VERSION ""

NS_ :

BS_:

BU_:

BO_ 173 Message1099_PDU: 48 Vector__XXX
 SG_ Sig5671 : 7|32@0+ (1,0) [0|4.29497e+009] "" FCM
 SG_ Sig5670 : 39|5@0+ (1,0) [0|31] "" FCM
 SG_ Sig5772 : 45|11@0+ (1,0) [0|2047] "ms" FCM
 SG_ Sig5669 : 47|2@0+ (1,0) [0|3] "" FCM
 SG_ Sig5774 : 49|2@0+ (1,0) [0|3] "" FCM
 SG_ Sig5773 : 50|1@0+ (1,0) [0|1] "" FCM
 SG_ Sig5858 : 57|3@0+ (1,0) [0|4] "" FCM
 SG_ Sig5857 : 59|2@0+ (1,0) [0|3] "" FCM
 SG_ Sig5856 : 61|2@0+ (1,0) [0|2] "" FCM
 SG_ Sig5775 : 63|2@0+ (1,0) [0|2] "" FCM
 SG_ Sig5859 : 70|7@0+ (1,0) [0|127] "" FCM
 SG_ Sig5861 : 73|2@0+ (1,0) [0|3] "" FCM
 SG_ Sig5860 : 79|6@0+ (2,0) [0|126] "%" FCM
 SG_ Sig5862 : 87|9@0- (0.125,0) [-32|31.875] "m/s^2" FCM
 SG_ Sig5863 : 94|10@0- (0.125,0) [-64|63.875] "m" FCM
 SG_ Sig5864 : 100|9@0- (0.125,0) [-32|31.875] "m/s" FCM
 SG_ Sig5865 : 107|9@0- (0.125,0) [-32|31.875] "m/s^2" FCM
 SG_ Sig5866 : 114|11@0- (0.125,0) [-128|127.875] "m" FCM
 SG_ Sig5867 : 135|10@0- (0.125,0) [-64|63.875] "m/s" FCM
 SG_ Sig5870 : 137|2@0+ (1,0) [0|3] "" FCM
 SG_ Sig5869 : 139|2@0+ (1,0) [0|3] "" FCM
 SG_ Sig5868 : 141|2@0+ (1,0) [0|2] "" FCM
 SG_ Sig5872 : 148|7@0+ (1,0) [0|127] "" FCM
 SG_ Sig5871 : 151|3@0+ (1,0) [0|4] "" FCM
 SG_ Sig5873 : 157|6@0+ (2,0) [0|126] "%" FCM
 SG_ Sig5875 : 165|9@0- (0.125,0) [-32|31.875] "m/s^2" FCM
 SG_ Sig5874 : 167|2@0+ (1,0) [0|3] "" FCM
 SG_ Sig5876 : 172|10@0- (0.125,0) [-64|63.875] "m" FCM
 SG_ Sig5877 : 178|9@0- (0.125,0) [-32|31.875] "m/s" FCM
 SG_ Sig5878 : 185|9@0- (0.125,0) [-32|31.875] "m/s^2" FCM
 SG_ Sig5879 : 192|11@0- (0.125,0) [-128|127.875] "m" FCM
 SG_ Sig5880 : 213|10@0- (0.125,0) [-64|63.875] "m/s" FCM
 SG_ Sig5882 : 217|2@0+ (1,0) [0|3] "" FCM
 SG_ Sig5881 : 219|2@0+ (1,0) [0|2] "" FCM
 SG_ Sig5954 : 224|1@0+ (1,0) [0|1] "" FCM
 SG_ Sig5953 : 225|1@0+ (1,0) [0|1] "" FCM
 SG_ Sig5952 : 226|1@0+ (1,0) [0|1] "" FCM
 SG_ Sig5950 : 228|2@0+ (1,0) [0|3] "" FCM
 SG_ Sig5949 : 231|3@0+ (1,0) [0|5] "" FCM
 SG_ Sig5976 : 237|6@0+ (2,0) [0|126] "%" FCM
 SG_ Sig5955 : 239|2@0+ (1,0) [0|3] "" FCM
 SG_ Sig5980 : 241|7@0+ (1,0) [0|127] "" FCM
 SG_ Sig5979 : 242|1@0+ (1,0) [0|1] "" FCM
 SG_ Sig5978 : 245|3@0+ (1,0) [0|4] "" FCM
 SG_ Sig5977 : 247|2@0+ (1,0) [0|3] "" FCM
 SG_ Sig5984 : 248|9@0- (0.125,0) [-32|31.875] "m/s^2" FCM
 SG_ Sig5981 : 250|2@0+ (1,0) [0|3] "" FCM
 SG_ Sig5985 : 271|10@0- (0.125,0) [-64|63.875] "m" FCM
 SG_ Sig5986 : 277|14@0+ (0.01,0) [0|163.83] "m^2" FCM
 SG_ Sig5987 : 295|9@0- (0.125,0) [-32|31.875] "m/s" FCM
 SG_ Sig5988 : 302|10@0+ (0.125,0) [0|127.875] "(m/s)^2" FCM
 SG_ Sig5989 : 308|9@0- (0.125,0) [-32|31.875] "m/s^2" FCM
 SG_ Sig5990 : 315|11@0- (0.125,0) [-128|127.875] "m" FCM
 SG_ Sig5991 : 320|16@0+ (0.01,0) [0|655.35] "m^2" FCM
 SG_ Sig5992 : 336|11@0- (0.125,0) [-128|127.875] "m/s" FCM
 SG_ Sig5993 : 357|10@0+ (0.125,0) [0|127.875] "(m/s)^2" FCM
 SG_ Sig5994 : 363|8@0+ (0.125,0) [0|31.875] "m" FCM
 SG_ Sig6014 : 369|8@0+ (0.125,0) [0|31.875] "m" FCM
 SG_ Sig5995 : 371|2@0+ (1,0) [0|3] "" FCM
 SG_ Sig5668 : 377|2@0+ (1,0) [0|3] "" FCM

BO_ 166 Message1100_PDU: 48 Vector__XXX
 SG_ Sig5681 : 5|32@0+ (1,0) [0|4.29497e+009] "" FCM
 SG_ Sig5680 : 7|2@0+ (1,0) [0|3] "" FCM
 SG_ Sig5682 : 37|10@0+ (1,0) [0|1023] "" FCM
 SG_ Sig5780 : 43|10@0- (0.125,0) [-64|63.875] "m" FCM
 SG_ Sig5788 : 49|10@0- (0.125,0) [-64|63.875] "m" FCM
 SG_ Sig5796 : 71|10@0- (0.125,0) [-64|63.875] "m" FCM
 SG_ Sig5804 : 77|10@0- (0.125,0) [-64|63.875] "m" FCM
 SG_ Sig5812 : 83|10@0- (0.125,0) [-64|63.875] "m" FCM
 SG_ Sig5820 : 89|10@0- (0.125,0) [-64|63.875] "m" FCM
 SG_ Sig5828 : 111|10@0- (0.125,0) [-64|63.875] "m" FCM
 SG_ Sig5836 : 117|10@0- (0.125,0) [-64|63.875] "m" FCM
 SG_ Sig5844 : 123|10@0- (0.125,0) [-64|63.875] "m" FCM
 SG_ Sig5852 : 129|10@0- (0.125,0) [-64|63.875] "m" FCM
 SG_ Sig5923 : 149|16@0- (9.77e-07,0) [-0.0320143|0.0320134] "1/m" FCM
 SG_ Sig5922 : 151|2@0+ (1,0) [0|3] "" FCM
 SG_ Sig5924 : 165|16@0- (3.73e-09,0) [-0.000122225|0.000122221] "1/m2" FCM
 SG_ Sig5925 : 181|10@0- (0.000977,0) [-0.500224|0.499247] "rad" FCM
 SG_ Sig5926 : 187|9@0- (0.125,0) [-32|31.875] "m" FCM
 SG_ Sig5927 : 194|11@0- (0.125,0) [-128|127.875] "m" FCM
 SG_ Sig5928 : 215|11@0- (0.125,0) [-128|127.875] "m" FCM
 SG_ Sig5930 : 217|2@0+ (1,0) [0|3] "" FCM
 SG_ Sig5929 : 220|3@0+ (1,0) [0|5] "" FCM
 SG_ Sig5932 : 229|16@0- (9.77e-07,0) [-0.0320143|0.0320134] "1/m" FCM
 SG_ Sig5931 : 231|2@0+ (1,0) [0|3] "" FCM
 SG_ Sig5933 : 245|16@0- (3.73e-09,0) [-0.000122225|0.000122221] "1/m2" FCM
 SG_ Sig5934 : 261|10@0- (0.000977,0) [-0.500224|0.499247] "rad" FCM
 SG_ Sig5935 : 267|9@0- (0.125,0) [-32|31.875] "m" FCM
 SG_ Sig5936 : 274|11@0- (0.125,0) [-128|127.875] "m" FCM
 SG_ Sig5937 : 295|11@0- (0.125,0) [-128|127.875] "m" FCM
 SG_ Sig5939 : 297|2@0+ (1,0) [0|3] "" FCM
 SG_ Sig5938 : 300|3@0+ (1,0) [0|5] "" FCM
 SG_ Sig5941 : 309|16@0- (9.77e-07,0) [-0.0320143|0.0320134] "1/m" FCM
 SG_ Sig5940 : 311|2@0+ (1,0) [0|3] "" FCM
 SG_ Sig5942 : 325|16@0- (3.73e-09,0) [-0.000122225|0.000122221] "1/m2" FCM
 SG_ Sig5943 : 341|10@0- (0.000977,0) [-0.500224|0.499247] "rad" FCM
 SG_ Sig5944 : 347|9@0- (0.125,0) [-32|31.875] "m" FCM
 SG_ Sig5945 : 354|11@0- (0.125,0) [-128|127.875] "m" FCM
 SG_ Sig5946 : 375|11@0- (0.125,0) [-128|127.875] "m" FCM
 SG_ Sig5948 : 377|2@0+ (1,0) [0|3] "" FCM
 SG_ Sig5947 : 380|3@0+ (1,0) [0|5] "" FCM

BO_ 539 Message1101_PDU: 8 Vector__XXX
 SG_ Sig6851 : 7|64@0+ (1,0) [0|1.84467e+019] "" FCM

BO_ 163 Message1102_PDU: 64 Vector__XXX
 SG_ Sig5688 : 5|8@0+ (1,0) [0|255] "" FCM
 SG_ Sig5687 : 7|2@0+ (1,0) [0|3] "" FCM
 SG_ Sig6318 : 8|7@0+ (1,0) [0|127] "" FCM
 SG_ Sig6317 : 11|3@0+ (1,0) [0|4] "" FCM
 SG_ Sig6316 : 13|2@0+ (1,0) [0|3] "" FCM
 SG_ Sig6319 : 17|6@0+ (2,0) [0|126] "%" FCM
 SG_ Sig6321 : 25|9@0- (0.125,0) [-32|31.875] "m/s^2" FCM
 SG_ Sig6320 : 27|2@0+ (1,0) [0|3] "" FCM
 SG_ Sig6322 : 32|10@0- (0.125,0) [-64|63.875] "m" FCM
 SG_ Sig6323 : 54|9@0- (0.125,0) [-32|31.875] "m/s" FCM
 SG_ Sig6324 : 61|9@0- (0.125,0) [-32|31.875] "m/s^2" FCM
 SG_ Sig6325 : 68|11@0- (0.125,0) [-128|127.875] "m" FCM
 SG_ Sig6326 : 73|10@0- (0.125,0) [-64|63.875] "m/s" FCM
 SG_ Sig6467 : 91|6@0+ (2,0) [0|126] "%" FCM
 SG_ Sig6328 : 93|2@0+ (1,0) [0|3] "" FCM
 SG_ Sig6327 : 95|2@0+ (1,0) [0|2] "" FCM
 SG_ Sig6470 : 96|1@0+ (1,0) [0|1] "" FCM
 SG_ Sig6469 : 99|3@0+ (1,0) [0|4] "" FCM
 SG_ Sig6468 : 101|2@0+ (1,0) [0|3] "" FCM
 SG_ Sig6472 : 104|2@0+ (1,0) [0|3] "" FCM
 SG_ Sig6471 : 111|7@0+ (1,0) [0|127] "" FCM
 SG_ Sig6475 : 118|9@0- (0.125,0) [-32|31.875] "m/s^2" FCM
 SG_ Sig6476 : 125|10@0- (0.125,0) [-64|63.875] "m" FCM
 SG_ Sig6477 : 131|14@0+ (0.01,0) [0|163.83] "m^2" FCM
 SG_ Sig6478 : 149|9@0- (0.125,0) [-32|31.875] "m/s" FCM
 SG_ Sig6479 : 156|10@0+ (0.125,0) [0|127.875] "(m/s)^2" FCM
 SG_ Sig6480 : 162|9@0- (0.125,0) [-32|31.875] "m/s^2" FCM
 SG_ Sig6481 : 169|11@0- (0.125,0) [-128|127.875] "m" FCM
 SG_ Sig6482 : 190|16@0+ (0.01,0) [0|655.35] "m^2" FCM
 SG_ Sig6483 : 206|11@0- (0.125,0) [-128|127.875] "m/s" FCM
 SG_ Sig6484 : 211|10@0+ (0.125,0) [0|127.875] "(m/s)^2" FCM
 SG_ Sig6486 : 217|2@0+ (1,0) [0|3] "" FCM
 SG_ Sig6488 : 225|2@0+ (1,0) [0|3] "" FCM
 SG_ Sig6487 : 231|6@0+ (2,0) [0|126] "%" FCM
 SG_ Sig6491 : 235|7@0+ (1,0) [0|127] "" FCM
 SG_ Sig6490 : 236|1@0+ (1,0) [0|1] "" FCM
 SG_ Sig6489 : 239|3@0+ (1,0) [0|4] "" FCM
 SG_ Sig6495 : 242|9@0- (0.125,0) [-32|31.875] "m/s^2" FCM
 SG_ Sig6492 : 244|2@0+ (1,0) [0|3] "" FCM
 SG_ Sig6496 : 249|10@0- (0.125,0) [-64|63.875] "m" FCM
 SG_ Sig6497 : 271|14@0+ (0.01,0) [0|163.83] "m^2" FCM
 SG_ Sig6498 : 273|9@0- (0.125,0) [-32|31.875] "m/s" FCM
 SG_ Sig6499 : 280|10@0+ (0.125,0) [0|127.875] "(m/s)^2" FCM
 SG_ Sig6500 : 302|9@0- (0.125,0) [-32|31.875] "m/s^2" FCM
 SG_ Sig6501 : 309|11@0- (0.125,0) [-128|127.875] "m" FCM
 SG_ Sig6502 : 314|16@0+ (0.01,0) [0|655.35] "m^2" FCM
 SG_ Sig6503 : 330|11@0- (0.125,0) [-128|127.875] "m/s" FCM
 SG_ Sig6504 : 351|10@0+ (0.125,0) [0|127.875] "(m/s)^2" FCM
 SG_ Sig6505 : 357|8@0+ (0.125,0) [0|31.875] "m" FCM
 SG_ Sig6507 : 363|6@0+ (2,0) [0|126] "%" FCM
 SG_ Sig6506 : 365|2@0+ (1,0) [0|3] "" FCM
 SG_ Sig6510 : 368|1@0+ (1,0) [0|1] "" FCM
 SG_ Sig6509 : 371|3@0+ (1,0) [0|4] "" FCM
 SG_ Sig6508 : 373|2@0+ (1,0) [0|3] "" FCM
 SG_ Sig6512 : 376|2@0+ (1,0) [0|3] "" FCM
 SG_ Sig6511 : 383|7@0+ (1,0) [0|127] "" FCM
 SG_ Sig6515 : 390|9@0- (0.125,0) [-32|31.875] "m/s^2" FCM
 SG_ Sig6516 : 397|10@0- (0.125,0) [-64|63.875] "m" FCM
 SG_ Sig6517 : 403|14@0+ (0.01,0) [0|163.83] "m^2" FCM
 SG_ Sig6518 : 421|9@0- (0.125,0) [-32|31.875] "m/s" FCM
 SG_ Sig6519 : 428|10@0+ (0.125,0) [0|127.875] "(m/s)^2" FCM
 SG_ Sig6520 : 434|9@0- (0.125,0) [-32|31.875] "m/s^2" FCM
 SG_ Sig6521 : 441|11@0- (0.125,0) [-128|127.875] "m" FCM
 SG_ Sig6522 : 462|16@0+ (0.01,0) [0|655.35] "m^2" FCM
 SG_ Sig6523 : 478|11@0- (0.125,0) [-128|127.875] "m/s" FCM
 SG_ Sig6524 : 483|10@0+ (0.125,0) [0|127.875] "(m/s)^2" FCM
 SG_ Sig6525 : 489|8@0+ (0.125,0) [0|31.875] "m" FCM
 SG_ Sig6526 : 497|2@0+ (1,0) [0|3] "" FCM
 SG_ Sig6545 : 511|8@0+ (0.125,0) [0|31.875] "m" FCM

BO_ 161 Message1103_PDU: 64 Vector__XXX
 SG_ Sig5690 : 5|8@0+ (1,0) [0|255] "" FCM
 SG_ Sig5689 : 7|2@0+ (1,0) [0|3] "" FCM
 SG_ Sig6331 : 8|7@0+ (1,0) [0|127] "" FCM
 SG_ Sig6330 : 11|3@0+ (1,0) [0|4] "" FCM
 SG_ Sig6329 : 13|2@0+ (1,0) [0|3] "" FCM
 SG_ Sig6332 : 17|6@0+ (2,0) [0|126] "%" FCM
 SG_ Sig6334 : 25|9@0- (0.125,0) [-32|31.875] "m/s^2" FCM
 SG_ Sig6333 : 27|2@0+ (1,0) [0|3] "" FCM
 SG_ Sig6335 : 32|10@0- (0.125,0) [-64|63.875] "m" FCM
 SG_ Sig6336 : 54|9@0- (0.125,0) [-32|31.875] "m/s" FCM
 SG_ Sig6337 : 61|9@0- (0.125,0) [-32|31.875] "m/s^2" FCM
 SG_ Sig6338 : 68|11@0- (0.125,0) [-128|127.875] "m" FCM
 SG_ Sig6339 : 73|10@0- (0.125,0) [-64|63.875] "m/s" FCM
 SG_ Sig6527 : 91|6@0+ (2,0) [0|126] "%" FCM
 SG_ Sig6341 : 93|2@0+ (1,0) [0|3] "" FCM
 SG_ Sig6340 : 95|2@0+ (1,0) [0|2] "" FCM
 SG_ Sig6530 : 96|1@0+ (1,0) [0|1] "" FCM
 SG_ Sig6529 : 99|3@0+ (1,0) [0|4] "" FCM
 SG_ Sig6528 : 101|2@0+ (1,0) [0|3] "" FCM
 SG_ Sig6532 : 104|2@0+ (1,0) [0|3] "" FCM
 SG_ Sig6531 : 111|7@0+ (1,0) [0|127] "" FCM
 SG_ Sig6535 : 118|9@0- (0.125,0) [-32|31.875] "m/s^2" FCM
 SG_ Sig6536 : 125|10@0- (0.125,0) [-64|63.875] "m" FCM
 SG_ Sig6537 : 131|14@0+ (0.01,0) [0|163.83] "m^2" FCM
 SG_ Sig6538 : 149|9@0- (0.125,0) [-32|31.875] "m/s" FCM
 SG_ Sig6539 : 156|10@0+ (0.125,0) [0|127.875] "(m/s)^2" FCM
 SG_ Sig6540 : 162|9@0- (0.125,0) [-32|31.875] "m/s^2" FCM
 SG_ Sig6541 : 169|11@0- (0.125,0) [-128|127.875] "m" FCM
 SG_ Sig6542 : 190|16@0+ (0.01,0) [0|655.35] "m^2" FCM
 SG_ Sig6543 : 206|11@0- (0.125,0) [-128|127.875] "m/s" FCM
 SG_ Sig6544 : 211|10@0+ (0.125,0) [0|127.875] "(m/s)^2" FCM
 SG_ Sig6546 : 217|2@0+ (1,0) [0|3] "" FCM
 SG_ Sig6548 : 225|2@0+ (1,0) [0|3] "" FCM
 SG_ Sig6547 : 231|6@0+ (2,0) [0|126] "%" FCM
 SG_ Sig6551 : 235|7@0+ (1,0) [0|127] "" FCM
 SG_ Sig6550 : 236|1@0+ (1,0) [0|1] "" FCM
 SG_ Sig6549 : 239|3@0+ (1,0) [0|4] "" FCM
 SG_ Sig6555 : 242|9@0- (0.125,0) [-32|31.875] "m/s^2" FCM
 SG_ Sig6552 : 244|2@0+ (1,0) [0|3] "" FCM
 SG_ Sig6556 : 249|10@0- (0.125,0) [-64|63.875] "m" FCM
 SG_ Sig6557 : 271|14@0+ (0.01,0) [0|163.83] "m^2" FCM
 SG_ Sig6558 : 273|9@0- (0.125,0) [-32|31.875] "m/s" FCM
 SG_ Sig6559 : 280|10@0+ (0.125,0) [0|127.875] "(m/s)^2" FCM
 SG_ Sig6560 : 302|9@0- (0.125,0) [-32|31.875] "m/s^2" FCM
 SG_ Sig6561 : 309|11@0- (0.125,0) [-128|127.875] "m" FCM
 SG_ Sig6562 : 314|16@0+ (0.01,0) [0|655.35] "m^2" FCM
 SG_ Sig6563 : 330|11@0- (0.125,0) [-128|127.875] "m/s" FCM
 SG_ Sig6564 : 351|10@0+ (0.125,0) [0|127.875] "(m/s)^2" FCM
 SG_ Sig6565 : 357|8@0+ (0.125,0) [0|31.875] "m" FCM
 SG_ Sig6567 : 363|6@0+ (2,0) [0|126] "%" FCM
 SG_ Sig6566 : 365|2@0+ (1,0) [0|3] "" FCM
 SG_ Sig6570 : 368|1@0+ (1,0) [0|1] "" FCM
 SG_ Sig6569 : 371|3@0+ (1,0) [0|4] "" FCM
 SG_ Sig6568 : 373|2@0+ (1,0) [0|3] "" FCM
 SG_ Sig6572 : 376|2@0+ (1,0) [0|3] "" FCM
 SG_ Sig6571 : 383|7@0+ (1,0) [0|127] "" FCM
 SG_ Sig6575 : 390|9@0- (0.125,0) [-32|31.875] "m/s^2" FCM
 SG_ Sig6576 : 397|10@0- (0.125,0) [-64|63.875] "m" FCM
 SG_ Sig6577 : 403|14@0+ (0.01,0) [0|163.83] "m^2" FCM
 SG_ Sig6578 : 421|9@0- (0.125,0) [-32|31.875] "m/s" FCM
 SG_ Sig6579 : 428|10@0+ (0.125,0) [0|127.875] "(m/s)^2" FCM
 SG_ Sig6580 : 434|9@0- (0.125,0) [-32|31.875] "m/s^2" FCM
 SG_ Sig6581 : 441|11@0- (0.125,0) [-128|127.875] "m" FCM
 SG_ Sig6582 : 462|16@0+ (0.01,0) [0|655.35] "m^2" FCM
 SG_ Sig6583 : 478|11@0- (0.125,0) [-128|127.875] "m/s" FCM
 SG_ Sig6584 : 483|10@0+ (0.125,0) [0|127.875] "(m/s)^2" FCM
 SG_ Sig6585 : 489|8@0+ (0.125,0) [0|31.875] "m" FCM
 SG_ Sig6586 : 497|2@0+ (1,0) [0|3] "" FCM
 SG_ Sig6605 : 511|8@0+ (0.125,0) [0|31.875] "m" FCM

BO_ 160 Message1104_PDU: 64 Vector__XXX
 SG_ Sig5692 : 5|16@0+ (1,0) [0|65535] "" FCM
 SG_ Sig5691 : 7|2@0+ (1,0) [0|3] "" FCM
 SG_ Sig6344 : 16|7@0+ (1,0) [0|127] "" FCM
 SG_ Sig6343 : 19|3@0+ (1,0) [0|4] "" FCM
 SG_ Sig6342 : 21|2@0+ (1,0) [0|3] "" FCM
 SG_ Sig6345 : 25|6@0+ (2,0) [0|126] "%" FCM
 SG_ Sig6347 : 33|9@0- (0.125,0) [-32|31.875] "m/s^2" FCM
 SG_ Sig6346 : 35|2@0+ (1,0) [0|3] "" FCM
 SG_ Sig6348 : 40|10@0- (0.125,0) [-64|63.875] "m" FCM
 SG_ Sig6349 : 62|9@0- (0.125,0) [-32|31.875] "m/s" FCM
 SG_ Sig6350 : 69|9@0- (0.125,0) [-32|31.875] "m/s^2" FCM
 SG_ Sig6351 : 76|11@0- (0.125,0) [-128|127.875] "m" FCM
 SG_ Sig6352 : 81|10@0- (0.125,0) [-64|63.875] "m/s" FCM
 SG_ Sig6427 : 99|6@0+ (2,0) [0|126] "%" FCM
 SG_ Sig6354 : 101|2@0+ (1,0) [0|3] "" FCM
 SG_ Sig6353 : 103|2@0+ (1,0) [0|2] "" FCM
 SG_ Sig6430 : 104|1@0+ (1,0) [0|1] "" FCM
 SG_ Sig6429 : 107|3@0+ (1,0) [0|4] "" FCM
 SG_ Sig6428 : 109|2@0+ (1,0) [0|3] "" FCM
 SG_ Sig6432 : 112|2@0+ (1,0) [0|3] "" FCM
 SG_ Sig6431 : 119|7@0+ (1,0) [0|127] "" FCM
 SG_ Sig6435 : 126|9@0- (0.125,0) [-32|31.875] "m/s^2" FCM
 SG_ Sig6436 : 133|10@0- (0.125,0) [-64|63.875] "m" FCM
 SG_ Sig6437 : 139|14@0+ (0.01,0) [0|163.83] "m^2" FCM
 SG_ Sig6438 : 157|9@0- (0.125,0) [-32|31.875] "m/s" FCM
 SG_ Sig6439 : 164|10@0+ (0.125,0) [0|127.875] "(m/s)^2" FCM
 SG_ Sig6440 : 170|9@0- (0.125,0) [-32|31.875] "m/s^2" FCM
 SG_ Sig6441 : 177|11@0- (0.125,0) [-128|127.875] "m" FCM
 SG_ Sig6442 : 198|16@0+ (0.01,0) [0|655.35] "m^2" FCM
 SG_ Sig6443 : 214|11@0- (0.125,0) [-128|127.875] "m/s" FCM
 SG_ Sig6444 : 219|10@0+ (0.125,0) [0|127.875] "(m/s)^2" FCM
 SG_ Sig6445 : 225|8@0+ (0.125,0) [0|31.875] "m" FCM
 SG_ Sig6446 : 233|2@0+ (1,0) [0|3] "" FCM
 SG_ Sig6588 : 241|2@0+ (1,0) [0|3] "" FCM
 SG_ Sig6587 : 247|6@0+ (2,0) [0|126] "%" FCM
 SG_ Sig6591 : 251|7@0+ (1,0) [0|127] "" FCM
 SG_ Sig6590 : 252|1@0+ (1,0) [0|1] "" FCM
 SG_ Sig6589 : 255|3@0+ (1,0) [0|4] "" FCM
 SG_ Sig6595 : 258|9@0- (0.125,0) [-32|31.875] "m/s^2" FCM
 SG_ Sig6592 : 260|2@0+ (1,0) [0|3] "" FCM
 SG_ Sig6596 : 265|10@0- (0.125,0) [-64|63.875] "m" FCM
 SG_ Sig6597 : 287|14@0+ (0.01,0) [0|163.83] "m^2" FCM
 SG_ Sig6598 : 289|9@0- (0.125,0) [-32|31.875] "m/s" FCM
 SG_ Sig6599 : 296|10@0+ (0.125,0) [0|127.875] "(m/s)^2" FCM
 SG_ Sig6600 : 318|9@0- (0.125,0) [-32|31.875] "m/s^2" FCM
 SG_ Sig6601 : 325|11@0- (0.125,0) [-128|127.875] "m" FCM
 SG_ Sig6602 : 330|16@0+ (0.01,0) [0|655.35] "m^2" FCM
 SG_ Sig6603 : 346|11@0- (0.125,0) [-128|127.875] "m/s" FCM
 SG_ Sig6604 : 367|10@0+ (0.125,0) [0|127.875] "(m/s)^2" FCM
 SG_ Sig6607 : 371|6@0+ (2,0) [0|126] "%" FCM
 SG_ Sig6606 : 373|2@0+ (1,0) [0|3] "" FCM
 SG_ Sig6610 : 376|1@0+ (1,0) [0|1] "" FCM
 SG_ Sig6609 : 379|3@0+ (1,0) [0|4] "" FCM
 SG_ Sig6608 : 381|2@0+ (1,0) [0|3] "" FCM
 SG_ Sig6612 : 384|2@0+ (1,0) [0|3] "" FCM
 SG_ Sig6611 : 391|7@0+ (1,0) [0|127] "" FCM
 SG_ Sig6615 : 398|9@0- (0.125,0) [-32|31.875] "m/s^2" FCM
 SG_ Sig6616 : 405|10@0- (0.125,0) [-64|63.875] "m" FCM
 SG_ Sig6617 : 411|14@0+ (0.01,0) [0|163.83] "m^2" FCM
 SG_ Sig6618 : 429|9@0- (0.125,0) [-32|31.875] "m/s" FCM
 SG_ Sig6619 : 436|10@0+ (0.125,0) [0|127.875] "(m/s)^2" FCM
 SG_ Sig6620 : 442|9@0- (0.125,0) [-32|31.875] "m/s^2" FCM
 SG_ Sig6621 : 449|11@0- (0.125,0) [-128|127.875] "m" FCM
 SG_ Sig6622 : 470|16@0+ (0.01,0) [0|655.35] "m^2" FCM
 SG_ Sig6623 : 486|11@0- (0.125,0) [-128|127.875] "m/s" FCM
 SG_ Sig6624 : 491|10@0+ (0.125,0) [0|127.875] "(m/s)^2" FCM
 SG_ Sig6625 : 497|8@0+ (0.125,0) [0|31.875] "m" FCM
 SG_ Sig6626 : 505|2@0+ (1,0) [0|3] "" FCM

BO_ 159 Message1105_PDU: 64 Vector__XXX
 SG_ Sig5694 : 5|10@0+ (1,0) [0|1023] "" FCM
 SG_ Sig5693 : 7|2@0+ (1,0) [0|3] "" FCM
 SG_ Sig6206 : 9|2@0+ (1,0) [0|3] "" FCM
 SG_ Sig6205 : 11|2@0+ (1,0) [0|3] "" FCM
 SG_ Sig6208 : 16|2@0+ (1,0) [0|3] "" FCM
 SG_ Sig6207 : 23|7@0+ (1,0) [0|127] "" FCM
 SG_ Sig6210 : 30|11@0- (0.125,0) [-128|127.875] "m" FCM
 SG_ Sig6212 : 32|2@0+ (1,0) [0|3] "" FCM
 SG_ Sig6211 : 35|3@0+ (1,0) [0|5] "" FCM
 SG_ Sig6215 : 42|7@0+ (1,0) [0|127] "" FCM
 SG_ Sig6214 : 44|2@0+ (1,0) [0|3] "" FCM
 SG_ Sig6213 : 46|2@0+ (1,0) [0|3] "" FCM
 SG_ Sig6218 : 49|11@0- (0.125,0) [-128|127.875] "m" FCM
 SG_ Sig6216 : 51|2@0+ (1,0) [0|3] "" FCM
 SG_ Sig6221 : 65|2@0+ (1,0) [0|3] "" FCM
 SG_ Sig6220 : 67|2@0+ (1,0) [0|3] "" FCM
 SG_ Sig6219 : 70|3@0+ (1,0) [0|5] "" FCM
 SG_ Sig6223 : 77|7@0+ (1,0) [0|127] "" FCM
 SG_ Sig6222 : 79|2@0+ (1,0) [0|3] "" FCM
 SG_ Sig6226 : 84|11@0- (0.125,0) [-128|127.875] "m" FCM
 SG_ Sig6224 : 86|2@0+ (1,0) [0|3] "" FCM
 SG_ Sig6227 : 89|3@0+ (1,0) [0|5] "" FCM
 SG_ Sig6231 : 96|7@0+ (1,0) [0|127] "" FCM
 SG_ Sig6230 : 98|2@0+ (1,0) [0|3] "" FCM
 SG_ Sig6229 : 100|2@0+ (1,0) [0|3] "" FCM
 SG_ Sig6228 : 102|2@0+ (1,0) [0|3] "" FCM
 SG_ Sig6232 : 105|2@0+ (1,0) [0|3] "" FCM
 SG_ Sig6234 : 119|11@0- (0.125,0) [-128|127.875] "m" FCM
 SG_ Sig6236 : 121|2@0+ (1,0) [0|3] "" FCM
 SG_ Sig6235 : 124|3@0+ (1,0) [0|5] "" FCM
 SG_ Sig6239 : 131|7@0+ (1,0) [0|127] "" FCM
 SG_ Sig6238 : 133|2@0+ (1,0) [0|3] "" FCM
 SG_ Sig6237 : 135|2@0+ (1,0) [0|3] "" FCM
 SG_ Sig6242 : 138|11@0- (0.125,0) [-128|127.875] "m" FCM
 SG_ Sig6240 : 140|2@0+ (1,0) [0|3] "" FCM
 SG_ Sig6246 : 152|2@0+ (1,0) [0|3] "" FCM
 SG_ Sig6245 : 154|2@0+ (1,0) [0|3] "" FCM
 SG_ Sig6244 : 156|2@0+ (1,0) [0|3] "" FCM
 SG_ Sig6243 : 159|3@0+ (1,0) [0|5] "" FCM
 SG_ Sig6247 : 166|7@0+ (1,0) [0|127] "" FCM
 SG_ Sig6250 : 173|11@0- (0.125,0) [-128|127.875] "m" FCM
 SG_ Sig6248 : 175|2@0+ (1,0) [0|3] "" FCM
 SG_ Sig6251 : 178|3@0+ (1,0) [0|5] "" FCM
 SG_ Sig6255 : 185|7@0+ (1,0) [0|127] "" FCM
 SG_ Sig6254 : 187|2@0+ (1,0) [0|3] "" FCM
 SG_ Sig6253 : 189|2@0+ (1,0) [0|3] "" FCM
 SG_ Sig6252 : 191|2@0+ (1,0) [0|3] "" FCM
 SG_ Sig6258 : 192|11@0- (0.125,0) [-128|127.875] "m" FCM
 SG_ Sig6256 : 194|2@0+ (1,0) [0|3] "" FCM
 SG_ Sig6261 : 208|2@0+ (1,0) [0|3] "" FCM
 SG_ Sig6260 : 210|2@0+ (1,0) [0|3] "" FCM
 SG_ Sig6259 : 213|3@0+ (1,0) [0|5] "" FCM
 SG_ Sig6263 : 220|7@0+ (1,0) [0|127] "" FCM
 SG_ Sig6262 : 222|2@0+ (1,0) [0|3] "" FCM
 SG_ Sig6266 : 227|11@0- (0.125,0) [-128|127.875] "m" FCM
 SG_ Sig6264 : 229|2@0+ (1,0) [0|3] "" FCM
 SG_ Sig6267 : 232|3@0+ (1,0) [0|5] "" FCM
 SG_ Sig6270 : 241|2@0+ (1,0) [0|3] "" FCM
 SG_ Sig6269 : 243|2@0+ (1,0) [0|3] "" FCM
 SG_ Sig6268 : 245|2@0+ (1,0) [0|3] "" FCM
 SG_ Sig6272 : 248|2@0+ (1,0) [0|3] "" FCM
 SG_ Sig6271 : 255|7@0+ (1,0) [0|127] "" FCM
 SG_ Sig6274 : 262|11@0- (0.125,0) [-128|127.875] "m" FCM
 SG_ Sig6276 : 264|2@0+ (1,0) [0|3] "" FCM
 SG_ Sig6275 : 267|3@0+ (1,0) [0|5] "" FCM
 SG_ Sig6279 : 274|7@0+ (1,0) [0|127] "" FCM
 SG_ Sig6278 : 276|2@0+ (1,0) [0|3] "" FCM
 SG_ Sig6277 : 278|2@0+ (1,0) [0|3] "" FCM
 SG_ Sig6282 : 281|11@0- (0.125,0) [-128|127.875] "m" FCM
 SG_ Sig6280 : 283|2@0+ (1,0) [0|3] "" FCM
 SG_ Sig6433 : 297|10@0- (0.125,0) [-64|63.875] "m" FCM
 SG_ Sig6284 : 299|2@0+ (1,0) [0|3] "" FCM
 SG_ Sig6283 : 302|3@0+ (1,0) [0|5] "" FCM
 SG_ Sig6434 : 319|11@0- (0.125,0) [-128|127.875] "m" FCM
 SG_ Sig6453 : 324|10@0- (0.125,0) [-64|63.875] "m" FCM
 SG_ Sig6454 : 330|11@0- (0.125,0) [-128|127.875] "m" FCM
 SG_ Sig6473 : 351|10@0- (0.125,0) [-64|63.875] "m" FCM
 SG_ Sig6474 : 357|11@0- (0.125,0) [-128|127.875] "m" FCM
 SG_ Sig6493 : 362|10@0- (0.125,0) [-64|63.875] "m" FCM
 SG_ Sig6494 : 368|11@0- (0.125,0) [-128|127.875] "m" FCM
 SG_ Sig6513 : 389|10@0- (0.125,0) [-64|63.875] "m" FCM
 SG_ Sig6514 : 395|11@0- (0.125,0) [-128|127.875] "m" FCM
 SG_ Sig6533 : 400|10@0- (0.125,0) [-64|63.875] "m" FCM
 SG_ Sig6534 : 422|11@0- (0.125,0) [-128|127.875] "m" FCM
 SG_ Sig6553 : 427|10@0- (0.125,0) [-64|63.875] "m" FCM
 SG_ Sig6554 : 433|11@0- (0.125,0) [-128|127.875] "m" FCM
 SG_ Sig6573 : 454|10@0- (0.125,0) [-64|63.875] "m" FCM
 SG_ Sig6574 : 460|11@0- (0.125,0) [-128|127.875] "m" FCM
 SG_ Sig6593 : 465|10@0- (0.125,0) [-64|63.875] "m" FCM
 SG_ Sig6594 : 487|11@0- (0.125,0) [-128|127.875] "m" FCM
 SG_ Sig6613 : 492|10@0- (0.125,0) [-64|63.875] "m" FCM
 SG_ Sig6614 : 498|11@0- (0.125,0) [-128|127.875] "m" FCM

BO_ 165 Message1106_PDU: 48 Vector__XXX
 SG_ Sig5686 : 7|32@0+ (1,0) [0|4.29497e+009] "" FCM
 SG_ Sig5685 : 39|5@0+ (1,0) [0|31] "" FCM
 SG_ Sig6200 : 45|11@0+ (1,0) [0|2047] "ms" FCM
 SG_ Sig5684 : 47|2@0+ (1,0) [0|3] "" FCM
 SG_ Sig6202 : 49|2@0+ (1,0) [0|3] "" FCM
 SG_ Sig6201 : 50|1@0+ (1,0) [0|1] "" FCM
 SG_ Sig6291 : 57|3@0+ (1,0) [0|4] "" FCM
 SG_ Sig6290 : 59|2@0+ (1,0) [0|3] "" FCM
 SG_ Sig6285 : 61|2@0+ (1,0) [0|2] "" FCM
 SG_ Sig6203 : 63|2@0+ (1,0) [0|2] "" FCM
 SG_ Sig6292 : 70|7@0+ (1,0) [0|127] "" FCM
 SG_ Sig6294 : 73|2@0+ (1,0) [0|3] "" FCM
 SG_ Sig6293 : 79|6@0+ (2,0) [0|126] "%" FCM
 SG_ Sig6295 : 87|9@0- (0.125,0) [-32|31.875] "m/s^2" FCM
 SG_ Sig6296 : 94|10@0- (0.125,0) [-64|63.875] "m" FCM
 SG_ Sig6297 : 100|9@0- (0.125,0) [-32|31.875] "m/s" FCM
 SG_ Sig6298 : 107|9@0- (0.125,0) [-32|31.875] "m/s^2" FCM
 SG_ Sig6299 : 114|11@0- (0.125,0) [-128|127.875] "m" FCM
 SG_ Sig6300 : 135|10@0- (0.125,0) [-64|63.875] "m/s" FCM
 SG_ Sig6303 : 137|2@0+ (1,0) [0|3] "" FCM
 SG_ Sig6302 : 139|2@0+ (1,0) [0|3] "" FCM
 SG_ Sig6301 : 141|2@0+ (1,0) [0|2] "" FCM
 SG_ Sig6305 : 148|7@0+ (1,0) [0|127] "" FCM
 SG_ Sig6304 : 151|3@0+ (1,0) [0|4] "" FCM
 SG_ Sig6306 : 157|6@0+ (2,0) [0|126] "%" FCM
 SG_ Sig6308 : 165|9@0- (0.125,0) [-32|31.875] "m/s^2" FCM
 SG_ Sig6307 : 167|2@0+ (1,0) [0|3] "" FCM
 SG_ Sig6309 : 172|10@0- (0.125,0) [-64|63.875] "m" FCM
 SG_ Sig6310 : 178|9@0- (0.125,0) [-32|31.875] "m/s" FCM
 SG_ Sig6311 : 185|9@0- (0.125,0) [-32|31.875] "m/s^2" FCM
 SG_ Sig6312 : 192|11@0- (0.125,0) [-128|127.875] "m" FCM
 SG_ Sig6313 : 213|10@0- (0.125,0) [-64|63.875] "m/s" FCM
 SG_ Sig6315 : 217|2@0+ (1,0) [0|3] "" FCM
 SG_ Sig6314 : 219|2@0+ (1,0) [0|2] "" FCM
 SG_ Sig6387 : 224|1@0+ (1,0) [0|1] "" FCM
 SG_ Sig6386 : 225|1@0+ (1,0) [0|1] "" FCM
 SG_ Sig6385 : 226|1@0+ (1,0) [0|1] "" FCM
 SG_ Sig6383 : 228|2@0+ (1,0) [0|3] "" FCM
 SG_ Sig6382 : 231|3@0+ (1,0) [0|5] "" FCM
 SG_ Sig6447 : 237|6@0+ (2,0) [0|126] "%" FCM
 SG_ Sig6388 : 239|2@0+ (1,0) [0|3] "" FCM
 SG_ Sig6451 : 241|7@0+ (1,0) [0|127] "" FCM
 SG_ Sig6450 : 242|1@0+ (1,0) [0|1] "" FCM
 SG_ Sig6449 : 245|3@0+ (1,0) [0|4] "" FCM
 SG_ Sig6448 : 247|2@0+ (1,0) [0|3] "" FCM
 SG_ Sig6455 : 248|9@0- (0.125,0) [-32|31.875] "m/s^2" FCM
 SG_ Sig6452 : 250|2@0+ (1,0) [0|3] "" FCM
 SG_ Sig6456 : 271|10@0- (0.125,0) [-64|63.875] "m" FCM
 SG_ Sig6457 : 277|14@0+ (0.01,0) [0|163.83] "m^2" FCM
 SG_ Sig6458 : 295|9@0- (0.125,0) [-32|31.875] "m/s" FCM
 SG_ Sig6459 : 302|10@0+ (0.125,0) [0|127.875] "(m/s)^2" FCM
 SG_ Sig6460 : 308|9@0- (0.125,0) [-32|31.875] "m/s^2" FCM
 SG_ Sig6461 : 315|11@0- (0.125,0) [-128|127.875] "m" FCM
 SG_ Sig6462 : 320|16@0+ (0.01,0) [0|655.35] "m^2" FCM
 SG_ Sig6463 : 336|11@0- (0.125,0) [-128|127.875] "m/s" FCM
 SG_ Sig6464 : 357|10@0+ (0.125,0) [0|127.875] "(m/s)^2" FCM
 SG_ Sig6465 : 363|8@0+ (0.125,0) [0|31.875] "m" FCM
 SG_ Sig6485 : 369|8@0+ (0.125,0) [0|31.875] "m" FCM
 SG_ Sig6466 : 371|2@0+ (1,0) [0|3] "" FCM
 SG_ Sig5683 : 377|2@0+ (1,0) [0|3] "" FCM

BO_ 158 Message1107_PDU: 48 Vector__XXX
 SG_ Sig5696 : 5|32@0+ (1,0) [0|4.29497e+009] "" FCM
 SG_ Sig5695 : 7|2@0+ (1,0) [0|3] "" FCM
 SG_ Sig5697 : 37|10@0+ (1,0) [0|1023] "" FCM
 SG_ Sig6209 : 43|10@0- (0.125,0) [-64|63.875] "m" FCM
 SG_ Sig6217 : 49|10@0- (0.125,0) [-64|63.875] "m" FCM
 SG_ Sig6225 : 71|10@0- (0.125,0) [-64|63.875] "m" FCM
 SG_ Sig6233 : 77|10@0- (0.125,0) [-64|63.875] "m" FCM
 SG_ Sig6241 : 83|10@0- (0.125,0) [-64|63.875] "m" FCM
 SG_ Sig6249 : 89|10@0- (0.125,0) [-64|63.875] "m" FCM
 SG_ Sig6257 : 111|10@0- (0.125,0) [-64|63.875] "m" FCM
 SG_ Sig6265 : 117|10@0- (0.125,0) [-64|63.875] "m" FCM
 SG_ Sig6273 : 123|10@0- (0.125,0) [-64|63.875] "m" FCM
 SG_ Sig6281 : 129|10@0- (0.125,0) [-64|63.875] "m" FCM
 SG_ Sig6356 : 149|16@0- (9.77e-07,0) [-0.0320143|0.0320134] "1/m" FCM
 SG_ Sig6355 : 151|2@0+ (1,0) [0|3] "" FCM
 SG_ Sig6357 : 165|16@0- (3.73e-09,0) [-0.000122225|0.000122221] "1/m2" FCM
 SG_ Sig6358 : 181|10@0- (0.000977,0) [-0.500224|0.499247] "rad" FCM
 SG_ Sig6359 : 187|9@0- (0.125,0) [-32|31.875] "m" FCM
 SG_ Sig6360 : 194|11@0- (0.125,0) [-128|127.875] "m" FCM
 SG_ Sig6361 : 215|11@0- (0.125,0) [-128|127.875] "m" FCM
 SG_ Sig6363 : 217|2@0+ (1,0) [0|3] "" FCM
 SG_ Sig6362 : 220|3@0+ (1,0) [0|5] "" FCM
 SG_ Sig6365 : 229|16@0- (9.77e-07,0) [-0.0320143|0.0320134] "1/m" FCM
 SG_ Sig6364 : 231|2@0+ (1,0) [0|3] "" FCM
 SG_ Sig6366 : 245|16@0- (3.73e-09,0) [-0.000122225|0.000122221] "1/m2" FCM
 SG_ Sig6367 : 261|10@0- (0.000977,0) [-0.500224|0.499247] "rad" FCM
 SG_ Sig6368 : 267|9@0- (0.125,0) [-32|31.875] "m" FCM
 SG_ Sig6369 : 274|11@0- (0.125,0) [-128|127.875] "m" FCM
 SG_ Sig6370 : 295|11@0- (0.125,0) [-128|127.875] "m" FCM
 SG_ Sig6372 : 297|2@0+ (1,0) [0|3] "" FCM
 SG_ Sig6371 : 300|3@0+ (1,0) [0|5] "" FCM
 SG_ Sig6374 : 309|16@0- (9.77e-07,0) [-0.0320143|0.0320134] "1/m" FCM
 SG_ Sig6373 : 311|2@0+ (1,0) [0|3] "" FCM
 SG_ Sig6375 : 325|16@0- (3.73e-09,0) [-0.000122225|0.000122221] "1/m2" FCM
 SG_ Sig6376 : 341|10@0- (0.000977,0) [-0.500224|0.499247] "rad" FCM
 SG_ Sig6377 : 347|9@0- (0.125,0) [-32|31.875] "m" FCM
 SG_ Sig6378 : 354|11@0- (0.125,0) [-128|127.875] "m" FCM
 SG_ Sig6379 : 375|11@0- (0.125,0) [-128|127.875] "m" FCM
 SG_ Sig6381 : 377|2@0+ (1,0) [0|3] "" FCM
 SG_ Sig6380 : 380|3@0+ (1,0) [0|5] "" FCM

BO_ 908 SrlDat18_PCSM_PDU: 8 Vector__XXX
 SG_ SrlDat18_PCSM : 7|64@0+ (1,0) [0|1.84467e+019] "" ACP2_MCU,AHL_AFL,EBCM,EOCM,EOCM_HC_Superset,FCM,RDCM,TCCM,TCM

BO_ 100 SrlDat18_Prtctd_PDU: 20 Vector__XXX
 SG_ SD18P_MAC : 7|32@0+ (1,0) [0|4.29497e+009] "" ACP2_MCU,AHL_AFL,CGM,EBCM,EOCM,EOCM_HC_Superset,FCM,RDCM,TCCM,TCM
 SG_ SD18P_FCnt : 39|5@0+ (1,0) [0|31] "" ACP2_MCU,AHL_AFL,CGM,EBCM,EOCM,EOCM_HC_Superset,FCM,RDCM,TCCM,TCM
 SG_ EGI5P_ECDIntlRngSnsrPWAuth : 45|8@0+ (0.392157,0) [0|100] "%" ACP2_MCU,AHL_AFL,CGM,EBCM,EOCM,EOCM_HC_Superset,FCM,RDCM,TCCM,TCM,ECP_X1
 SG_ EGI1P_PtclFiltClnAlgActAuth_DuD : 46|1@0+ (1,0) [0|1] "" ACP2_MCU,AHL_AFL,BSM,CGM,EBCM,EOCM,EOCM_HC_Superset,FCM,RDCM,TCCM,TCM
 SG_ EGI1P_PtclFiltClnAlgActAuth : 47|1@0+ (1,0) [0|1] "" ACP2_MCU,AHL_AFL,BSM,CGM,EBCM,EOCM,EOCM_HC_Superset,FCM,RDCM,TCCM,TCM
 SG_ EGIP_CrksftNTransRegCmdTqAuth : 51|12@0+ (0.5,-848) [-848|1199.5] "Nm" ACP2_MCU,AHL_AFL,CGM,EBCM,EOCM,EOCM_HC_Superset,FCM,RDCM,TCCM,TCM,ECP_X1
 SG_ EGI5P_EngStlSvrActvAuth : 52|1@0+ (1,0) [0|1] "" ACP2_MCU,AHL_AFL,CGM,EBCM,EOCM,EOCM_HC_Superset,FCM,RDCM,TCCM,TCM,ECP_X1
 SG_ EGI5P_ECDIntlRngSnsrPWAuth_Inv : 53|1@0+ (1,0) [0|1] "" ACP2_MCU,AHL_AFL,CGM,EBCM,EOCM,EOCM_HC_Superset,FCM,RDCM,TCCM,TCM,ECP_X1
 SG_ EGIP_DrvrIntndCrksftTrqMinAuth : 71|12@0+ (0.5,-848) [-848|1199.5] "Nm" ACP2_MCU,AHL_AFL,CGM,EBCM,EOCM,EOCM_HC_Superset,FCM,RDCM,TCCM,TCM,ECP_X1
 SG_ EGIP_DrvrIntndCrksftTrqRwAuth : 75|12@0+ (0.5,-848) [-848|1199.5] "Nm" ACP2_MCU,AHL_AFL,CGM,EBCM,EOCM,EOCM_HC_Superset,FCM,RDCM,TCCM,TCM,ECP_X1
 SG_ EGIP_EngActlStdyStatTrqAuth : 95|12@0+ (0.5,-848) [-848|1199.5] "Nm" ACP2_MCU,AHL_AFL,BSM,CGM,DCM,EBCM,EOCM,EOCM_HC_Superset,FCM,RDCM,TCCM,TCM,ECP_X1
 SG_ EGIP_EngNTransRegSSTrqAuth : 98|12@0+ (0.5,-848) [-848|1199.5] "nm" ACP2_MCU,AHL_AFL,CGM,EBCM,EOCM,EOCM_HC_Superset,FCM,RDCM,TCCM,TCM,ECP_X1
 SG_ EGIP_EngActlStdyStatTrqAuth_Inv : 99|1@0+ (1,0) [0|1] "" ACP2_MCU,AHL_AFL,BSM,CGM,DCM,EBCM,EOCM,EOCM_HC_Superset,FCM,RDCM,TCCM,TCM,ECP_X1
 SG_ ESP_EngSpdAuth : 117|16@0+ (0.25,0) [0|16383.8] "rpm" ACP2_MCU,AHL_AFL,AHS,BSM,VICM,CGM,DCM,EBCM,EOCM,EOCM_HC_Superset,EPS,EPSb,FCM,PCM,RDCM,TCCM,TCM,ECP_X1
 SG_ EGIP_EngNTransRegSSTrqAuth_Inv : 118|1@0+ (1,0) [0|1] "" ACP2_MCU,AHL_AFL,CGM,EBCM,EOCM,EOCM_HC_Superset,FCM,RDCM,TCCM,TCM,ECP_X1
 SG_ SD18P_ARC : 129|2@0+ (1,0) [0|3] "" ACP2_MCU,AHL_AFL,BSM,CGM,EBCM,EOCM,EOCM_HC_Superset,FCM,RDCM,TCCM,TCM
 SG_ E44BRP_HillDscntCtlSwStsAuth : 131|2@0+ (1,0) [0|3] "" ACP2_MCU,AHL_AFL,BSM,CGM,EBCM,EOCM,EOCM_HC_Superset,FCM,RDCM,TCCM,TCM
 SG_ ESP_EngSpdStAuth : 133|2@0+ (1,0) [0|2] "" ACP2_MCU,AHL_AFL,BSM,VICM,CGM,DCM,EBCM,EOCM,EOCM_HC_Superset,FCM,RDCM,TCCM,TCM
 SG_ EngNonTransRegSSTrqER : 141|12@0+ (1,-848) [-848|3247] "Nm" ACP2_MCU,AHL_AFL,CGM,EBCM,EOCM,EOCM_HC_Superset,FCM,RDCM,TCCM,TCM
 SG_ E49RmtEngStrtReqAuth : 142|1@0+ (1,0) [0|1] "" ACP2_MCU,AHL_AFL,CGM,EBCM,EOCM,EOCM_HC_Superset,FCM,RDCM,TCCM,TCM
 SG_ E49RmtEngShtdnReqdAuth : 143|1@0+ (1,0) [0|1] "" ACP2_MCU,AHL_AFL,CGM,EBCM,EOCM,EOCM_HC_Superset,FCM,RDCM,TCCM,TCM
 SG_ SD18P_Filler : 144|9@0+ (1,0) [0|511] "" ACP2_MCU,AHL_AFL,CGM,EBCM,EOCM,EOCM_HC_Superset,FCM,RDCM,TCCM,TCM
 SG_ EngNonTransRegSSTrqER_Inv : 145|1@0+ (1,0) [0|1] "" ACP2_MCU,AHL_AFL,CGM,EBCM,EOCM,EOCM_HC_Superset,FCM,RDCM,TCCM,TCM

BO_ 978 SrlDat195_PCSM_PDU: 8 Vector__XXX
 SG_ SrlDat195_PCSM : 7|64@0+ (1,0) [0|1.84467e+019] "" ACP2_MCU

BO_ 157 SrlDat195_Prtctd_PDU: 12 Vector__XXX
 SG_ SD195P_MAC : 7|32@0+ (1,0) [0|4.29497e+009] "" ACP2_MCU
 SG_ SD195P_FCnt : 39|5@0+ (1,0) [0|31] "" ACP2_MCU
 SG_ DMSDrvrDrwLvlPrd : 47|14@0+ (0.05,0) [0|819.15] "sec" ACP2_MCU,FCM
 SG_ DMSDrvrPctgOfEyeClsrPrd : 49|14@0+ (0.05,0) [0|819.15] "sec" ACP2_MCU,FCM
 SG_ DMSDrvrPctgOfEyeClsr : 67|7@0+ (1,0) [0|127] "%" ACP2_MCU,FCM
 SG_ DMSDrvrDrwLvlCnfdLvl : 72|3@0+ (1,0) [0|7] "" ACP2_MCU,FCM
 SG_ DMSDrvrDrwLvl : 76|4@0+ (1,0) [0|9] "" ACP2_MCU,FCM
 SG_ SD195P_Filler : 85|12@0+ (1,0) [0|4095] "" ACP2_MCU
 SG_ SD195P_ARC : 89|2@0+ (1,0) [0|3] "" ACP2_MCU

BO_ 1139 Message1109_PDU: 8 Vector__XXX
 SG_ Sig6852 : 7|64@0+ (1,0) [0|1.84467e+019] "" DMS

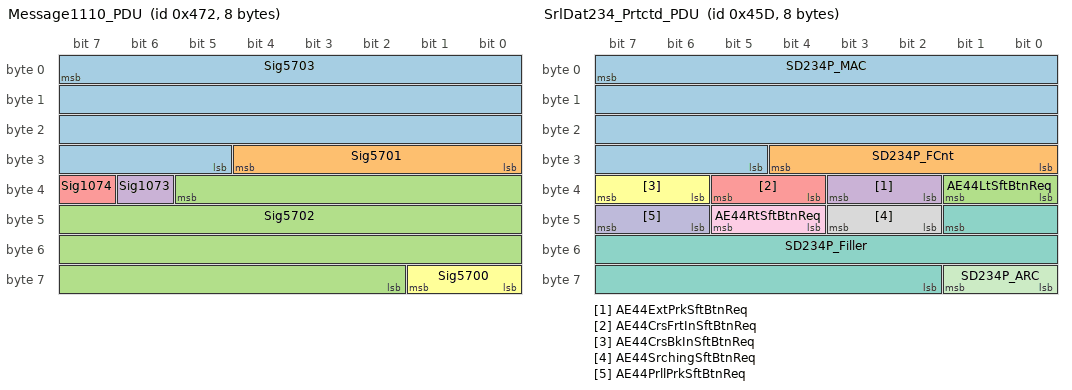
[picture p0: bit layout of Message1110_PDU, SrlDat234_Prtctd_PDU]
BO_ 1138 Message1110_PDU: 8 Vector__XXX
 SG_ Sig5703 : 7|27@0+ (1,0) [0|1.34218e+008] "" DMS
 SG_ Sig5701 : 28|5@0+ (1,0) [0|31] "" DMS
 SG_ Sig5702 : 37|28@0+ (1,0) [0|2.68435e+008] "" DMS
 SG_ Sig1073 : 38|1@0+ (1,0) [0|1] "" DMS
 SG_ Sig1074 : 39|1@0+ (1,0) [0|1] "" DMS
 SG_ Sig5700 : 57|2@0+ (1,0) [0|3] "" DMS

BO_ 907 SrlDat19_PCSM_PDU: 8 Vector__XXX
 SG_ SrlDat19_PCSM : 7|64@0+ (1,0) [0|1.84467e+019] "" ACP2_MCU,ADIMa,ADIMb,BSM,EBCM,EOCM,EOCM_HC_Superset,FCM,PCM,RDCM,TCCM,TCM,ECP_X1

BO_ 47 SrlDat19_Prtctd_PDU: 32 Vector__XXX
 SG_ SD19P_MAC : 7|32@0+ (1,0) [0|4.29497e+009] "" ACP2_MCU,ADIMa,ADIMb,BSM,CGM,EBCM,EOCM,EOCM_HC_Superset,FCM,PCM,RDCM,TCCM,TCM,ECP_X1
 SG_ SD19P_FCnt : 39|5@0+ (1,0) [0|31] "" ACP2_MCU,ADIMa,ADIMb,BSM,CGM,EBCM,EOCM,EOCM_HC_Superset,FCM,PCM,RDCM,TCCM,TCM,ECP_X1
 SG_ AATP_ActAxlTrqAuth : 47|15@0+ (2,-22534) [-22534|43000] "Nm" ACP2_MCU,ADIMa,ADIMb,BSM,VICM,CGM,DCM,EBCM,EOCM,EOCM_HC_Superset,EPS,EPSb,FCM,PCM,RDCM,TCCM,TCM,ECP_X1
 SG_ AATP_ActAxlTrqAuth_Inv : 48|1@0+ (1,0) [0|1] "" ACP2_MCU,ADIMa,ADIMb,BSM,VICM,CGM,DCM,EBCM,EOCM,EOCM_HC_Superset,EPS,EPSb,FCM,PCM,RDCM,TCCM,TCM,ECP_X1
 SG_ AEPP_AccEffcPosAuth : 63|8@0+ (0.392157,0) [0|100] "%" ACP2_MCU,ADIMa,ADIMb,BSM,CGM,EBCM,EOCM,EOCM_HC_Superset,FCM,PCM,RDCM,TCCM,TCM,ECP_X1
 SG_ DRCDNDP_DRCAvgDrvnAuth : 70|13@0+ (0.125,0) [0|1023.88] "m" ACP2_MCU,ADIMa,ADIMb,BSM,VECM,VICM,BSM_MH,CGM,EBCM,ECP_MC,EOCM,EOCM_HC_Superset,FCM,PCM,RDCM,TCCM,TCM,ECP_S,ECP_S2,ECP_X1
 SG_ AEPP_AccEffcPosAuth_Inv : 71|1@0+ (1,0) [0|1] "" ACP2_MCU,ADIMa,ADIMb,BSM,CGM,EBCM,EOCM,EOCM_HC_Superset,FCM,PCM,RDCM,TCCM,TCM,ECP_X1
 SG_ DRCDNDP_DRCAvgDrvnRstOccAuth : 72|1@0+ (1,0) [0|1] "" ACP2_MCU,ADIMa,ADIMb,BSM,VECM,VICM,BSM_MH,CGM,EBCM,ECP_MC,EOCM,EOCM_HC_Superset,FCM,PCM,RDCM,TCCM,TCM,ECP_S,ECP_S2,ECP_X1
 SG_ DRCDNDP_DRCAvgDrvnAuth_Inv : 73|1@0+ (1,0) [0|1] "" ACP2_MCU,ADIMa,ADIMb,BSM,VECM,VICM,BSM_MH,CGM,EBCM,ECP_MC,EOCM,EOCM_HC_Superset,FCM,PCM,RDCM,TCCM,TCM,ECP_S,ECP_S2,ECP_X1
 SG_ DRCDNDP_DRCAvgNonDrvnAuth : 86|13@0+ (0.125,0) [0|1023.88] "m" ACP2_MCU,ADIMa,ADIMb,BSM,CGM,EBCM,EOCM,EOCM_HC_Superset,FCM,PCM,RDCM,TCCM,TCM,ECP_X1
 SG_ DRCDNDP_DRCAvgDrvnSrcAuth : 87|1@0+ (1,0) [0|1] "" ACP2_MCU,ADIMa,ADIMb,BSM,VECM,VICM,BSM_MH,CGM,EBCM,ECP_MC,EOCM,EOCM_HC_Superset,FCM,PCM,RDCM,TCCM,TCM,ECP_S,ECP_S2,ECP_X1
 SG_ DRCDNDP_DRCAvgNonDrvnRstOccAuth : 88|1@0+ (1,0) [0|1] "" ACP2_MCU,ADIMa,ADIMb,BSM,CGM,EBCM,EOCM,EOCM_HC_Superset,FCM,PCM,RDCM,TCCM,TCM,ECP_X1
 SG_ DRCDNDP_DRCAvgNonDrvnAuth_Inv : 89|1@0+ (1,0) [0|1] "" ACP2_MCU,ADIMa,ADIMb,BSM,CGM,EBCM,EOCM,EOCM_HC_Superset,FCM,PCM,RDCM,TCCM,TCM,ECP_X1
 SG_ E44BRP_PTAutoBrkgAccelReqAuth : 102|12@0- (0.01,0) [-20.48|20.47] "" ACP2_MCU,ADIMa,ADIMb,BSM,CGM,EBCM,EOCM,EOCM_HC_Superset,FCM,PCM,RDCM,TCCM,TCM,ECP_X1
 SG_ DRCDNDP_PwrtrnRunAbrtdAuth : 103|1@0+ (1,0) [0|1] "" ACP2_MCU,ADIMa,ADIMb,BSM,CGM,EBCM,EOCM,EOCM_HC_Superset,FCM,PCM,RDCM,TCCM,TCM,ECP_X1
 SG_ PBP_PTSndBrkPdlPsAuth : 105|8@0+ (0.392157,0) [0|100] "%" ACP2_MCU,ADIMa,ADIMb,BSM,CGM,EBCM,EOCM,EOCM_HC_Superset,FCM,PCM,RDCM,TCCM,TCM,ECP_X1
 SG_ E44BRP_PTAutoBrkgReqActvAuth : 106|1@0+ (1,0) [0|1] "" ACP2_MCU,ADIMa,ADIMb,BSM,CGM,EBCM,EOCM,EOCM_HC_Superset,FCM,PCM,RDCM,TCCM,TCM,ECP_X1
 SG_ PSATDP_ATDstTrqCmdSecAuth : 112|15@0+ (2,-22534) [-22534|43000] "Nm" ACP2_MCU,ADIMa,ADIMb,BSM,CGM,EBCM,EOCM,EOCM_HC_Superset,FCM,PCM,RDCM,TCCM,TCM,ECP_X1
 SG_ PBP_PTSndBrkPdlPsAuth_Inv : 113|1@0+ (1,0) [0|1] "" ACP2_MCU,ADIMa,ADIMb,BSM,CGM,EBCM,EOCM,EOCM_HC_Superset,FCM,PCM,RDCM,TCCM,TCM,ECP_X1
 SG_ PSATIP_ATDstTqCmdPriImmAuth : 128|15@0+ (2,-22534) [-22534|43000] "Nm" ACP2_MCU,ADIMa,ADIMb,BSM,CGM,EBCM,EOCM,EOCM_HC_Superset,FCM,PCM,RDCM,TCCM,TCM,ECP_X1
 SG_ PSATDP_ATDstTrqCmdSecAuth_Inv : 129|1@0+ (1,0) [0|1] "" ACP2_MCU,ADIMa,ADIMb,BSM,CGM,EBCM,EOCM,EOCM_HC_Superset,FCM,PCM,RDCM,TCCM,TCM,ECP_X1
 SG_ PSATIP_CmndATImmedAuth : 144|15@0+ (2,-22534) [-22534|43000] "Nm" ACP2_MCU,ADIMa,ADIMb,BSM,CGM,EBCM,EOCM,EOCM_HC_Superset,FCM,PCM,RDCM,TCCM,TCM,ECP_X1
 SG_ PSATIP_ATDstTqCmdPriImmAuth_Inv : 145|1@0+ (1,0) [0|1] "" ACP2_MCU,ADIMa,ADIMb,BSM,CGM,EBCM,EOCM,EOCM_HC_Superset,FCM,PCM,RDCM,TCCM,TCM,ECP_X1
 SG_ PSATIP_CmndATPrdtdAuth : 161|15@0+ (2,-22534) [-22534|43000] "Nm" ACP2_MCU,ADIMa,ADIMb,BSM,CGM,EBCM,EOCM,EOCM_HC_Superset,FCM,PCM,RDCM,TCCM,TCM,ECP_X1
 SG_ PSATIP_PriATActlAuth : 176|15@0+ (2,-22534) [-22534|43000] "Nm" ACP2_MCU,ADIMa,ADIMb,BSM,CGM,EBCM,EOCM,EOCM_HC_Superset,EPS,EPSb,FCM,PCM,RDCM,TCCM,TCM,ECP_X1
 SG_ PSATIP_CmndATRespTypAuth : 178|2@0+ (1,0) [0|3] "" ACP2_MCU,ADIMa,ADIMb,BSM,CGM,EBCM,EOCM,EOCM_HC_Superset,FCM,PCM,RDCM,TCCM,TCM,ECP_X1
 SG_ PSATIP_PriATCmdImmedAuth : 192|15@0+ (2,-22534) [-22534|43000] "Nm" ACP2_MCU,ADIMa,ADIMb,BSM,CGM,EBCM,EOCM,EOCM_HC_Superset,FCM,PCM,RDCM,TCCM,TCM,ECP_X1
 SG_ PSATIP_PriATActlAuth_Inv : 193|1@0+ (1,0) [0|1] "" ACP2_MCU,ADIMa,ADIMb,BSM,CGM,EBCM,EOCM,EOCM_HC_Superset,EPS,EPSb,FCM,PCM,RDCM,TCCM,TCM,ECP_X1
 SG_ PSATIP_PriATReqStsAdvdTracAuth : 209|3@0+ (1,0) [0|6] "" ACP2_MCU,ADIMa,ADIMb,BSM,CGM,EBCM,EOCM,EOCM_HC_Superset,FCM,PCM,RDCM,TCCM,TCM,ECP_X1
 SG_ SD19P_FillerExtnd : 222|12@0+ (1,0) [0|4095] "" ACP2_MCU,ADIMa,ADIMb,BSM,CGM,EBCM,EOCM,EOCM_HC_Superset,FCM,PCM,RDCM,TCCM,TCM,ECP_X1
 SG_ PSATDP_SecATReqStsAdvdTracAuth : 226|3@0+ (1,0) [0|6] "" ACP2_MCU,ADIMa,ADIMb,BSM,CGM,EBCM,EOCM,EOCM_HC_Superset,FCM,RDCM,TCCM,TCM,ECP_X1
 SG_ PSATIP_SecATCmdImmedAuth : 237|19@0- (0.25,0) [-65536|65535.8] "Nm" ACP2_MCU,ADIMa,ADIMb,BSM,CGM,EBCM,EOCM,EOCM_HC_Superset,FCM,PCM,RDCM,TCCM,TCM,ECP_X1
 SG_ SD19P_ARC : 239|2@0+ (1,0) [0|3] "" ACP2_MCU,ADIMa,ADIMb,BSM,CGM,EBCM,EOCM,EOCM_HC_Superset,FCM,PCM,RDCM,TCCM,TCM,ECP_X1
 SG_ SD19P_Filler : 250|3@0+ (1,0) [0|7] "" ACP2_MCU,ADIMa,ADIMb,BSM,CGM,EBCM,EOCM,EOCM_HC_Superset,FCM,PCM,RDCM,TCCM,TCM,ECP_X1

BO_ 906 SrlDat20_PCSM_PDU: 8 Vector__XXX
 SG_ SrlDat20_PCSM : 7|64@0+ (1,0) [0|1.84467e+019] "" ACP2_MCU,ADIMa,ADIMb,EBCM,EOCM,EOCM_HC_Superset,FCM,PCM,RDCM,TCCM,TCM

BO_ 226 SrlDat20_Prtctd_PDU: 20 Vector__XXX
 SG_ SD20P_MAC : 7|32@0+ (1,0) [0|4.29497e+009] "" ACP2_MCU,ADIMa,ADIMb,CGM,EBCM,EOCM,EOCM_HC_Superset,FCM,PCM,RDCM,TCCM,TCM
 SG_ SD20P_FCnt : 39|5@0+ (1,0) [0|31] "" ACP2_MCU,ADIMa,ADIMb,CGM,EBCM,EOCM,EOCM_HC_Superset,FCM,PCM,RDCM,TCCM,TCM
 SG_ DIATMNP_DrvrIntdAxlTqMnAuth : 47|15@0+ (2,-22534) [-22534|43000] "Nm" ACP2_MCU,ADIMa,ADIMb,CGM,EBCM,EOCM,EOCM_HC_Superset,FCM,PCM,RDCM,TCCM,TCM
 SG_ DIATMNP_DrvrIntdAxlTqMnAuth_Inv : 48|1@0+ (1,0) [0|1] "" ACP2_MCU,ADIMa,ADIMb,CGM,EBCM,EOCM,EOCM_HC_Superset,FCM,PCM,RDCM,TCCM,TCM
 SG_ DIATMXP_DrvrIntdAxlTqMxAuth : 63|15@0+ (2,-22534) [-22534|43000] "Nm" ACP2_MCU,ADIMa,ADIMb,CGM,EBCM,EOCM,EOCM_HC_Superset,FCM,PCM,RDCM,TCCM,TCM
 SG_ DIATMXP_DrvrIntdAxlTqMxAuth_Inv : 64|1@0+ (1,0) [0|1] "" ACP2_MCU,ADIMa,ADIMb,CGM,EBCM,EOCM,EOCM_HC_Superset,FCM,PCM,RDCM,TCCM,TCM
 SG_ DITP_DrvrIntndAxlTrqAuth : 79|15@0+ (2,-22534) [-22534|43000] "Nm" ACP2_MCU,ADIMa,ADIMb,BSM,VICM,CGM,DCM,EBCM,EOCM,EOCM_HC_Superset,FCM,PCM,RDCM,TCCM,TCM
 SG_ DITP_DrvrIntndAxlTrqAuth_Inv : 80|1@0+ (1,0) [0|1] "" ACP2_MCU,ADIMa,ADIMb,BSM,VICM,CGM,DCM,EBCM,EOCM,EOCM_HC_Superset,FCM,PCM,RDCM,TCCM,TCM
 SG_ DITP_DrvrIntndCrksftTrqAuth : 95|12@0+ (0.5,-848) [-848|1199.5] "Nm" ACP2_MCU,ADIMa,ADIMb,CGM,EBCM,EOCM,EOCM_HC_Superset,FCM,PCM,RDCM,TCCM,TCM
 SG_ VMI1P_AccelActlPstnAuth : 99|8@0+ (0.392157,0) [0|100] "%" ACP2_MCU,ADIMa,ADIMb,AHL_AFL,BSM,VICM,CGM,EBCM,EOCM,EOCM_HC_Superset,FCM,PCM,RDCM,TCCM,TCM,VDM,ECP_X1
 SG_ VMI1P_VehTopSpdLimArbdValAuth : 105|8@0+ (2,0) [0|510] "km / h" ACP2_MCU,ADIMa,ADIMb,CGM,EBCM,EOCM,EOCM_HC_Superset,FCM,PCM,RDCM,TCCM,TCM
 SG_ VMI1P_AccelPedOvrrdActvAuth : 106|1@0+ (1,0) [0|1] "" ACP2_MCU,ADIMa,ADIMb,CGM,EBCM,EOCM,EOCM_HC_Superset,FCM,PCM,RDCM,TCCM,TCM
 SG_ VMI1P_AccelActlPstnAuth_Inv : 107|1@0+ (1,0) [0|1] "" ACP2_MCU,ADIMa,ADIMb,AHL_AFL,BSM,VICM,CGM,EBCM,EOCM,EOCM_HC_Superset,FCM,PCM,RDCM,TCCM,TCM,VDM,ECP_X1
 SG_ SD20P_ARC : 112|2@0+ (1,0) [0|3] "" ACP2_MCU,ADIMa,ADIMb,CGM,EBCM,EOCM,EOCM_HC_Superset,FCM,PCM,RDCM,TCCM,TCM
 SG_ VMI1P_VehTopSpdLimModeActvAuth : 113|1@0+ (1,0) [0|1] "" ACP2_MCU,ADIMa,ADIMb,CGM,EBCM,EOCM,EOCM_HC_Superset,FCM,PCM,RDCM,TCCM,TCM
 SG_ SD20P_Filler : 126|32@0+ (1,0) [0|4.29497e+009] "" ACP2_MCU,ADIMa,ADIMb,CGM,EBCM,EOCM,EOCM_HC_Superset,FCM,PCM,RDCM,TCCM,TCM
 SG_ SD20P_FillerExtnd : 158|7@0+ (1,0) [0|127] "" ACP2_MCU,ADIMa,ADIMb,CGM,EBCM,EOCM,EOCM_HC_Superset,FCM,PCM,RDCM,TCCM,TCM

BO_ 905 SrlDat21_PCSM_PDU: 8 Vector__XXX
 SG_ SrlDat21_PCSM : 7|64@0+ (1,0) [0|1.84467e+019] "" ACP2_MCU,BSM,VICM,EOCM,EOCM_HC_Superset,FCM

BO_ 615 SrlDat21_Prtctd_PDU: 20 Vector__XXX
 SG_ SD21P_MAC : 7|32@0+ (1,0) [0|4.29497e+009] "" ACP2_MCU,BSM,VICM,CGM,EOCM,EOCM_HC_Superset,FCM
 SG_ SD21P_FCnt : 39|5@0+ (1,0) [0|31] "" ACP2_MCU,BSM,VICM,CGM,EOCM,EOCM_HC_Superset,FCM
 SG_ BVSCRP_BdyCtlTpSpdLimRspTypAuth : 42|3@0+ (1,0) [0|6] "" ACP2_MCU,BSM,VICM,CGM,EOCM,EOCM_HC_Superset,FCM
 SG_ BVSCRP_ACCAxlTrqCmdReqStsAuth : 45|3@0+ (1,0) [0|4] "" ACP2_MCU,BSM,VICM,CGM,EOCM,EOCM_HC_Superset,FCM,RDCM
 SG_ BVSCRP_ACCAxlTrqCmdLimStsAuth : 47|2@0+ (1,0) [0|3] "" ACP2_MCU,BSM,VICM,CGM,EOCM,EOCM_HC_Superset,FCM,RDCM
 SG_ BVSCRP_BdyCtlTpSpdLimRspValAuth : 55|8@0+ (2,0) [0|510] "kph" ACP2_MCU,BSM,VICM,CGM,EOCM,EOCM_HC_Superset,FCM
 SG_ BVSCRP_CltchPdlActPosAuth : 58|8@0+ (0.392157,0) [0|100] "" ACP2_MCU,BSM,VICM,CGM,EBCM,EOCM,EOCM_HC_Superset,FCM
 SG_ BVSCRP_CPSAxlTrqCmdReqStsAuth : 61|3@0+ (1,0) [0|6] "" ACP2_MCU,BSM,VICM,CGM,EOCM,EOCM_HC_Superset,FCM,RDCM
 SG_ BVSCRP_CPSAxlTrqCmdLimStsAuth : 63|2@0+ (1,0) [0|3] "" ACP2_MCU,BSM,VICM,CGM,EOCM,EOCM_HC_Superset,FCM,RDCM
 SG_ CnvntlCruzCtlIndReqAuth : 64|3@0+ (1,0) [0|5] "" ACP2_MCU,BSM,VICM,CGM,EOCM,EOCM_HC_Superset,FCM
 SG_ BVSCRP_CruzCtlEnbldAuth : 65|1@0+ (1,0) [0|1] "" ACP2_MCU,BSM,VICM,CGM,EBCM,EOCM,EOCM_HC_Superset,FCM
 SG_ BVSCRP_CltchPdlActPosAuth_Inv : 66|1@0+ (1,0) [0|1] "" ACP2_MCU,BSM,VICM,CGM,EBCM,EOCM,EOCM_HC_Superset,FCM
 SG_ CruzSpdLmtrDrvrSeltdSpdAuth : 76|12@0+ (0.0625,0) [0|255.938] "km / h" ACP2_MCU,BSM,VICM,CGM,EOCM,EOCM_HC_Superset,FCM,PCM,TCM
 SG_ CruzCtlActvAuth : 77|1@0+ (1,0) [0|1] "" ACP2_MCU,BSM,VICM,CGM,EBCM,EOCM,EOCM_HC_Superset,FCM,PCM,TCM
 SG_ DrSeltdSpdLmtrAutoMdSpLmStsAuth : 80|2@0+ (1,0) [0|3] "" ACP2_MCU,BSM,VICM,CGM,EOCM,EOCM_HC_Superset,FCM
 SG_ EGI2P_DrvrReqdAxlTrqValAuth : 89|15@0+ (2,-22534) [-22534|43000] "Nm" ACP2_MCU,BSM,VICM,CGM,EOCM,EOCM_HC_Superset,FCM
 SG_ EGI2P_DrvrReqdAxlTrqIncrAuth : 90|1@0+ (1,0) [0|1] "" ACP2_MCU,BSM,VICM,CGM,EOCM,EOCM_HC_Superset,FCM
 SG_ DrSeltdSpdLmtrSetTypActvAuth : 92|2@0+ (1,0) [0|3] "" ACP2_MCU,BSM,VICM,CGM,EOCM,EOCM_HC_Superset,FCM
 SG_ DrSeltdSpdLmtrSetSpdLimRchdAuth : 94|2@0+ (1,0) [0|3] "" ACP2_MCU,BSM,VICM,CGM,EOCM,EOCM_HC_Superset,FCM
 SG_ E44BRP_VehTopSpdLimArbdStatAuth : 104|2@0+ (1,0) [0|2] "" ACP2_MCU,BSM,VICM,CGM,EBCM,EOCM,EOCM_HC_Superset,FCM
 SG_ EGI2P_PwrtrnCrnkActvAuth : 105|1@0+ (1,0) [0|1] "" ACP2_MCU,BSM,VICM,CGM,EOCM,EOCM_HC_Superset,FCM,PCM,TCM,ECP_X1
 SG_ EGI2P_DrvrReqdAxlTrqValAuth_Inv : 106|1@0+ (1,0) [0|1] "" ACP2_MCU,BSM,VICM,CGM,EOCM,EOCM_HC_Superset,FCM
 SG_ SpdLmtrSpdLimSgnValAuth : 117|8@0+ (1,0) [0|255] "" ACP2_MCU,BSM,VICM,CGM,EOCM,EOCM_HC_Superset,FCM
 SG_ SpdLmtrSpdLimSgnUntAuth : 118|1@0+ (1,0) [0|1] "" ACP2_MCU,BSM,VICM,CGM,EOCM,EOCM_HC_Superset,FCM
 SG_ SD21P_Filler : 121|32@0+ (1,0) [0|4.29497e+009] "" ACP2_MCU,BSM,VICM,CGM,EOCM,EOCM_HC_Superset,FCM
 SG_ SuprRmtPrkPrplSysResp : 123|2@0+ (1,0) [0|3] "" ACP2_MCU,BSM,VICM,CGM,EOCM,EOCM_HC_Superset,FCM
 SG_ SD21P_ARC : 125|2@0+ (1,0) [0|3] "" ACP2_MCU,BSM,VICM,CGM,EOCM,EOCM_HC_Superset,FCM
 SG_ SD21P_FillerExtnd : 153|2@0+ (1,0) [0|3] "" ACP2_MCU,BSM,VICM,CGM,EOCM,EOCM_HC_Superset,FCM

BO_ 1404 SrlDat22_PCSM_PDU: 8 Vector__XXX
 SG_ SrlDat22_PCSM : 7|64@0+ (1,0) [0|1.84467e+019] "" ACP2_MCU,AHL_AFL,AHS,ARS,BSM,VICM,BSM_MH,CGM,DCM,ECP_MC,EOCM,EOCM_HC_Superset,EPSRAa,EPS,EPSb,FCM,FOPM,PCM,RDCM,TCCM,TCM,ECP_X1

BO_ 879 SrlDat22_Prtctd_PDU: 8 Vector__XXX
 SG_ SD22P_MAC : 7|27@0+ (1,0) [0|1.34218e+008] "" ACP2_MCU,AHL_AFL,AHS,ARS,BSM,VICM,BSM_MH,CGM,DCM,ECP_MC,EOCM,EOCM_HC_Superset,EPSRAa,EPS,EPSb,FCM,FOPM,PCM,RDCM,TCCM,TCM,ECP_X1
 SG_ SD22P_FCnt : 28|5@0+ (1,0) [0|31] "" ACP2_MCU,AHL_AFL,AHS,ARS,BSM,VICM,BSM_MH,CGM,DCM,ECP_MC,EOCM,EOCM_HC_Superset,EPSRAa,EPS,EPSb,FCM,FOPM,PCM,RDCM,TCCM,TCM,ECP_X1
 SG_ EGI3P_CnvtTpSpLimRspValAuth : 36|8@0+ (2,0) [0|510] "kph" ACP2_MCU,AHL_AFL,AHS,ARS,BSM,VICM,BSM_MH,CGM,DCM,ECP_MC,EOCM,EOCM_HC_Superset,EPSRAa,EPS,EPSb,FCM,FOPM,PCM,RDCM,TCCM,TCM,ECP_X1
 SG_ EGI3P_CnvtTpSpLimRspTypAuth : 39|3@0+ (1,0) [0|6] "" ACP2_MCU,AHL_AFL,AHS,ARS,BSM,VICM,BSM_MH,CGM,DCM,ECP_MC,EOCM,EOCM_HC_Superset,EPSRAa,EPS,EPSb,FCM,FOPM,PCM,RDCM,TCCM,TCM,ECP_X1
 SG_ PSP_PrkNeutSwStatAuth_Inv : 40|1@0+ (1,0) [0|1] "" ACP2_MCU,AHL_AFL,AHS,ARS,BSM,VICM,BSM_MH,CGM,DCM,ECP_MC,EOCM,EOCM_HC_Superset,EPSRAa,EPS,EPSb,FCM,FOPM,PCM,RDCM,TCCM,TCM,ECP_X1
 SG_ PSP_PrkNeutSwStatAuth : 41|1@0+ (1,0) [0|1] "" ACP2_MCU,AHL_AFL,AHS,ARS,BSM,VICM,BSM_MH,CGM,DCM,ECP_MC,EOCM,EOCM_HC_Superset,EPSRAa,EPS,EPSb,FCM,FOPM,PCM,RDCM,TCCM,TCM,ECP_X1
 SG_ PSP_EngRnngAuth : 42|1@0+ (1,0) [0|1] "" ACP2_MCU,AHL_AFL,AHS,ARS,BSM,VICM,BSM_MH,CGM,DCM,DMS,ECP_MC,EOCM,EOCM_HC_Superset,EPSRAa,EPS,EPSb,FCM,FOPM,HUD_CAN,LIB1,NVM,E44,PCM,RDCM,TCCM,TCM,ECP_S,ECP_X1
 SG_ PSP_ClchBtmTrvlAchvdAuth_Inv : 43|1@0+ (1,0) [0|1] "" ACP2_MCU,AHL_AFL,AHS,ARS,BSM,VICM,BSM_MH,CGM,DCM,ECP_MC,EOCM,EOCM_HC_Superset,EPSRAa,EPS,EPSb,FCM,FOPM,PCM,RDCM,TCCM,TCM,ECP_X1
 SG_ PSP_ClchBtmTrvlAchvdAuth : 44|1@0+ (1,0) [0|1] "" ACP2_MCU,AHL_AFL,AHS,ARS,BSM,VICM,BSM_MH,CGM,DCM,ECP_MC,EOCM,EOCM_HC_Superset,EPSRAa,EPS,EPSb,FCM,FOPM,PCM,RDCM,TCCM,TCM,ECP_X1
 SG_ SD22P_ARC : 49|2@0+ (1,0) [0|3] "" ACP2_MCU,AHL_AFL,AHS,ARS,BSM,VICM,BSM_MH,CGM,DCM,ECP_MC,EOCM,EOCM_HC_Superset,EPSRAa,EPS,EPSb,FCM,FOPM,PCM,RDCM,TCCM,TCM,ECP_X1
 SG_ PSP_VehTheftImbChlgRespStsAuth : 51|2@0+ (1,0) [0|2] "" ACP2_MCU,AHL_AFL,AHS,ARS,BSM,VICM,BSM_MH,CGM,DCM,ECP_MC,EOCM,EOCM_HC_Superset,EPSRAa,EPS,EPSb,FCM,FOPM,PCM,RDCM,TCCM,TCM,ECP_X1
 SG_ PSP_RmtVehStrtEngRnngAuth : 52|1@0+ (1,0) [0|1] "" ACP2_MCU,AHL_AFL,AHS,ARS,BSM,VICM,BSM_MH,CGM,DCM,ECP_MC,EOCM,EOCM_HC_Superset,EPSRAa,EPS,EPSb,FCM,FOPM,PCM,RDCM,TCCM,TCM,ECP_X1
 SG_ PSP_PwrtrnCrnkAbrtdAuth : 53|1@0+ (1,0) [0|1] "" ACP2_MCU,AHL_AFL,AHS,ARS,BSM,VICM,BSM_MH,CGM,DCM,ECP_MC,EOCM,EOCM_HC_Superset,EPSRAa,EPS,EPSb,FCM,FOPM,PCM,RDCM,TCCM,TCM,ECP_X1
 SG_ PSP_PrplSysStlActvAuth : 54|1@0+ (1,0) [0|1] "" ACP2_MCU,AHL_AFL,AHS,ARS,BSM,VICM,BSM_MH,CGM,DCM,ECP_MC,EOCM,EOCM_HC_Superset,EPSRAa,EPS,EPSb,FCM,FOPM,PCM,RDCM,TCCM,TCM,ECP_X1
 SG_ PSP_PrplSysActvAuth : 55|1@0+ (1,0) [0|1] "" ACP2_MCU,ADIMa,ADIMb,AHL_AFL,AHS,ARS,BSM,VECM,VICM,BSM_MH,CGM,DCM,EBCM,ECP_MC,EOCM,EOCM_HC_Superset,EPSRAa,EPS,EPSb,FCM,FOPM,HUD_CAN,LIB1,NVM,E44,PCM,RDCM,TCCM,TCM,VDM,ECP_S,ECP_S2,ECP_X1
 SG_ SD22P_Filler : 62|7@0+ (1,0) [0|127] "" ACP2_MCU,AHL_AFL,AHS,ARS,BSM,VICM,BSM_MH,CGM,DCM,ECP_MC,EOCM,EOCM_HC_Superset,EPSRAa,EPS,EPSb,FCM,FOPM,PCM,RDCM,TCCM,TCM,ECP_X1
 SG_ PrplBrkThrotOvrrdReqd : 63|1@0+ (1,0) [0|1] "" ACP2_MCU,AHL_AFL,AHS,ARS,BSM,VICM,BSM_MH,CGM,DCM,ECP_MC,EOCM,EOCM_HC_Superset,EPSRAa,EPS,EPSb,FCM,FOPM,PCM,RDCM,TCCM,TCM,ECP_X1

BO_ 1949 SrlDat234_PCSM_PDU: 8 Vector__XXX
 SG_ SrlDat234_PCSM : 7|64@0+ (1,0) [0|1.84467e+019] "" Vector__XXX

BO_ 1117 SrlDat234_Prtctd_PDU: 8 Vector__XXX
 SG_ SD234P_MAC : 7|27@0+ (1,0) [0|1.34218e+008] "" Vector__XXX
 SG_ SD234P_FCnt : 28|5@0+ (1,0) [0|31] "" Vector__XXX
 SG_ AE44LtSftBtnReq : 33|2@0+ (1,0) [0|3] "" Vector__XXX
 SG_ AE44ExtPrkSftBtnReq : 35|2@0+ (1,0) [0|3] "" Vector__XXX
 SG_ AE44CrsFrtInSftBtnReq : 37|2@0+ (1,0) [0|3] "" Vector__XXX
 SG_ AE44CrsBkInSftBtnReq : 39|2@0+ (1,0) [0|3] "" Vector__XXX
 SG_ SD234P_Filler : 41|16@0+ (1,0) [0|65535] "" Vector__XXX
 SG_ AE44SrchingSftBtnReq : 43|2@0+ (1,0) [0|3] "" Vector__XXX
 SG_ AE44RtSftBtnReq : 45|2@0+ (1,0) [0|3] "" Vector__XXX
 SG_ AE44PrllPrkSftBtnReq : 47|2@0+ (1,0) [0|3] "" Vector__XXX
 SG_ SD234P_ARC : 57|2@0+ (1,0) [0|3] "" Vector__XXX

BO_ 1375 SrlDat23_PCSM_PDU: 8 Vector__XXX
 SG_ SrlDat23_PCSM : 7|64@0+ (1,0) [0|1.84467e+019] "" Vector__XXX

BO_ 1300 SrlDat23_Prtctd_PDU: 12 Vector__XXX
 SG_ SD23P_MAC : 7|32@0+ (1,0) [0|4.29497e+009] "" CGM
 SG_ SD23P_FCnt : 39|5@0+ (1,0) [0|31] "" CGM
 SG_ VOBP_VehOdoBkupAuth : 47|28@0+ (0.015625,0) [0|4.1943e+006] "km" BSM,CGM,EBCM
 SG_ SD23P_Filler : 64|25@0+ (1,0) [0|3.35544e+007] "" CGM
 SG_ SD23P_ARC : 66|2@0+ (1,0) [0|3] "" CGM
 SG_ VOBP_VehOdoBkupAuth_Inv : 67|1@0+ (1,0) [0|1] "" BSM,CGM,EBCM

BO_ 1374 SrlDat25_PCSM_PDU: 8 Vector__XXX
 SG_ SrlDat25_PCSM : 7|64@0+ (1,0) [0|1.84467e+019] "" ACP2_MCU,EOCM,EOCM_HC_Superset,E44,PCM,RDCM,TCCM,TCM,ECP_E,ECP_S2,ECP_X1

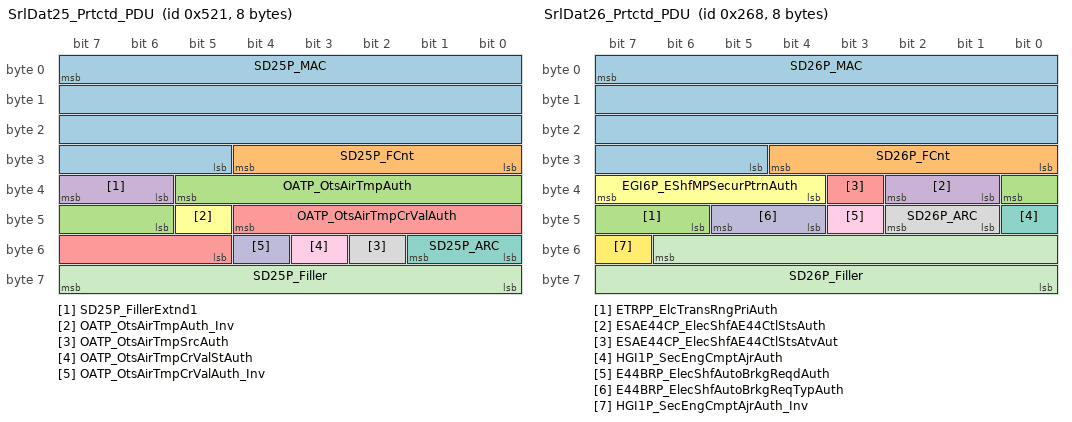
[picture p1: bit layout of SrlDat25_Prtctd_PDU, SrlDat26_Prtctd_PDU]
BO_ 1313 SrlDat25_Prtctd_PDU: 8 Vector__XXX
 SG_ SD25P_MAC : 7|27@0+ (1,0) [0|1.34218e+008] "" ACP2_MCU,CGM,EOCM,EOCM_HC_Superset,E44,PCM,RDCM,TCCM,TCM,ECP_E,ECP_S2,ECP_X1
 SG_ SD25P_FCnt : 28|5@0+ (1,0) [0|31] "" ACP2_MCU,CGM,EOCM,EOCM_HC_Superset,E44,PCM,RDCM,TCCM,TCM,ECP_E,ECP_S2,ECP_X1
 SG_ OATP_OtsAirTmpAuth : 37|8@0+ (0.5,-40) [-40|87.5] "Deg C" ACP2_MCU,BSM,CGM,DCM,EOCM,EOCM_HC_Superset,E44,PCM,RDCM,TCCM,TCM,VDM,ECP_E,ECP_S,ECP_S2,ECP_X1
 SG_ SD25P_FillerExtnd1 : 39|2@0+ (1,0) [0|3] "" ACP2_MCU,CGM,EOCM,EOCM_HC_Superset,E44,PCM,RDCM,TCCM,TCM,VDM,ECP_E,ECP_S2,ECP_X1
 SG_ OATP_OtsAirTmpCrValAuth : 44|8@0+ (0.5,-40) [-40|87.5] "Deg C" ACP2_MCU,ADIMa,ADIMb,BSM,CGM,EBCM,EOCM,EOCM_HC_Superset,EPSRAa,EPS,EPSb,FCM,NVM,E44,PCM,RDCM,TCCM,TCM,VDM,ECP_E,ECP_S2,ECP_X1
 SG_ OATP_OtsAirTmpAuth_Inv : 45|1@0+ (1,0) [0|1] "" ACP2_MCU,BSM,CGM,EOCM,EOCM_HC_Superset,E44,PCM,RDCM,TCCM,TCM,VDM,ECP_E,ECP_S,ECP_S2,ECP_X1
 SG_ SD25P_ARC : 49|2@0+ (1,0) [0|3] "" ACP2_MCU,BSM,CGM,EOCM,EOCM_HC_Superset,E44,PCM,RDCM,TCCM,TCM,ECP_E,ECP_S2,ECP_X1
 SG_ OATP_OtsAirTmpSrcAuth : 50|1@0+ (1,0) [0|1] "" ACP2_MCU,BSM,CGM,EOCM,EOCM_HC_Superset,E44,PCM,RDCM,TCCM,TCM,VDM,ECP_E,ECP_S2,ECP_X1
 SG_ OATP_OtsAirTmpCrValStAuth : 51|1@0+ (1,0) [0|1] "" ACP2_MCU,BSM,CGM,EOCM,EOCM_HC_Superset,EPSRAa,EPS,EPSb,E44,PCM,RDCM,TCCM,TCM,VDM,ECP_E,ECP_S2,ECP_X1
 SG_ OATP_OtsAirTmpCrValAuth_Inv : 52|1@0+ (1,0) [0|1] "" ACP2_MCU,ADIMa,ADIMb,BSM,CGM,EBCM,EOCM,EOCM_HC_Superset,EPSRAa,EPS,EPSb,FCM,NVM,E44,PCM,RDCM,TCCM,TCM,VDM,ECP_E,ECP_S2,ECP_X1
 SG_ SD25P_Filler : 63|8@0+ (1,0) [0|255] "" ACP2_MCU,CGM,EOCM,EOCM_HC_Superset,E44,PCM,RDCM,TCCM,TCM,ECP_E,ECP_S2,ECP_X1

BO_ 693 SrlDat26_PCSM_PDU: 8 Vector__XXX
 SG_ SrlDat26_PCSM : 7|64@0+ (1,0) [0|1.84467e+019] "" ACP2_MCU,EBCM,EOCM,EOCM_HC_Superset,E44,PCM,TCM,ECP_E,ECP_X1

BO_ 616 SrlDat26_Prtctd_PDU: 8 Vector__XXX
 SG_ SD26P_MAC : 7|27@0+ (1,0) [0|1.34218e+008] "" ACP2_MCU,EBCM,EOCM,EOCM_HC_Superset,E44,PCM,TCM,ECP_E,ECP_X1
 SG_ SD26P_FCnt : 28|5@0+ (1,0) [0|31] "" ACP2_MCU,EBCM,EOCM,EOCM_HC_Superset,E44,PCM,TCM,ECP_E,ECP_X1
 SG_ ETRPP_ElcTransRngPriAuth : 32|3@0+ (1,0) [0|6] "" ACP2_MCU,EBCM,EOCM,EOCM_HC_Superset,E44,PCM,TCM,ECP_E,ECP_X1
 SG_ ESAE44CP_ElecShfAE44CtlStsAuth : 34|2@0+ (1,0) [0|3] "" ACP2_MCU,EBCM,EOCM,EOCM_HC_Superset,E44,PCM,TCM,ECP_E,ECP_X1
 SG_ ESAE44CP_ElecShfAE44CtlStsAtvAut : 35|1@0+ (1,0) [0|1] "" ACP2_MCU,EBCM,EOCM,EOCM_HC_Superset,E44,PCM,TCM,ECP_E,ECP_X1
 SG_ EGI6P_EShfMPSecurPtrnAuth : 39|4@0+ (1,0) [0|15] "Counts" ACP2_MCU,EBCM,EOCM,EOCM_HC_Superset,E44,PCM,TCM,ECP_E,ECP_X1
 SG_ HGI1P_SecEngCmptAjrAuth : 40|1@0+ (1,0) [0|1] "" ACP2_MCU,EBCM,EOCM,EOCM_HC_Superset,E44,PCM,TCM,VDM,ECP_E,ECP_X1
 SG_ SD26P_ARC : 42|2@0+ (1,0) [0|3] "" ACP2_MCU,EBCM,EOCM,EOCM_HC_Superset,E44,PCM,TCM,ECP_E,ECP_X1
 SG_ E44BRP_ElecShfAutoBrkgReqdAuth : 43|1@0+ (1,0) [0|1] "" ACP2_MCU,EBCM,EOCM,EOCM_HC_Superset,E44,PCM,TCM,ECP_E,ECP_X1
 SG_ E44BRP_ElecShfAutoBrkgReqTypAuth : 45|2@0+ (1,0) [0|3] "" ACP2_MCU,EBCM,EOCM,EOCM_HC_Superset,E44,PCM,TCM,ECP_E,ECP_X1
 SG_ SD26P_Filler : 54|15@0+ (1,0) [0|32767] "" ACP2_MCU,EBCM,EOCM,EOCM_HC_Superset,E44,PCM,TCM,ECP_E,ECP_X1
 SG_ HGI1P_SecEngCmptAjrAuth_Inv : 55|1@0+ (1,0) [0|1] "" ACP2_MCU,EBCM,EOCM,EOCM_HC_Superset,E44,PCM,TCM,VDM,ECP_E,ECP_X1

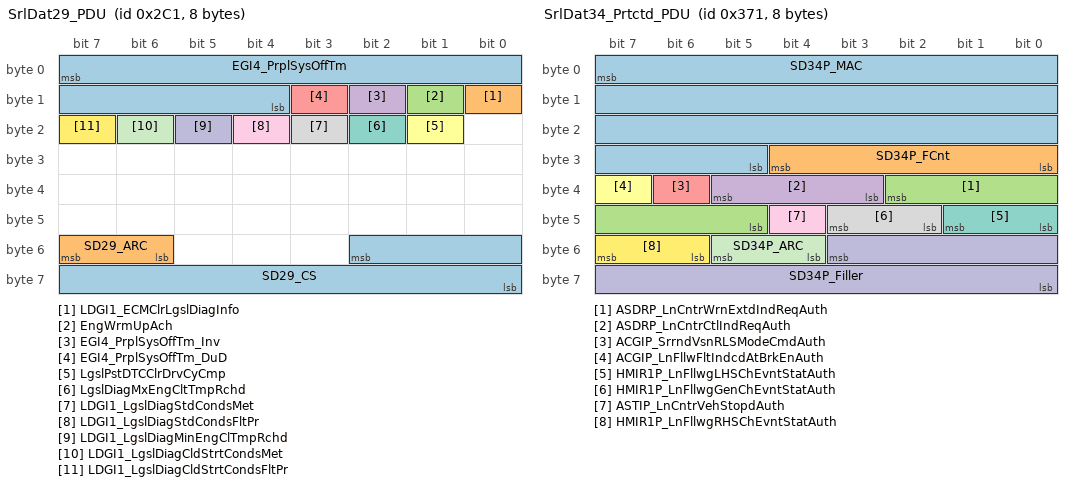
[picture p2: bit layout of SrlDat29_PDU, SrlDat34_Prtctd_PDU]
BO_ 705 SrlDat29_PDU: 8 Vector__XXX
 SG_ EGI4_PrplSysOffTm : 7|12@0+ (0.5,0) [0|2047.5] "min" ADIMa,ADIMb,BSM,VICM,CGM,EBCM,PCM,TCM,ECP_S,ECP_S2,ECP_X1
 SG_ LDGI1_ECMClrLgslDiagInfo : 8|1@0+ (1,0) [0|1] "" BSM,CGM,ECP_S,ECP_S2
 SG_ EngWrmUpAch : 9|1@0+ (1,0) [0|1] "" BSM,VECM,VICM,BSM_MH,CGM,EBCM,ECP_MC,LIB1,PCM,RDCM,TCCM,TCM,ECP_S,ECP_S2,ECP_X1
 SG_ EGI4_PrplSysOffTm_Inv : 10|1@0+ (1,0) [0|1] "" ADIMa,ADIMb,BSM,VICM,CGM,EBCM,PCM,TCM,ECP_S,ECP_S2,ECP_X1
 SG_ EGI4_PrplSysOffTm_DuD : 11|1@0+ (1,0) [0|1] "" BSM,VICM,CGM,EBCM,PCM,TCM,ECP_S,ECP_S2,ECP_X1
 SG_ LgslPstDTCClrDrvCyCmp : 17|1@0+ (1,0) [0|1] "" BSM,VECM,VICM,BSM_MH,CGM,EBCM,ECP_MC,PCM,TCM,ECP_S,ECP_S2,ECP_X1
 SG_ LgslDiagMxEngCltTmpRchd : 18|1@0+ (1,0) [0|1] "" BSM,VICM,BSM_MH,CGM,ECP_MC,LIB1,PCM,TCM,ECP_S,ECP_S2,ECP_X1
 SG_ LDGI1_LgslDiagStdCondsMet : 19|1@0+ (1,0) [0|1] "" BSM,VECM,VICM,CGM,EBCM,ECP_MC,LIB1,PCM,TCM,ECP_S,ECP_S2,ECP_X1
 SG_ LDGI1_LgslDiagStdCondsFltPr : 20|1@0+ (1,0) [0|1] "" BSM,VECM,VICM,CGM,EBCM,ECP_MC,LIB1,PCM,TCM,ECP_S,ECP_S2,ECP_X1
 SG_ LDGI1_LgslDiagMinEngClTmpRchd : 21|1@0+ (1,0) [0|1] "" BSM,VICM,BSM_MH,CGM,ECP_MC,LIB1,PCM,TCM,ECP_S,ECP_S2,ECP_X1
 SG_ LDGI1_LgslDiagCldStrtCondsMet : 22|1@0+ (1,0) [0|1] "" BSM,VECM,VICM,BSM_MH,CGM,LIB1,PCM,TCM,ECP_S,ECP_S2,ECP_X1
 SG_ LDGI1_LgslDiagCldStrtCondsFltPr : 23|1@0+ (1,0) [0|1] "" BSM,VECM,VICM,BSM_MH,CGM,LIB1,PCM,TCM,ECP_S,ECP_S2,ECP_X1
 SG_ SD29_CS : 50|11@0+ (1,0) [0|2047] "" BSM,CGM,ECP_S,ECP_S2
 SG_ SD29_ARC : 55|2@0+ (1,0) [0|3] "" BSM,CGM,ECP_S,ECP_S2

BO_ 683 SrlDat2_PCSM_PDU: 8 Vector__XXX
 SG_ SrlDat2_PCSM : 7|64@0+ (1,0) [0|1.84467e+019] "" ACP2_MCU,AHL_AFL,ARS,ECM,EOCM,EOCM_HC_Superset,FCM,E44,PCM

BO_ 634 SrlDat2_Prtctd_PDU: 8 Vector__XXX
 SG_ SD2P_MAC : 7|27@0+ (1,0) [0|1.34218e+008] "" ACP2_MCU,AHL_AFL,ARS,ECM,EOCM,EOCM_HC_Superset,FCM,E44,PCM
 SG_ SD2P_FCnt : 28|5@0+ (1,0) [0|31] "" ACP2_MCU,AHL_AFL,ARS,ECM,EOCM,EOCM_HC_Superset,FCM,E44,PCM
 SG_ RCIP_PwrRrClsrMtnCmdAuth : 32|2@0+ (1,0) [0|3] "" ACP2_MCU,AHL_AFL,ARS,ECM,EOCM,EOCM_HC_Superset,FCM,E44,PCM
 SG_ RCIP_ExtRrClsrRelReqAuth : 34|2@0+ (1,0) [0|3] "" ACP2_MCU,AHL_AFL,ARS,ECM,EOCM,EOCM_HC_Superset,FCM,E44,PCM
 SG_ BGI1P_OutsdAmbtLgtLvlStsAuth : 36|2@0+ (1,0) [0|2] "" ACP2_MCU,AHL_AFL,ARS,DMS,EBCM,ECM,EOCM,EOCM_HC_Superset,FCM,NVM,E44,PCM
 SG_ BGI1P_DrvrDrOpnStsAuth_Inv : 37|1@0+ (1,0) [0|1] "" ACP2_MCU,AHL_AFL,ARS,DMS,EBCM,ECM,EOCM,EOCM_HC_Superset,FCM,E44,PCM,TCM
 SG_ BGI1P_DrvrDrOpnStsAuth_DuD : 38|1@0+ (1,0) [0|1] "" ACP2_MCU,AHL_AFL,ARS,DMS,EBCM,ECM,EOCM,EOCM_HC_Superset,FCM,E44,PCM,TCM
 SG_ BGI1P_DrvrDrOpnStsAuth : 39|1@0+ (1,0) [0|1] "" ACP2_MCU,AHL_AFL,ARS,DMS,EBCM,ECM,EOCM,EOCM_HC_Superset,FCM,E44,PCM,TCM
 SG_ SD2P_FillerExtnd1 : 40|1@0+ (1,0) [0|1] "" ACP2_MCU,AHL_AFL,ARS,ECM,EOCM,EOCM_HC_Superset,FCM,E44,PCM
 SG_ PwrRrClsrModeSeltn : 42|2@0+ (1,0) [0|2] "" ACP2_MCU,AHL_AFL,ARS,ECM,EOCM,EOCM_HC_Superset,FCM,E44,PCM
 SG_ RCIP_RrClsrMtnCtlParmEnblAuth : 43|1@0+ (1,0) [0|1] "" ACP2_MCU,AHL_AFL,ARS,ECM,EOCM,EOCM_HC_Superset,FCM,E44,PCM
 SG_ RCIP_PwrRrClsrMtnReqrAuth : 46|3@0+ (1,0) [0|6] "" ACP2_MCU,AHL_AFL,ARS,ECM,EOCM,EOCM_HC_Superset,FCM,E44,PCM
 SG_ E49RmtStrtMstrEngShtdnReqdAuth : 48|1@0+ (1,0) [0|1] "" ACP2_MCU,AHL_AFL,ARS,ECM,EOCM,EOCM_HC_Superset,FCM,E44,PCM
 SG_ FrtStrgeCmptExtRelReqAuth : 49|1@0+ (1,0) [0|1] "" ACP2_MCU,AHL_AFL,ARS,ECM,EOCM,EOCM_HC_Superset,FCM,E44,PCM
 SG_ FrtStrgeCmptClsrLckSts : 51|2@0+ (1,0) [0|2] "" ACP2_MCU,AHL_AFL,ARS,ECM,EOCM,EOCM_HC_Superset,FCM,E44,PCM
 SG_ RrStrgModeSwStsAuth : 53|2@0+ (1,0) [0|3] "" ACP2_MCU,AHL_AFL,ARS,ECM,EOCM,EOCM_HC_Superset,FCM,E44,PCM
 SG_ SD2P_ARC : 55|2@0+ (1,0) [0|3] "" ACP2_MCU,AHL_AFL,ARS,ECM,EOCM,EOCM_HC_Superset,FCM,E44,PCM
 SG_ SD2P_Filler : 56|1@0+ (1,0) [0|1] "" ACP2_MCU,AHL_AFL,ARS,ECM,EOCM,EOCM_HC_Superset,FCM,E44,PCM
 SG_ PwrFrtStrgeCmptMtnReqrAuth : 59|3@0+ (1,0) [0|4] "" ACP2_MCU,AHL_AFL,ARS,ECM,EOCM,EOCM_HC_Superset,FCM,E44,PCM
 SG_ PwrFrtStrgeCmptMtnCmdAuth : 62|3@0+ (1,0) [0|4] "" ACP2_MCU,AHL_AFL,ARS,ECM,EOCM,EOCM_HC_Superset,FCM,E44,PCM
 SG_ E49RmtStrtMstrEngStrtReqAuth : 63|1@0+ (1,0) [0|1] "" ACP2_MCU,AHL_AFL,ARS,ECM,EOCM,EOCM_HC_Superset,FCM,E44,PCM

BO_ 904 SrlDat30_PCSM_PDU: 8 Vector__XXX
 SG_ SrlDat30_PCSM : 7|64@0+ (1,0) [0|1.84467e+019] "" ACP2_MCU,ADIMa,ADIMb,BSM,VICM,CGM,ECM,EOCM,EOCM_HC_Superset,E44,PCM,RDCM,TCCM,ECP_S,ECP_S2,ECP_X1

BO_ 72 SrlDat30_Prtctd_PDU: 8 Vector__XXX
 SG_ SD30P_MAC : 7|27@0+ (1,0) [0|1.34218e+008] "" ACP2_MCU,ADIMa,ADIMb,BSM,VICM,CGM,ECM,EOCM,EOCM_HC_Superset,E44,PCM,RDCM,TCCM,ECP_S,ECP_S2,ECP_X1
 SG_ SD30P_FCnt : 28|5@0+ (1,0) [0|31] "" ACP2_MCU,ADIMa,ADIMb,BSM,VICM,CGM,ECM,EOCM,EOCM_HC_Superset,E44,PCM,RDCM,TCCM,ECP_S,ECP_S2,ECP_X1
 SG_ TGIP_TrnsEgdPrFlwStAuth : 33|3@0+ (1,0) [0|3] "" ACP2_MCU,ADIMa,ADIMb,BSM,VICM,CGM,ECM,EOCM,EOCM_HC_Superset,E44,PCM,RDCM,TCCM,ECP_S,ECP_S2,ECP_X1
 SG_ TARSP_TransActlRngAuth_Inv : 34|1@0+ (1,0) [0|1] "" ACP2_MCU,ADIMa,ADIMb,BSM,VICM,CGM,ECM,EOCM,EOCM_HC_Superset,E44,PCM,RDCM,TCCM,ECP_S,ECP_S2,ECP_X1
 SG_ TARSP_TransActlRngAuth_DuD : 35|1@0+ (1,0) [0|1] "" ACP2_MCU,ADIMa,ADIMb,BSM,VICM,CGM,ECM,EOCM,EOCM_HC_Superset,E44,PCM,RDCM,TCCM,ECP_S,ECP_S2,ECP_X1
 SG_ TARSP_TransActlRngAuth : 39|4@0+ (1,0) [0|13] "" ACP2_MCU,ADIMa,ADIMb,BSM,VICM,CGM,ECM,EOCM,EOCM_HC_Superset,E44,PCM,RDCM,TCCM,ECP_S,ECP_S2,ECP_X1
 SG_ TRDP_TrnsPkRgDgLtFltAuth : 40|1@0+ (1,0) [0|1] "" ACP2_MCU,ADIMa,ADIMb,BSM,VICM,CGM,ECM,EOCM,EOCM_HC_Superset,E44,PCM,RDCM,TCCM,ECP_S,ECP_S2,ECP_X1
 SG_ TRDP_TrnsPkRgDgCtFltAuth : 41|1@0+ (1,0) [0|1] "" ACP2_MCU,ADIMa,ADIMb,BSM,VICM,CGM,ECM,EOCM,EOCM_HC_Superset,E44,PCM,RDCM,TCCM,ECP_S,ECP_S2,ECP_X1
 SG_ TRDP_TrnsNtRgDgLtFltAuth : 42|1@0+ (1,0) [0|1] "" ACP2_MCU,ADIMa,ADIMb,BSM,VICM,CGM,ECM,EOCM,EOCM_HC_Superset,E44,PCM,RDCM,TCCM,ECP_S,ECP_S2,ECP_X1
 SG_ TRDP_TrnsNtRgDgCtFltAuth : 43|1@0+ (1,0) [0|1] "" ACP2_MCU,ADIMa,ADIMb,BSM,VICM,CGM,ECM,EOCM,EOCM_HC_Superset,E44,PCM,RDCM,TCCM,ECP_S,ECP_S2,ECP_X1
 SG_ TRDP_TrnsFwDrvRDLFltAuth : 44|1@0+ (1,0) [0|1] "" ACP2_MCU,ADIMa,ADIMb,BSM,VICM,CGM,ECM,EOCM,EOCM_HC_Superset,E44,PCM,RDCM,TCCM,ECP_S,ECP_S2,ECP_X1
 SG_ TRDP_TrnsFwDrvRDCFltAuth : 45|1@0+ (1,0) [0|1] "" ACP2_MCU,ADIMa,ADIMb,BSM,VICM,CGM,ECM,EOCM,EOCM_HC_Superset,E44,PCM,RDCM,TCCM,ECP_S,ECP_S2,ECP_X1
 SG_ TGIP_TrnsEgdPrFlwStAuth_Inv : 46|1@0+ (1,0) [0|1] "" ACP2_MCU,ADIMa,ADIMb,BSM,VICM,CGM,ECM,EOCM,EOCM_HC_Superset,E44,PCM,RDCM,TCCM,ECP_S,ECP_S2,ECP_X1
 SG_ SD30P_Filler : 49|10@0+ (1,0) [0|1023] "" ACP2_MCU,ADIMa,ADIMb,BSM,VICM,CGM,ECM,EOCM,EOCM_HC_Superset,E44,PCM,RDCM,TCCM,ECP_S,ECP_S2,ECP_X1
 SG_ SD30P_ARC : 51|2@0+ (1,0) [0|3] "" ACP2_MCU,ADIMa,ADIMb,BSM,VICM,CGM,ECM,EOCM,EOCM_HC_Superset,E44,PCM,RDCM,TCCM,ECP_S,ECP_S2,ECP_X1
 SG_ TSP_TmpDrvrShfCtlActvAuth : 52|1@0+ (1,0) [0|1] "" ACP2_MCU,ADIMa,ADIMb,BSM,VICM,CGM,ECM,EOCM,EOCM_HC_Superset,E44,PCM,RDCM,TCCM,ECP_S,ECP_S2,ECP_X1
 SG_ TSP_ElecRngSeltnInDrvActvAuth : 53|1@0+ (1,0) [0|1] "" ACP2_MCU,ADIMa,ADIMb,BSM,VICM,CGM,ECM,EOCM,EOCM_HC_Superset,E44,PCM,RDCM,TCCM,ECP_S,ECP_S2,ECP_X1
 SG_ TRDP_TrnsRvRgDgLtFltAuth : 54|1@0+ (1,0) [0|1] "" ACP2_MCU,ADIMa,ADIMb,BSM,VICM,CGM,ECM,EOCM,EOCM_HC_Superset,E44,PCM,RDCM,TCCM,ECP_S,ECP_S2,ECP_X1
 SG_ TRDP_TrnsRvRgDgCtFltAuth : 55|1@0+ (1,0) [0|1] "" ACP2_MCU,ADIMa,ADIMb,BSM,VICM,CGM,ECM,EOCM,EOCM_HC_Superset,E44,PCM,RDCM,TCCM,ECP_S,ECP_S2,ECP_X1

BO_ 903 SrlDat31_PCSM_PDU: 8 Vector__XXX
 SG_ SrlDat31_PCSM : 7|64@0+ (1,0) [0|1.84467e+019] "" BSM,VICM,EBCM,ECM,PCM

BO_ 101 SrlDat31_Prtctd_PDU: 20 Vector__XXX
 SG_ SD31P_MAC : 7|32@0+ (1,0) [0|4.29497e+009] "" BSM,VICM,CGM,EBCM,ECM,PCM
 SG_ SD31P_FCnt : 39|5@0+ (1,0) [0|31] "" BSM,VICM,CGM,EBCM,ECM,PCM
 SG_ HVGI3P_HVBNegChsGndVltgAuth : 47|14@0- (0.2,0) [-1638.4|1638.2] "V" BSM,VICM,CGM,EBCM,ECM,PCM
 SG_ HVGI3P_HVBNegChsGndVltgAuth_Inv : 48|1@0+ (1,0) [0|1] "" BSM,VICM,CGM,EBCM,ECM,PCM
 SG_ HVGI3P_HVBNegChsGndVltgAuth_DuD : 49|1@0+ (1,0) [0|1] "" BSM,VICM,CGM,EBCM,ECM,PCM
 SG_ HVGI3P_HVBPosChsGndVltgAuth : 63|14@0- (0.2,0) [-1638.4|1638.2] "V" BSM,VICM,CGM,EBCM,ECM,PCM
 SG_ HVGI3P_HVBPosChsGndVltgAuth_Inv : 64|1@0+ (1,0) [0|1] "" BSM,VICM,CGM,EBCM,ECM,PCM
 SG_ HVGI3P_HVBPosChsGndVltgAuth_DuD : 65|1@0+ (1,0) [0|1] "" BSM,VICM,CGM,EBCM,ECM,PCM
 SG_ HVGI3P_HVIRatlzdVltgPriAuth : 79|13@0+ (0.2,0) [0|1638.2] "Volts" BSM,VICM,CGM,EBCM,ECM,PCM,ECP_S
 SG_ HVGI3P_HVPsvIsltnStsAuth : 81|2@0+ (1,0) [0|2] "" BSM,VICM,CGM,EBCM,ECM,PCM
 SG_ HVGI3P_HVIRatlzdVltgPriAuth_Inv : 82|1@0+ (1,0) [0|1] "" BSM,VICM,CGM,EBCM,ECM,PCM,ECP_S
 SG_ PSATDP_SecATActlAuth : 90|15@0+ (2,-22534) [-22534|43000] "Nm" BSM,VICM,CGM,EBCM,ECM,EPS,EPSb,PCM
 SG_ SD31P_FillerExtnd : 92|2@0+ (1,0) [0|3] "" BSM,VICM,CGM,EBCM,ECM,PCM
 SG_ HVGI3P_PwrtrnHVShtdnCmpltdAuth : 93|1@0+ (1,0) [0|1] "" BSM,VICM,CGM,EBCM,ECM,PCM
 SG_ HVGI3P_PwrtrnHVCntctrReqPriAuth : 95|2@0+ (1,0) [0|2] "" BSM,VICM,CGM,EBCM,ECM,PCM
 SG_ PSATDP_SecATCapMaxAuth : 106|15@0+ (2,-22534) [-22534|43000] "Nm" BSM,VICM,CGM,EBCM,ECM,PCM
 SG_ PSATDP_SecATActlAuth_Inv : 107|1@0+ (1,0) [0|1] "" BSM,VICM,CGM,EBCM,ECM,EPS,EPSb,PCM
 SG_ PSATDP_SecATCapMinAuth : 123|15@0+ (2,-22534) [-22534|43000] "Nm" BSM,VICM,CGM,EBCM,ECM,PCM
 SG_ SD31P_ARC : 137|2@0+ (1,0) [0|3] "" BSM,VICM,CGM,EBCM,ECM,PCM
 SG_ HVGI9P_ESSPrplSysReqPriAuth : 140|3@0+ (1,0) [0|4] "" BSM,VICM,CGM,EBCM,ECM,PCM
 SG_ SD31P_Filler : 151|16@0+ (1,0) [0|65535] "" BSM,VICM,CGM,EBCM,ECM,PCM

BO_ 1397 SrlDat34_PCSM_PDU: 8 Vector__XXX
 SG_ SrlDat34_PCSM : 7|64@0+ (1,0) [0|1.84467e+019] "" Vector__XXX

BO_ 881 SrlDat34_Prtctd_PDU: 8 Vector__XXX
 SG_ SD34P_MAC : 7|27@0+ (1,0) [0|1.34218e+008] "" Vector__XXX
 SG_ SD34P_FCnt : 28|5@0+ (1,0) [0|31] "" Vector__XXX
 SG_ ASDRP_LnCntrWrnExtdIndReqAuth : 34|6@0+ (1,0) [0|43] "" Vector__XXX
 SG_ ASDRP_LnCntrCtlIndReqAuth : 37|3@0+ (1,0) [0|5] "" Vector__XXX
 SG_ ACGIP_SrrndVsnRLSModeCmdAuth : 38|1@0+ (1,0) [0|1] "" Vector__XXX
 SG_ ACGIP_LnFllwFltIndcdAtBrkEnAuth : 39|1@0+ (1,0) [0|1] "" Vector__XXX
 SG_ HMIR1P_LnFllwgLHSChEvntStatAuth : 41|2@0+ (1,0) [0|2] "" Vector__XXX
 SG_ HMIR1P_LnFllwgGenChEvntStatAuth : 43|2@0+ (1,0) [0|2] "" Vector__XXX
 SG_ ASTIP_LnCntrVehStopdAuth : 44|1@0+ (1,0) [0|1] "" Vector__XXX
 SG_ SD34P_Filler : 51|12@0+ (1,0) [0|4095] "" Vector__XXX
 SG_ SD34P_ARC : 53|2@0+ (1,0) [0|3] "" Vector__XXX
 SG_ HMIR1P_LnFllwgRHSChEvntStatAuth : 55|2@0+ (1,0) [0|2] "" Vector__XXX

BO_ 902 SrlDat35_PCSM_PDU: 8 Vector__XXX
 SG_ SrlDat35_PCSM : 7|64@0+ (1,0) [0|1.84467e+019] "" EBCM,ECM,PCM,ECP_E

BO_ 526 SrlDat35_Prtctd_PDU: 16 Vector__XXX
 SG_ SD35P_MAC : 7|32@0+ (1,0) [0|4.29497e+009] "" EBCM,ECM,PCM,ECP_E
 SG_ SD35P_FCnt : 39|5@0+ (1,0) [0|31] "" EBCM,ECM,PCM,ECP_E
 SG_ ACCATRIP_TrqMagAuth : 44|19@0+ (0.125,-22534) [-22534|43001.9] "Nm" EBCM,ECM,PCM,ECP_E
 SG_ ACCATRIP_TrqDrvAstGoStatAuth : 46|2@0+ (1,0) [0|3] "" EBCM,ECM,PCM,ECP_E
 SG_ ACCATRIP_TrqActvAuth : 47|1@0+ (1,0) [0|1] "" CGM,EBCM,ECM,PCM,ECP_E
 SG_ ACCATRIP_TrqTypAuth : 57|2@0+ (1,0) [0|3] "" EBCM,ECM,PCM,ECP_E
 SG_ ACCBRP_ReqMagAuth : 69|12@0- (0.01,0) [-20.48|20.47] "" EBCM,ECM,PCM,ECP_E
 SG_ ACCBRP_ReqActvAuth : 70|1@0+ (1,0) [0|1] "" CGM,EBCM,ECM,PCM,ECP_E
 SG_ ACCBRP_ACCActvAuth : 71|1@0+ (1,0) [0|1] "" CGM,EBCM,ECM,E44,PCM,ECP_E
 SG_ ACCBRP_ReqTypAuth : 73|3@0+ (1,0) [0|6] "" EBCM,ECM,PCM,ECP_E
 SG_ ClsnImntBrkgAxlTrqRqAuth : 85|16@0+ (1,-22534) [-22534|43001] "Nm" EBCM,ECM,PCM,ECP_E
 SG_ ClsnImntBrkgAxlTrqRqActvAuth : 86|1@0+ (1,0) [0|1] "" CGM,EBCM,ECM,PCM,ECP_E
 SG_ SD35P_Filler : 97|26@0+ (1,0) [0|6.71089e+007] "" EBCM,ECM,PCM,ECP_E
 SG_ SD35P_ARC : 99|2@0+ (1,0) [0|3] "" EBCM,ECM,PCM,ECP_E
 SG_ LCCPIP_LnCntrCtlActvAuth : 100|1@0+ (1,0) [0|1] "" EBCM,ECM,PCM,ECP_E
 SG_ LCCPIP_LnCntrCtlAclPedLimRqAuth : 101|1@0+ (1,0) [0|1] "" CGM,EBCM,ECM,PCM,ECP_E

BO_ 901 SrlDat36_PCSM_PDU: 8 Vector__XXX
 SG_ SrlDat36_PCSM : 7|64@0+ (1,0) [0|1.84467e+019] "" ACP2_MCU,EOCM,EOCM_HC_Superset,FCM,E44

BA_DEF_ SG_  "SignalType" STRING ;
BA_DEF_ SG_  "SignalLongName" STRING ;
BA_DEF_ BO_  "GenMsgCycleTime" INT 0 10000;
BA_DEF_ BO_  "GenMsgSendType" ENUM "cyclicX","spontanX","cyclicIfActiveX","spontanWithDelay","cyclicAndSpontanX","cyclicAndSpontanWithDelay","spontanWithRepetition","cyclicIfActiveAndSpontanWD";
BA_DEF_ BO_  "VFrameFormat" ENUM  "StandardCAN","ExtendedCAN","reserved","reserved","reserved","reserved","reserved","reserved","reserved","reserved","reserved","reserved","reserved","reserved","StandardCAN_FD","ExtendedCAN_FD";
BA_DEF_DEF_  "SignalType" "";
BA_DEF_DEF_  "SignalLongName" "";
BA_DEF_DEF_  "GenMsgCycleTime" 0;
BA_DEF_DEF_  "GenMsgSendType" "cyclicX";
BA_DEF_DEF_  "VFrameFormat" "StandardCAN";
BA_ "VFrameFormat" BO_ 173 14;
BA_ "VFrameFormat" BO_ 166 14;
BA_ "VFrameFormat" BO_ 539 14;
BA_ "VFrameFormat" BO_ 163 14;
BA_ "VFrameFormat" BO_ 161 14;
BA_ "VFrameFormat" BO_ 160 14;
BA_ "VFrameFormat" BO_ 159 14;
BA_ "VFrameFormat" BO_ 165 14;
BA_ "VFrameFormat" BO_ 158 14;
BA_ "VFrameFormat" BO_ 908 14;
BA_ "GenMsgCycleTime" BO_ 100 12.5;
BA_ "VFrameFormat" BO_ 100 14;
BA_ "VFrameFormat" BO_ 978 14;
BA_ "GenMsgCycleTime" BO_ 157 50;
BA_ "VFrameFormat" BO_ 157 14;
BA_ "GenMsgCycleTime" BO_ 1139 3500;
BA_ "VFrameFormat" BO_ 1139 14;
BA_ "GenMsgCycleTime" BO_ 1138 1000;
BA_ "VFrameFormat" BO_ 1138 14;
BA_ "VFrameFormat" BO_ 907 14;
BA_ "GenMsgCycleTime" BO_ 47 12.5;
BA_ "VFrameFormat" BO_ 47 14;
BA_ "VFrameFormat" BO_ 906 14;
BA_ "GenMsgCycleTime" BO_ 226 25;
BA_ "VFrameFormat" BO_ 226 14;
BA_ "VFrameFormat" BO_ 905 14;
BA_ "GenMsgCycleTime" BO_ 615 100;
BA_ "VFrameFormat" BO_ 615 14;
BA_ "GenMsgCycleTime" BO_ 1404 1000;
BA_ "VFrameFormat" BO_ 1404 14;
BA_ "GenMsgCycleTime" BO_ 879 250;
BA_ "VFrameFormat" BO_ 879 14;
BA_ "GenMsgCycleTime" BO_ 1949 3500;
BA_ "VFrameFormat" BO_ 1949 14;
BA_ "GenMsgCycleTime" BO_ 1117 1000;
BA_ "VFrameFormat" BO_ 1117 14;
BA_ "GenMsgCycleTime" BO_ 1375 3500;
BA_ "VFrameFormat" BO_ 1375 14;
BA_ "GenMsgCycleTime" BO_ 1300 1000;
BA_ "VFrameFormat" BO_ 1300 14;
BA_ "GenMsgCycleTime" BO_ 1374 3500;
BA_ "VFrameFormat" BO_ 1374 14;
BA_ "GenMsgCycleTime" BO_ 1313 1000;
BA_ "VFrameFormat" BO_ 1313 14;
BA_ "VFrameFormat" BO_ 693 14;
BA_ "GenMsgCycleTime" BO_ 616 100;
BA_ "VFrameFormat" BO_ 616 14;
BA_ "GenMsgCycleTime" BO_ 705 100;
BA_ "VFrameFormat" BO_ 705 14;
BA_ "VFrameFormat" BO_ 683 14;
BA_ "GenMsgCycleTime" BO_ 634 100;
BA_ "VFrameFormat" BO_ 634 14;
BA_ "VFrameFormat" BO_ 904 14;
BA_ "GenMsgCycleTime" BO_ 72 12.5;
BA_ "VFrameFormat" BO_ 72 14;
BA_ "VFrameFormat" BO_ 903 14;
BA_ "GenMsgCycleTime" BO_ 101 12.5;
BA_ "VFrameFormat" BO_ 101 14;
BA_ "GenMsgCycleTime" BO_ 1397 1000;
BA_ "VFrameFormat" BO_ 1397 14;
BA_ "GenMsgCycleTime" BO_ 881 100;
BA_ "VFrameFormat" BO_ 881 14;
BA_ "VFrameFormat" BO_ 902 14;
BA_ "GenMsgCycleTime" BO_ 526 50;
BA_ "VFrameFormat" BO_ 526 14;
BA_ "VFrameFormat" BO_ 901 14;
BA_ "SignalLongName" SG_ 173 Sig5671 "Signal5607";
BA_ "SignalLongName" SG_ 173 Sig5670 "Signal5606";
BA_ "SignalLongName" SG_ 173 Sig5772 "Signal5608";
BA_ "SignalLongName" SG_ 173 Sig5669 "Signal5605";
BA_ "SignalType" SG_ 173 Sig5774 "ENM";
BA_ "SignalLongName" SG_ 173 Sig5774 "Signal5610";
BA_ "SignalType" SG_ 173 Sig5773 "ENM";
BA_ "SignalLongName" SG_ 173 Sig5773 "Signal5609";
BA_ "SignalType" SG_ 173 Sig5858 "ENM";
BA_ "SignalLongName" SG_ 173 Sig5858 "Signal5614";
BA_ "SignalType" SG_ 173 Sig5857 "ENM";
BA_ "SignalLongName" SG_ 173 Sig5857 "Signal5613";
BA_ "SignalType" SG_ 173 Sig5856 "ENM";
BA_ "SignalLongName" SG_ 173 Sig5856 "Signal5612";
BA_ "SignalType" SG_ 173 Sig5775 "ENM";
BA_ "SignalLongName" SG_ 173 Sig5775 "Signal5611";
BA_ "SignalLongName" SG_ 173 Sig5859 "Signal5615";
BA_ "SignalType" SG_ 173 Sig5861 "ENM";
BA_ "SignalLongName" SG_ 173 Sig5861 "Signal5617";
BA_ "SignalLongName" SG_ 173 Sig5860 "Signal5616";
BA_ "SignalLongName" SG_ 173 Sig5862 "Signal5618";
BA_ "SignalLongName" SG_ 173 Sig5863 "Signal5619";
BA_ "SignalLongName" SG_ 173 Sig5864 "Signal5620";
BA_ "SignalLongName" SG_ 173 Sig5865 "Signal5621";
BA_ "SignalLongName" SG_ 173 Sig5866 "Signal5622";
BA_ "SignalLongName" SG_ 173 Sig5867 "Signal5623";
BA_ "SignalType" SG_ 173 Sig5870 "ENM";
BA_ "SignalLongName" SG_ 173 Sig5870 "Signal5626";
BA_ "SignalType" SG_ 173 Sig5869 "ENM";
BA_ "SignalLongName" SG_ 173 Sig5869 "Signal5625";
BA_ "SignalType" SG_ 173 Sig5868 "ENM";
BA_ "SignalLongName" SG_ 173 Sig5868 "Signal5624";
BA_ "SignalLongName" SG_ 173 Sig5872 "Signal5628";
BA_ "SignalType" SG_ 173 Sig5871 "ENM";
BA_ "SignalLongName" SG_ 173 Sig5871 "Signal5627";
BA_ "SignalLongName" SG_ 173 Sig5873 "Signal5629";
BA_ "SignalLongName" SG_ 173 Sig5875 "Signal5631";
BA_ "SignalType" SG_ 173 Sig5874 "ENM";
BA_ "SignalLongName" SG_ 173 Sig5874 "Signal5630";
BA_ "SignalLongName" SG_ 173 Sig5876 "Signal5632";
BA_ "SignalLongName" SG_ 173 Sig5877 "Signal5633";
BA_ "SignalLongName" SG_ 173 Sig5878 "Signal5634";
BA_ "SignalLongName" SG_ 173 Sig5879 "Signal5635";
BA_ "SignalLongName" SG_ 173 Sig5880 "Signal5636";
BA_ "SignalType" SG_ 173 Sig5882 "ENM";
BA_ "SignalLongName" SG_ 173 Sig5882 "Signal5638";
BA_ "SignalType" SG_ 173 Sig5881 "ENM";
BA_ "SignalLongName" SG_ 173 Sig5881 "Signal5637";
BA_ "SignalType" SG_ 173 Sig5954 "ENM";
BA_ "SignalLongName" SG_ 173 Sig5954 "Signal5642";
BA_ "SignalType" SG_ 173 Sig5953 "ENM";
BA_ "SignalLongName" SG_ 173 Sig5953 "Signal5641";
BA_ "SignalType" SG_ 173 Sig5952 "ENM";
BA_ "SignalLongName" SG_ 173 Sig5952 "Signal5643";
BA_ "SignalType" SG_ 173 Sig5950 "ENM";
BA_ "SignalLongName" SG_ 173 Sig5950 "Signal5640";
BA_ "SignalType" SG_ 173 Sig5949 "ENM";
BA_ "SignalLongName" SG_ 173 Sig5949 "Signal5639";
BA_ "SignalLongName" SG_ 173 Sig5976 "Signal5646";
BA_ "SignalType" SG_ 173 Sig5955 "ENM";
BA_ "SignalLongName" SG_ 173 Sig5955 "Signal5644";
BA_ "SignalLongName" SG_ 173 Sig5980 "Signal5649";
BA_ "SignalType" SG_ 173 Sig5979 "ENM";
BA_ "SignalLongName" SG_ 173 Sig5979 "Signal5648";
BA_ "SignalType" SG_ 173 Sig5978 "ENM";
BA_ "SignalLongName" SG_ 173 Sig5978 "Signal5647";
BA_ "SignalType" SG_ 173 Sig5977 "ENM";
BA_ "SignalLongName" SG_ 173 Sig5977 "Signal5645";
BA_ "SignalLongName" SG_ 173 Sig5984 "Signal5651";
BA_ "SignalType" SG_ 173 Sig5981 "ENM";
BA_ "SignalLongName" SG_ 173 Sig5981 "Signal5650";
BA_ "SignalLongName" SG_ 173 Sig5985 "Signal5652";
BA_ "SignalLongName" SG_ 173 Sig5986 "Signal5653";
BA_ "SignalLongName" SG_ 173 Sig5987 "Signal5654";
BA_ "SignalLongName" SG_ 173 Sig5988 "Signal5655";
BA_ "SignalLongName" SG_ 173 Sig5989 "Signal5657";
BA_ "SignalLongName" SG_ 173 Sig5990 "Signal5658";
BA_ "SignalLongName" SG_ 173 Sig5991 "Signal5659";
BA_ "SignalLongName" SG_ 173 Sig5992 "Signal5660";
BA_ "SignalLongName" SG_ 173 Sig5993 "Signal5661";
BA_ "SignalLongName" SG_ 173 Sig5994 "Signal5656";
BA_ "SignalLongName" SG_ 173 Sig6014 "Signal5663";
BA_ "SignalType" SG_ 173 Sig5995 "ENM";
BA_ "SignalLongName" SG_ 173 Sig5995 "Signal5662";
BA_ "SignalLongName" SG_ 173 Sig5668 "Signal5604";
BA_ "SignalLongName" SG_ 166 Sig5681 "Signal5964";
BA_ "SignalLongName" SG_ 166 Sig5680 "Signal5963";
BA_ "SignalLongName" SG_ 166 Sig5682 "Signal5965";
BA_ "SignalLongName" SG_ 166 Sig5780 "Signal5967";
BA_ "SignalLongName" SG_ 166 Sig5788 "Signal5966";
BA_ "SignalLongName" SG_ 166 Sig5796 "Signal5968";
BA_ "SignalLongName" SG_ 166 Sig5804 "Signal5969";
BA_ "SignalLongName" SG_ 166 Sig5812 "Signal5970";
BA_ "SignalLongName" SG_ 166 Sig5820 "Signal5971";
BA_ "SignalLongName" SG_ 166 Sig5828 "Signal5972";
BA_ "SignalLongName" SG_ 166 Sig5836 "Signal5973";
BA_ "SignalLongName" SG_ 166 Sig5844 "Signal5974";
BA_ "SignalLongName" SG_ 166 Sig5852 "Signal5975";
BA_ "SignalLongName" SG_ 166 Sig5923 "Signal5977";
BA_ "SignalType" SG_ 166 Sig5922 "ENM";
BA_ "SignalLongName" SG_ 166 Sig5922 "Signal5976";
BA_ "SignalLongName" SG_ 166 Sig5924 "Signal5978";
BA_ "SignalLongName" SG_ 166 Sig5925 "Signal5979";
BA_ "SignalLongName" SG_ 166 Sig5926 "Signal5980";
BA_ "SignalLongName" SG_ 166 Sig5927 "Signal5981";
BA_ "SignalLongName" SG_ 166 Sig5928 "Signal5982";
BA_ "SignalType" SG_ 166 Sig5930 "ENM";
BA_ "SignalLongName" SG_ 166 Sig5930 "Signal5984";
BA_ "SignalType" SG_ 166 Sig5929 "ENM";
BA_ "SignalLongName" SG_ 166 Sig5929 "Signal5983";
BA_ "SignalLongName" SG_ 166 Sig5932 "Signal5986";
BA_ "SignalType" SG_ 166 Sig5931 "ENM";
BA_ "SignalLongName" SG_ 166 Sig5931 "Signal5985";
BA_ "SignalLongName" SG_ 166 Sig5933 "Signal5987";
BA_ "SignalLongName" SG_ 166 Sig5934 "Signal5988";
BA_ "SignalLongName" SG_ 166 Sig5935 "Signal5989";
BA_ "SignalLongName" SG_ 166 Sig5936 "Signal5990";
BA_ "SignalLongName" SG_ 166 Sig5937 "Signal5991";
BA_ "SignalType" SG_ 166 Sig5939 "ENM";
BA_ "SignalLongName" SG_ 166 Sig5939 "Signal5993";
BA_ "SignalType" SG_ 166 Sig5938 "ENM";
BA_ "SignalLongName" SG_ 166 Sig5938 "Signal5992";
BA_ "SignalLongName" SG_ 166 Sig5941 "Signal5995";
BA_ "SignalType" SG_ 166 Sig5940 "ENM";
BA_ "SignalLongName" SG_ 166 Sig5940 "Signal5994";
BA_ "SignalLongName" SG_ 166 Sig5942 "Signal5996";
BA_ "SignalLongName" SG_ 166 Sig5943 "Signal5997";
BA_ "SignalLongName" SG_ 166 Sig5944 "Signal5998";
BA_ "SignalLongName" SG_ 166 Sig5945 "Signal5999";
BA_ "SignalLongName" SG_ 166 Sig5946 "Signal6000";
BA_ "SignalType" SG_ 166 Sig5948 "ENM";
BA_ "SignalLongName" SG_ 166 Sig5948 "Signal6002";
BA_ "SignalType" SG_ 166 Sig5947 "ENM";
BA_ "SignalLongName" SG_ 166 Sig5947 "Signal6001";
BA_ "SignalLongName" SG_ 539 Sig6851 "Signal6063";
BA_ "SignalLongName" SG_ 163 Sig5688 "Signal6065";
BA_ "SignalLongName" SG_ 163 Sig5687 "Signal6064";
BA_ "SignalLongName" SG_ 163 Sig6318 "Signal6068";
BA_ "SignalType" SG_ 163 Sig6317 "ENM";
BA_ "SignalLongName" SG_ 163 Sig6317 "Signal6067";
BA_ "SignalType" SG_ 163 Sig6316 "ENM";
BA_ "SignalLongName" SG_ 163 Sig6316 "Signal6066";
BA_ "SignalLongName" SG_ 163 Sig6319 "Signal6069";
BA_ "SignalLongName" SG_ 163 Sig6321 "Signal6071";
BA_ "SignalType" SG_ 163 Sig6320 "ENM";
BA_ "SignalLongName" SG_ 163 Sig6320 "Signal6070";
BA_ "SignalLongName" SG_ 163 Sig6322 "Signal6072";
BA_ "SignalLongName" SG_ 163 Sig6323 "Signal6073";
BA_ "SignalLongName" SG_ 163 Sig6324 "Signal6074";
BA_ "SignalLongName" SG_ 163 Sig6325 "Signal6075";
BA_ "SignalLongName" SG_ 163 Sig6326 "Signal6076";
BA_ "SignalLongName" SG_ 163 Sig6467 "Signal6080";
BA_ "SignalType" SG_ 163 Sig6328 "ENM";
BA_ "SignalLongName" SG_ 163 Sig6328 "Signal6078";
BA_ "SignalType" SG_ 163 Sig6327 "ENM";
BA_ "SignalLongName" SG_ 163 Sig6327 "Signal6077";
BA_ "SignalType" SG_ 163 Sig6470 "ENM";
BA_ "SignalLongName" SG_ 163 Sig6470 "Signal6082";
BA_ "SignalType" SG_ 163 Sig6469 "ENM";
BA_ "SignalLongName" SG_ 163 Sig6469 "Signal6081";
BA_ "SignalType" SG_ 163 Sig6468 "ENM";
BA_ "SignalLongName" SG_ 163 Sig6468 "Signal6079";
BA_ "SignalType" SG_ 163 Sig6472 "ENM";
BA_ "SignalLongName" SG_ 163 Sig6472 "Signal6084";
BA_ "SignalLongName" SG_ 163 Sig6471 "Signal6083";
BA_ "SignalLongName" SG_ 163 Sig6475 "Signal6085";
BA_ "SignalLongName" SG_ 163 Sig6476 "Signal6086";
BA_ "SignalLongName" SG_ 163 Sig6477 "Signal6087";
BA_ "SignalLongName" SG_ 163 Sig6478 "Signal6088";
BA_ "SignalLongName" SG_ 163 Sig6479 "Signal6089";
BA_ "SignalLongName" SG_ 163 Sig6480 "Signal6090";
BA_ "SignalLongName" SG_ 163 Sig6481 "Signal6091";
BA_ "SignalLongName" SG_ 163 Sig6482 "Signal6092";
BA_ "SignalLongName" SG_ 163 Sig6483 "Signal6093";
BA_ "SignalLongName" SG_ 163 Sig6484 "Signal6094";
BA_ "SignalType" SG_ 163 Sig6486 "ENM";
BA_ "SignalLongName" SG_ 163 Sig6486 "Signal6095";
BA_ "SignalType" SG_ 163 Sig6488 "ENM";
BA_ "SignalLongName" SG_ 163 Sig6488 "Signal6096";
BA_ "SignalLongName" SG_ 163 Sig6487 "Signal6097";
BA_ "SignalLongName" SG_ 163 Sig6491 "Signal6100";
BA_ "SignalType" SG_ 163 Sig6490 "ENM";
BA_ "SignalLongName" SG_ 163 Sig6490 "Signal6099";
BA_ "SignalType" SG_ 163 Sig6489 "ENM";
BA_ "SignalLongName" SG_ 163 Sig6489 "Signal6098";
BA_ "SignalLongName" SG_ 163 Sig6495 "Signal6102";
BA_ "SignalType" SG_ 163 Sig6492 "ENM";
BA_ "SignalLongName" SG_ 163 Sig6492 "Signal6101";
BA_ "SignalLongName" SG_ 163 Sig6496 "Signal6103";
BA_ "SignalLongName" SG_ 163 Sig6497 "Signal6104";
BA_ "SignalLongName" SG_ 163 Sig6498 "Signal6105";
BA_ "SignalLongName" SG_ 163 Sig6499 "Signal6106";
BA_ "SignalLongName" SG_ 163 Sig6500 "Signal6108";
BA_ "SignalLongName" SG_ 163 Sig6501 "Signal6109";
BA_ "SignalLongName" SG_ 163 Sig6502 "Signal6110";
BA_ "SignalLongName" SG_ 163 Sig6503 "Signal6111";
BA_ "SignalLongName" SG_ 163 Sig6504 "Signal6112";
BA_ "SignalLongName" SG_ 163 Sig6505 "Signal6107";
BA_ "SignalLongName" SG_ 163 Sig6507 "Signal6115";
BA_ "SignalType" SG_ 163 Sig6506 "ENM";
BA_ "SignalLongName" SG_ 163 Sig6506 "Signal6113";
BA_ "SignalType" SG_ 163 Sig6510 "ENM";
BA_ "SignalLongName" SG_ 163 Sig6510 "Signal6117";
BA_ "SignalType" SG_ 163 Sig6509 "ENM";
BA_ "SignalLongName" SG_ 163 Sig6509 "Signal6116";
BA_ "SignalType" SG_ 163 Sig6508 "ENM";
BA_ "SignalLongName" SG_ 163 Sig6508 "Signal6114";
BA_ "SignalType" SG_ 163 Sig6512 "ENM";
BA_ "SignalLongName" SG_ 163 Sig6512 "Signal6119";
BA_ "SignalLongName" SG_ 163 Sig6511 "Signal6118";
BA_ "SignalLongName" SG_ 163 Sig6515 "Signal6120";
BA_ "SignalLongName" SG_ 163 Sig6516 "Signal6121";
BA_ "SignalLongName" SG_ 163 Sig6517 "Signal6122";
BA_ "SignalLongName" SG_ 163 Sig6518 "Signal6123";
BA_ "SignalLongName" SG_ 163 Sig6519 "Signal6124";
BA_ "SignalLongName" SG_ 163 Sig6520 "Signal6126";
BA_ "SignalLongName" SG_ 163 Sig6521 "Signal6127";
BA_ "SignalLongName" SG_ 163 Sig6522 "Signal6128";
BA_ "SignalLongName" SG_ 163 Sig6523 "Signal6129";
BA_ "SignalLongName" SG_ 163 Sig6524 "Signal6130";
BA_ "SignalLongName" SG_ 163 Sig6525 "Signal6125";
BA_ "SignalType" SG_ 163 Sig6526 "ENM";
BA_ "SignalLongName" SG_ 163 Sig6526 "Signal6131";
BA_ "SignalLongName" SG_ 163 Sig6545 "Signal6132";
BA_ "SignalLongName" SG_ 161 Sig5690 "Signal6134";
BA_ "SignalLongName" SG_ 161 Sig5689 "Signal6133";
BA_ "SignalLongName" SG_ 161 Sig6331 "Signal6137";
BA_ "SignalType" SG_ 161 Sig6330 "ENM";
BA_ "SignalLongName" SG_ 161 Sig6330 "Signal6136";
BA_ "SignalType" SG_ 161 Sig6329 "ENM";
BA_ "SignalLongName" SG_ 161 Sig6329 "Signal6135";
BA_ "SignalLongName" SG_ 161 Sig6332 "Signal6138";
BA_ "SignalLongName" SG_ 161 Sig6334 "Signal6140";
BA_ "SignalType" SG_ 161 Sig6333 "ENM";
BA_ "SignalLongName" SG_ 161 Sig6333 "Signal6139";
BA_ "SignalLongName" SG_ 161 Sig6335 "Signal6141";
BA_ "SignalLongName" SG_ 161 Sig6336 "Signal6142";
BA_ "SignalLongName" SG_ 161 Sig6337 "Signal6143";
BA_ "SignalLongName" SG_ 161 Sig6338 "Signal6144";
BA_ "SignalLongName" SG_ 161 Sig6339 "Signal6145";
BA_ "SignalLongName" SG_ 161 Sig6527 "Signal6149";
BA_ "SignalType" SG_ 161 Sig6341 "ENM";
BA_ "SignalLongName" SG_ 161 Sig6341 "Signal6147";
BA_ "SignalType" SG_ 161 Sig6340 "ENM";
BA_ "SignalLongName" SG_ 161 Sig6340 "Signal6146";
BA_ "SignalType" SG_ 161 Sig6530 "ENM";
BA_ "SignalLongName" SG_ 161 Sig6530 "Signal6151";
BA_ "SignalType" SG_ 161 Sig6529 "ENM";
BA_ "SignalLongName" SG_ 161 Sig6529 "Signal6150";
BA_ "SignalType" SG_ 161 Sig6528 "ENM";
BA_ "SignalLongName" SG_ 161 Sig6528 "Signal6148";
BA_ "SignalType" SG_ 161 Sig6532 "ENM";
BA_ "SignalLongName" SG_ 161 Sig6532 "Signal6153";
BA_ "SignalLongName" SG_ 161 Sig6531 "Signal6152";
BA_ "SignalLongName" SG_ 161 Sig6535 "Signal6154";
BA_ "SignalLongName" SG_ 161 Sig6536 "Signal6155";
BA_ "SignalLongName" SG_ 161 Sig6537 "Signal6156";
BA_ "SignalLongName" SG_ 161 Sig6538 "Signal6157";
BA_ "SignalLongName" SG_ 161 Sig6539 "Signal6158";
BA_ "SignalLongName" SG_ 161 Sig6540 "Signal6159";
BA_ "SignalLongName" SG_ 161 Sig6541 "Signal6160";
BA_ "SignalLongName" SG_ 161 Sig6542 "Signal6161";
BA_ "SignalLongName" SG_ 161 Sig6543 "Signal6162";
BA_ "SignalLongName" SG_ 161 Sig6544 "Signal6163";
BA_ "SignalType" SG_ 161 Sig6546 "ENM";
BA_ "SignalLongName" SG_ 161 Sig6546 "Signal6164";
BA_ "SignalType" SG_ 161 Sig6548 "ENM";
BA_ "SignalLongName" SG_ 161 Sig6548 "Signal6165";
BA_ "SignalLongName" SG_ 161 Sig6547 "Signal6166";
BA_ "SignalLongName" SG_ 161 Sig6551 "Signal6169";
BA_ "SignalType" SG_ 161 Sig6550 "ENM";
BA_ "SignalLongName" SG_ 161 Sig6550 "Signal6168";
BA_ "SignalType" SG_ 161 Sig6549 "ENM";
BA_ "SignalLongName" SG_ 161 Sig6549 "Signal6167";
BA_ "SignalLongName" SG_ 161 Sig6555 "Signal6171";
BA_ "SignalType" SG_ 161 Sig6552 "ENM";
BA_ "SignalLongName" SG_ 161 Sig6552 "Signal6170";
BA_ "SignalLongName" SG_ 161 Sig6556 "Signal6172";
BA_ "SignalLongName" SG_ 161 Sig6557 "Signal6173";
BA_ "SignalLongName" SG_ 161 Sig6558 "Signal6174";
BA_ "SignalLongName" SG_ 161 Sig6559 "Signal6175";
BA_ "SignalLongName" SG_ 161 Sig6560 "Signal6177";
BA_ "SignalLongName" SG_ 161 Sig6561 "Signal6178";
BA_ "SignalLongName" SG_ 161 Sig6562 "Signal6179";
BA_ "SignalLongName" SG_ 161 Sig6563 "Signal6180";
BA_ "SignalLongName" SG_ 161 Sig6564 "Signal6181";
BA_ "SignalLongName" SG_ 161 Sig6565 "Signal6176";
BA_ "SignalLongName" SG_ 161 Sig6567 "Signal6184";
BA_ "SignalType" SG_ 161 Sig6566 "ENM";
BA_ "SignalLongName" SG_ 161 Sig6566 "Signal6182";
BA_ "SignalType" SG_ 161 Sig6570 "ENM";
BA_ "SignalLongName" SG_ 161 Sig6570 "Signal6186";
BA_ "SignalType" SG_ 161 Sig6569 "ENM";
BA_ "SignalLongName" SG_ 161 Sig6569 "Signal6185";
BA_ "SignalType" SG_ 161 Sig6568 "ENM";
BA_ "SignalLongName" SG_ 161 Sig6568 "Signal6183";
BA_ "SignalType" SG_ 161 Sig6572 "ENM";
BA_ "SignalLongName" SG_ 161 Sig6572 "Signal6188";
BA_ "SignalLongName" SG_ 161 Sig6571 "Signal6187";
BA_ "SignalLongName" SG_ 161 Sig6575 "Signal6189";
BA_ "SignalLongName" SG_ 161 Sig6576 "Signal6190";
BA_ "SignalLongName" SG_ 161 Sig6577 "Signal6191";
BA_ "SignalLongName" SG_ 161 Sig6578 "Signal6192";
BA_ "SignalLongName" SG_ 161 Sig6579 "Signal6193";
BA_ "SignalLongName" SG_ 161 Sig6580 "Signal6195";
BA_ "SignalLongName" SG_ 161 Sig6581 "Signal6196";
BA_ "SignalLongName" SG_ 161 Sig6582 "Signal6197";
BA_ "SignalLongName" SG_ 161 Sig6583 "Signal6198";
BA_ "SignalLongName" SG_ 161 Sig6584 "Signal6199";
BA_ "SignalLongName" SG_ 161 Sig6585 "Signal6194";
BA_ "SignalType" SG_ 161 Sig6586 "ENM";
BA_ "SignalLongName" SG_ 161 Sig6586 "Signal6200";
BA_ "SignalLongName" SG_ 161 Sig6605 "Signal6201";
BA_ "SignalLongName" SG_ 160 Sig5692 "Signal6203";
BA_ "SignalLongName" SG_ 160 Sig5691 "Signal6202";
BA_ "SignalLongName" SG_ 160 Sig6344 "Signal6206";
BA_ "SignalType" SG_ 160 Sig6343 "ENM";
BA_ "SignalLongName" SG_ 160 Sig6343 "Signal6205";
BA_ "SignalType" SG_ 160 Sig6342 "ENM";
BA_ "SignalLongName" SG_ 160 Sig6342 "Signal6204";
BA_ "SignalLongName" SG_ 160 Sig6345 "Signal6207";
BA_ "SignalLongName" SG_ 160 Sig6347 "Signal6209";
BA_ "SignalType" SG_ 160 Sig6346 "ENM";
BA_ "SignalLongName" SG_ 160 Sig6346 "Signal6208";
BA_ "SignalLongName" SG_ 160 Sig6348 "Signal6210";
BA_ "SignalLongName" SG_ 160 Sig6349 "Signal6211";
BA_ "SignalLongName" SG_ 160 Sig6350 "Signal6212";
BA_ "SignalLongName" SG_ 160 Sig6351 "Signal6213";
BA_ "SignalLongName" SG_ 160 Sig6352 "Signal6214";
BA_ "SignalLongName" SG_ 160 Sig6427 "Signal6218";
BA_ "SignalType" SG_ 160 Sig6354 "ENM";
BA_ "SignalLongName" SG_ 160 Sig6354 "Signal6216";
BA_ "SignalType" SG_ 160 Sig6353 "ENM";
BA_ "SignalLongName" SG_ 160 Sig6353 "Signal6215";
BA_ "SignalType" SG_ 160 Sig6430 "ENM";
BA_ "SignalLongName" SG_ 160 Sig6430 "Signal6220";
BA_ "SignalType" SG_ 160 Sig6429 "ENM";
BA_ "SignalLongName" SG_ 160 Sig6429 "Signal6219";
BA_ "SignalType" SG_ 160 Sig6428 "ENM";
BA_ "SignalLongName" SG_ 160 Sig6428 "Signal6217";
BA_ "SignalType" SG_ 160 Sig6432 "ENM";
BA_ "SignalLongName" SG_ 160 Sig6432 "Signal6222";
BA_ "SignalLongName" SG_ 160 Sig6431 "Signal6221";
BA_ "SignalLongName" SG_ 160 Sig6435 "Signal6223";
BA_ "SignalLongName" SG_ 160 Sig6436 "Signal6224";
BA_ "SignalLongName" SG_ 160 Sig6437 "Signal6225";
BA_ "SignalLongName" SG_ 160 Sig6438 "Signal6226";
BA_ "SignalLongName" SG_ 160 Sig6439 "Signal6227";
BA_ "SignalLongName" SG_ 160 Sig6440 "Signal6229";
BA_ "SignalLongName" SG_ 160 Sig6441 "Signal6230";
BA_ "SignalLongName" SG_ 160 Sig6442 "Signal6231";
BA_ "SignalLongName" SG_ 160 Sig6443 "Signal6232";
BA_ "SignalLongName" SG_ 160 Sig6444 "Signal6233";
BA_ "SignalLongName" SG_ 160 Sig6445 "Signal6228";
BA_ "SignalType" SG_ 160 Sig6446 "ENM";
BA_ "SignalLongName" SG_ 160 Sig6446 "Signal6234";
BA_ "SignalType" SG_ 160 Sig6588 "ENM";
BA_ "SignalLongName" SG_ 160 Sig6588 "Signal6235";
BA_ "SignalLongName" SG_ 160 Sig6587 "Signal6236";
BA_ "SignalLongName" SG_ 160 Sig6591 "Signal6239";
BA_ "SignalType" SG_ 160 Sig6590 "ENM";
BA_ "SignalLongName" SG_ 160 Sig6590 "Signal6238";
BA_ "SignalType" SG_ 160 Sig6589 "ENM";
BA_ "SignalLongName" SG_ 160 Sig6589 "Signal6237";
BA_ "SignalLongName" SG_ 160 Sig6595 "Signal6241";
BA_ "SignalType" SG_ 160 Sig6592 "ENM";
BA_ "SignalLongName" SG_ 160 Sig6592 "Signal6240";
BA_ "SignalLongName" SG_ 160 Sig6596 "Signal6242";
BA_ "SignalLongName" SG_ 160 Sig6597 "Signal6243";
BA_ "SignalLongName" SG_ 160 Sig6598 "Signal6244";
BA_ "SignalLongName" SG_ 160 Sig6599 "Signal6245";
BA_ "SignalLongName" SG_ 160 Sig6600 "Signal6246";
BA_ "SignalLongName" SG_ 160 Sig6601 "Signal6247";
BA_ "SignalLongName" SG_ 160 Sig6602 "Signal6248";
BA_ "SignalLongName" SG_ 160 Sig6603 "Signal6249";
BA_ "SignalLongName" SG_ 160 Sig6604 "Signal6250";
BA_ "SignalLongName" SG_ 160 Sig6607 "Signal6253";
BA_ "SignalType" SG_ 160 Sig6606 "ENM";
BA_ "SignalLongName" SG_ 160 Sig6606 "Signal6251";
BA_ "SignalType" SG_ 160 Sig6610 "ENM";
BA_ "SignalLongName" SG_ 160 Sig6610 "Signal6255";
BA_ "SignalType" SG_ 160 Sig6609 "ENM";
BA_ "SignalLongName" SG_ 160 Sig6609 "Signal6254";
BA_ "SignalType" SG_ 160 Sig6608 "ENM";
BA_ "SignalLongName" SG_ 160 Sig6608 "Signal6252";
BA_ "SignalType" SG_ 160 Sig6612 "ENM";
BA_ "SignalLongName" SG_ 160 Sig6612 "Signal6257";
BA_ "SignalLongName" SG_ 160 Sig6611 "Signal6256";
BA_ "SignalLongName" SG_ 160 Sig6615 "Signal6258";
BA_ "SignalLongName" SG_ 160 Sig6616 "Signal6259";
BA_ "SignalLongName" SG_ 160 Sig6617 "Signal6260";
BA_ "SignalLongName" SG_ 160 Sig6618 "Signal6261";
BA_ "SignalLongName" SG_ 160 Sig6619 "Signal6262";
BA_ "SignalLongName" SG_ 160 Sig6620 "Signal6264";
BA_ "SignalLongName" SG_ 160 Sig6621 "Signal6265";
BA_ "SignalLongName" SG_ 160 Sig6622 "Signal6266";
BA_ "SignalLongName" SG_ 160 Sig6623 "Signal6267";
BA_ "SignalLongName" SG_ 160 Sig6624 "Signal6268";
BA_ "SignalLongName" SG_ 160 Sig6625 "Signal6263";
BA_ "SignalType" SG_ 160 Sig6626 "ENM";
BA_ "SignalLongName" SG_ 160 Sig6626 "Signal6269";
BA_ "SignalLongName" SG_ 159 Sig5694 "Signal6271";
BA_ "SignalLongName" SG_ 159 Sig5693 "Signal6270";
BA_ "SignalType" SG_ 159 Sig6206 "ENM";
BA_ "SignalLongName" SG_ 159 Sig6206 "Signal6280";
BA_ "SignalType" SG_ 159 Sig6205 "ENM";
BA_ "SignalLongName" SG_ 159 Sig6205 "Signal6279";
BA_ "SignalType" SG_ 159 Sig6208 "ENM";
BA_ "SignalLongName" SG_ 159 Sig6208 "Signal6282";
BA_ "SignalLongName" SG_ 159 Sig6207 "Signal6281";
BA_ "SignalLongName" SG_ 159 Sig6210 "Signal6283";
BA_ "SignalType" SG_ 159 Sig6212 "ENM";
BA_ "SignalLongName" SG_ 159 Sig6212 "Signal6285";
BA_ "SignalType" SG_ 159 Sig6211 "ENM";
BA_ "SignalLongName" SG_ 159 Sig6211 "Signal6284";
BA_ "SignalLongName" SG_ 159 Sig6215 "Signal6274";
BA_ "SignalType" SG_ 159 Sig6214 "ENM";
BA_ "SignalLongName" SG_ 159 Sig6214 "Signal6273";
BA_ "SignalType" SG_ 159 Sig6213 "ENM";
BA_ "SignalLongName" SG_ 159 Sig6213 "Signal6272";
BA_ "SignalLongName" SG_ 159 Sig6218 "Signal6276";
BA_ "SignalType" SG_ 159 Sig6216 "ENM";
BA_ "SignalLongName" SG_ 159 Sig6216 "Signal6275";
BA_ "SignalType" SG_ 159 Sig6221 "ENM";
BA_ "SignalLongName" SG_ 159 Sig6221 "Signal6286";
BA_ "SignalType" SG_ 159 Sig6220 "ENM";
BA_ "SignalLongName" SG_ 159 Sig6220 "Signal6278";
BA_ "SignalType" SG_ 159 Sig6219 "ENM";
BA_ "SignalLongName" SG_ 159 Sig6219 "Signal6277";
BA_ "SignalLongName" SG_ 159 Sig6223 "Signal6288";
BA_ "SignalType" SG_ 159 Sig6222 "ENM";
BA_ "SignalLongName" SG_ 159 Sig6222 "Signal6287";
BA_ "SignalLongName" SG_ 159 Sig6226 "Signal6290";
BA_ "SignalType" SG_ 159 Sig6224 "ENM";
BA_ "SignalLongName" SG_ 159 Sig6224 "Signal6289";
BA_ "SignalType" SG_ 159 Sig6227 "ENM";
BA_ "SignalLongName" SG_ 159 Sig6227 "Signal6291";
BA_ "SignalLongName" SG_ 159 Sig6231 "Signal6295";
BA_ "SignalType" SG_ 159 Sig6230 "ENM";
BA_ "SignalLongName" SG_ 159 Sig6230 "Signal6294";
BA_ "SignalType" SG_ 159 Sig6229 "ENM";
BA_ "SignalLongName" SG_ 159 Sig6229 "Signal6293";
BA_ "SignalType" SG_ 159 Sig6228 "ENM";
BA_ "SignalLongName" SG_ 159 Sig6228 "Signal6292";
BA_ "SignalType" SG_ 159 Sig6232 "ENM";
BA_ "SignalLongName" SG_ 159 Sig6232 "Signal6296";
BA_ "SignalLongName" SG_ 159 Sig6234 "Signal6297";
BA_ "SignalType" SG_ 159 Sig6236 "ENM";
BA_ "SignalLongName" SG_ 159 Sig6236 "Signal6299";
BA_ "SignalType" SG_ 159 Sig6235 "ENM";
BA_ "SignalLongName" SG_ 159 Sig6235 "Signal6298";
BA_ "SignalLongName" SG_ 159 Sig6239 "Signal6302";
BA_ "SignalType" SG_ 159 Sig6238 "ENM";
BA_ "SignalLongName" SG_ 159 Sig6238 "Signal6301";
BA_ "SignalType" SG_ 159 Sig6237 "ENM";
BA_ "SignalLongName" SG_ 159 Sig6237 "Signal6300";
BA_ "SignalLongName" SG_ 159 Sig6242 "Signal6304";
BA_ "SignalType" SG_ 159 Sig6240 "ENM";
BA_ "SignalLongName" SG_ 159 Sig6240 "Signal6303";
BA_ "SignalType" SG_ 159 Sig6246 "ENM";
BA_ "SignalLongName" SG_ 159 Sig6246 "Signal6308";
BA_ "SignalType" SG_ 159 Sig6245 "ENM";
BA_ "SignalLongName" SG_ 159 Sig6245 "Signal6307";
BA_ "SignalType" SG_ 159 Sig6244 "ENM";
BA_ "SignalLongName" SG_ 159 Sig6244 "Signal6306";
BA_ "SignalType" SG_ 159 Sig6243 "ENM";
BA_ "SignalLongName" SG_ 159 Sig6243 "Signal6305";
BA_ "SignalLongName" SG_ 159 Sig6247 "Signal6309";
BA_ "SignalLongName" SG_ 159 Sig6250 "Signal6311";
BA_ "SignalType" SG_ 159 Sig6248 "ENM";
BA_ "SignalLongName" SG_ 159 Sig6248 "Signal6310";
BA_ "SignalType" SG_ 159 Sig6251 "ENM";
BA_ "SignalLongName" SG_ 159 Sig6251 "Signal6312";
BA_ "SignalLongName" SG_ 159 Sig6255 "Signal6316";
BA_ "SignalType" SG_ 159 Sig6254 "ENM";
BA_ "SignalLongName" SG_ 159 Sig6254 "Signal6315";
BA_ "SignalType" SG_ 159 Sig6253 "ENM";
BA_ "SignalLongName" SG_ 159 Sig6253 "Signal6314";
BA_ "SignalType" SG_ 159 Sig6252 "ENM";
BA_ "SignalLongName" SG_ 159 Sig6252 "Signal6313";
BA_ "SignalLongName" SG_ 159 Sig6258 "Signal6318";
BA_ "SignalType" SG_ 159 Sig6256 "ENM";
BA_ "SignalLongName" SG_ 159 Sig6256 "Signal6317";
BA_ "SignalType" SG_ 159 Sig6261 "ENM";
BA_ "SignalLongName" SG_ 159 Sig6261 "Signal6321";
BA_ "SignalType" SG_ 159 Sig6260 "ENM";
BA_ "SignalLongName" SG_ 159 Sig6260 "Signal6320";
BA_ "SignalType" SG_ 159 Sig6259 "ENM";
BA_ "SignalLongName" SG_ 159 Sig6259 "Signal6319";
BA_ "SignalLongName" SG_ 159 Sig6263 "Signal6323";
BA_ "SignalType" SG_ 159 Sig6262 "ENM";
BA_ "SignalLongName" SG_ 159 Sig6262 "Signal6322";
BA_ "SignalLongName" SG_ 159 Sig6266 "Signal6325";
BA_ "SignalType" SG_ 159 Sig6264 "ENM";
BA_ "SignalLongName" SG_ 159 Sig6264 "Signal6324";
BA_ "SignalType" SG_ 159 Sig6267 "ENM";
BA_ "SignalLongName" SG_ 159 Sig6267 "Signal6326";
BA_ "SignalType" SG_ 159 Sig6270 "ENM";
BA_ "SignalLongName" SG_ 159 Sig6270 "Signal6329";
BA_ "SignalType" SG_ 159 Sig6269 "ENM";
BA_ "SignalLongName" SG_ 159 Sig6269 "Signal6328";
BA_ "SignalType" SG_ 159 Sig6268 "ENM";
BA_ "SignalLongName" SG_ 159 Sig6268 "Signal6327";
BA_ "SignalType" SG_ 159 Sig6272 "ENM";
BA_ "SignalLongName" SG_ 159 Sig6272 "Signal6331";
BA_ "SignalLongName" SG_ 159 Sig6271 "Signal6330";
BA_ "SignalLongName" SG_ 159 Sig6274 "Signal6332";
BA_ "SignalType" SG_ 159 Sig6276 "ENM";
BA_ "SignalLongName" SG_ 159 Sig6276 "Signal6334";
BA_ "SignalType" SG_ 159 Sig6275 "ENM";
BA_ "SignalLongName" SG_ 159 Sig6275 "Signal6333";
BA_ "SignalLongName" SG_ 159 Sig6279 "Signal6337";
BA_ "SignalType" SG_ 159 Sig6278 "ENM";
BA_ "SignalLongName" SG_ 159 Sig6278 "Signal6336";
BA_ "SignalType" SG_ 159 Sig6277 "ENM";
BA_ "SignalLongName" SG_ 159 Sig6277 "Signal6335";
BA_ "SignalLongName" SG_ 159 Sig6282 "Signal6339";
BA_ "SignalType" SG_ 159 Sig6280 "ENM";
BA_ "SignalLongName" SG_ 159 Sig6280 "Signal6338";
BA_ "SignalLongName" SG_ 159 Sig6433 "Signal6344";
BA_ "SignalType" SG_ 159 Sig6284 "ENM";
BA_ "SignalLongName" SG_ 159 Sig6284 "Signal6341";
BA_ "SignalType" SG_ 159 Sig6283 "ENM";
BA_ "SignalLongName" SG_ 159 Sig6283 "Signal6340";
BA_ "SignalLongName" SG_ 159 Sig6434 "Signal6345";
BA_ "SignalLongName" SG_ 159 Sig6453 "Signal6342";
BA_ "SignalLongName" SG_ 159 Sig6454 "Signal6343";
BA_ "SignalLongName" SG_ 159 Sig6473 "Signal6346";
BA_ "SignalLongName" SG_ 159 Sig6474 "Signal6347";
BA_ "SignalLongName" SG_ 159 Sig6493 "Signal6348";
BA_ "SignalLongName" SG_ 159 Sig6494 "Signal6349";
BA_ "SignalLongName" SG_ 159 Sig6513 "Signal6350";
BA_ "SignalLongName" SG_ 159 Sig6514 "Signal6351";
BA_ "SignalLongName" SG_ 159 Sig6533 "Signal6352";
BA_ "SignalLongName" SG_ 159 Sig6534 "Signal6353";
BA_ "SignalLongName" SG_ 159 Sig6553 "Signal6354";
BA_ "SignalLongName" SG_ 159 Sig6554 "Signal6355";
BA_ "SignalLongName" SG_ 159 Sig6573 "Signal6356";
BA_ "SignalLongName" SG_ 159 Sig6574 "Signal6357";
BA_ "SignalLongName" SG_ 159 Sig6593 "Signal6358";
BA_ "SignalLongName" SG_ 159 Sig6594 "Signal6359";
BA_ "SignalLongName" SG_ 159 Sig6613 "Signal6360";
BA_ "SignalLongName" SG_ 159 Sig6614 "Signal6361";
BA_ "SignalLongName" SG_ 165 Sig5686 "Signal6006";
BA_ "SignalLongName" SG_ 165 Sig5685 "Signal6005";
BA_ "SignalLongName" SG_ 165 Sig6200 "Signal6007";
BA_ "SignalLongName" SG_ 165 Sig5684 "Signal6004";
BA_ "SignalType" SG_ 165 Sig6202 "ENM";
BA_ "SignalLongName" SG_ 165 Sig6202 "Signal6009";
BA_ "SignalType" SG_ 165 Sig6201 "ENM";
BA_ "SignalLongName" SG_ 165 Sig6201 "Signal6008";
BA_ "SignalType" SG_ 165 Sig6291 "ENM";
BA_ "SignalLongName" SG_ 165 Sig6291 "Signal6013";
BA_ "SignalType" SG_ 165 Sig6290 "ENM";
BA_ "SignalLongName" SG_ 165 Sig6290 "Signal6012";
BA_ "SignalType" SG_ 165 Sig6285 "ENM";
BA_ "SignalLongName" SG_ 165 Sig6285 "Signal6011";
BA_ "SignalType" SG_ 165 Sig6203 "ENM";
BA_ "SignalLongName" SG_ 165 Sig6203 "Signal6010";
BA_ "SignalLongName" SG_ 165 Sig6292 "Signal6014";
BA_ "SignalType" SG_ 165 Sig6294 "ENM";
BA_ "SignalLongName" SG_ 165 Sig6294 "Signal6016";
BA_ "SignalLongName" SG_ 165 Sig6293 "Signal6015";
BA_ "SignalLongName" SG_ 165 Sig6295 "Signal6017";
BA_ "SignalLongName" SG_ 165 Sig6296 "Signal6018";
BA_ "SignalLongName" SG_ 165 Sig6297 "Signal6019";
BA_ "SignalLongName" SG_ 165 Sig6298 "Signal6020";
BA_ "SignalLongName" SG_ 165 Sig6299 "Signal6021";
BA_ "SignalLongName" SG_ 165 Sig6300 "Signal6022";
BA_ "SignalType" SG_ 165 Sig6303 "ENM";
BA_ "SignalLongName" SG_ 165 Sig6303 "Signal6025";
BA_ "SignalType" SG_ 165 Sig6302 "ENM";
BA_ "SignalLongName" SG_ 165 Sig6302 "Signal6024";
BA_ "SignalType" SG_ 165 Sig6301 "ENM";
BA_ "SignalLongName" SG_ 165 Sig6301 "Signal6023";
BA_ "SignalLongName" SG_ 165 Sig6305 "Signal6027";
BA_ "SignalType" SG_ 165 Sig6304 "ENM";
BA_ "SignalLongName" SG_ 165 Sig6304 "Signal6026";
BA_ "SignalLongName" SG_ 165 Sig6306 "Signal6028";
BA_ "SignalLongName" SG_ 165 Sig6308 "Signal6030";
BA_ "SignalType" SG_ 165 Sig6307 "ENM";
BA_ "SignalLongName" SG_ 165 Sig6307 "Signal6029";
BA_ "SignalLongName" SG_ 165 Sig6309 "Signal6031";
BA_ "SignalLongName" SG_ 165 Sig6310 "Signal6032";
BA_ "SignalLongName" SG_ 165 Sig6311 "Signal6033";
BA_ "SignalLongName" SG_ 165 Sig6312 "Signal6034";
BA_ "SignalLongName" SG_ 165 Sig6313 "Signal6035";
BA_ "SignalType" SG_ 165 Sig6315 "ENM";
BA_ "SignalLongName" SG_ 165 Sig6315 "Signal6037";
BA_ "SignalType" SG_ 165 Sig6314 "ENM";
BA_ "SignalLongName" SG_ 165 Sig6314 "Signal6036";
BA_ "SignalType" SG_ 165 Sig6387 "ENM";
BA_ "SignalLongName" SG_ 165 Sig6387 "Signal6041";
BA_ "SignalType" SG_ 165 Sig6386 "ENM";
BA_ "SignalLongName" SG_ 165 Sig6386 "Signal6040";
BA_ "SignalType" SG_ 165 Sig6385 "ENM";
BA_ "SignalLongName" SG_ 165 Sig6385 "Signal6042";
BA_ "SignalType" SG_ 165 Sig6383 "ENM";
BA_ "SignalLongName" SG_ 165 Sig6383 "Signal6039";
BA_ "SignalType" SG_ 165 Sig6382 "ENM";
BA_ "SignalLongName" SG_ 165 Sig6382 "Signal6038";
BA_ "SignalLongName" SG_ 165 Sig6447 "Signal6045";
BA_ "SignalType" SG_ 165 Sig6388 "ENM";
BA_ "SignalLongName" SG_ 165 Sig6388 "Signal6043";
BA_ "SignalLongName" SG_ 165 Sig6451 "Signal6048";
BA_ "SignalType" SG_ 165 Sig6450 "ENM";
BA_ "SignalLongName" SG_ 165 Sig6450 "Signal6047";
BA_ "SignalType" SG_ 165 Sig6449 "ENM";
BA_ "SignalLongName" SG_ 165 Sig6449 "Signal6046";
BA_ "SignalType" SG_ 165 Sig6448 "ENM";
BA_ "SignalLongName" SG_ 165 Sig6448 "Signal6044";
BA_ "SignalLongName" SG_ 165 Sig6455 "Signal6050";
BA_ "SignalType" SG_ 165 Sig6452 "ENM";
BA_ "SignalLongName" SG_ 165 Sig6452 "Signal6049";
BA_ "SignalLongName" SG_ 165 Sig6456 "Signal6051";
BA_ "SignalLongName" SG_ 165 Sig6457 "Signal6052";
BA_ "SignalLongName" SG_ 165 Sig6458 "Signal6053";
BA_ "SignalLongName" SG_ 165 Sig6459 "Signal6054";
BA_ "SignalLongName" SG_ 165 Sig6460 "Signal6056";
BA_ "SignalLongName" SG_ 165 Sig6461 "Signal6057";
BA_ "SignalLongName" SG_ 165 Sig6462 "Signal6058";
BA_ "SignalLongName" SG_ 165 Sig6463 "Signal6059";
BA_ "SignalLongName" SG_ 165 Sig6464 "Signal6060";
BA_ "SignalLongName" SG_ 165 Sig6465 "Signal6055";
BA_ "SignalLongName" SG_ 165 Sig6485 "Signal6062";
BA_ "SignalType" SG_ 165 Sig6466 "ENM";
BA_ "SignalLongName" SG_ 165 Sig6466 "Signal6061";
BA_ "SignalLongName" SG_ 165 Sig5683 "Signal6003";
BA_ "SignalLongName" SG_ 158 Sig5696 "Signal6363";
BA_ "SignalLongName" SG_ 158 Sig5695 "Signal6362";
BA_ "SignalLongName" SG_ 158 Sig5697 "Signal6364";
BA_ "SignalLongName" SG_ 158 Sig6209 "Signal6366";
BA_ "SignalLongName" SG_ 158 Sig6217 "Signal6365";
BA_ "SignalLongName" SG_ 158 Sig6225 "Signal6367";
BA_ "SignalLongName" SG_ 158 Sig6233 "Signal6368";
BA_ "SignalLongName" SG_ 158 Sig6241 "Signal6369";
BA_ "SignalLongName" SG_ 158 Sig6249 "Signal6370";
BA_ "SignalLongName" SG_ 158 Sig6257 "Signal6371";
BA_ "SignalLongName" SG_ 158 Sig6265 "Signal6372";
BA_ "SignalLongName" SG_ 158 Sig6273 "Signal6373";
BA_ "SignalLongName" SG_ 158 Sig6281 "Signal6374";
BA_ "SignalLongName" SG_ 158 Sig6356 "Signal6376";
BA_ "SignalType" SG_ 158 Sig6355 "ENM";
BA_ "SignalLongName" SG_ 158 Sig6355 "Signal6375";
BA_ "SignalLongName" SG_ 158 Sig6357 "Signal6377";
BA_ "SignalLongName" SG_ 158 Sig6358 "Signal6378";
BA_ "SignalLongName" SG_ 158 Sig6359 "Signal6379";
BA_ "SignalLongName" SG_ 158 Sig6360 "Signal6380";
BA_ "SignalLongName" SG_ 158 Sig6361 "Signal6381";
BA_ "SignalType" SG_ 158 Sig6363 "ENM";
BA_ "SignalLongName" SG_ 158 Sig6363 "Signal6383";
BA_ "SignalType" SG_ 158 Sig6362 "ENM";
BA_ "SignalLongName" SG_ 158 Sig6362 "Signal6382";
BA_ "SignalLongName" SG_ 158 Sig6365 "Signal6385";
BA_ "SignalType" SG_ 158 Sig6364 "ENM";
BA_ "SignalLongName" SG_ 158 Sig6364 "Signal6384";
BA_ "SignalLongName" SG_ 158 Sig6366 "Signal6386";
BA_ "SignalLongName" SG_ 158 Sig6367 "Signal6387";
BA_ "SignalLongName" SG_ 158 Sig6368 "Signal6388";
BA_ "SignalLongName" SG_ 158 Sig6369 "Signal6389";
BA_ "SignalLongName" SG_ 158 Sig6370 "Signal6390";
BA_ "SignalType" SG_ 158 Sig6372 "ENM";
BA_ "SignalLongName" SG_ 158 Sig6372 "Signal6392";
BA_ "SignalType" SG_ 158 Sig6371 "ENM";
BA_ "SignalLongName" SG_ 158 Sig6371 "Signal6391";
BA_ "SignalLongName" SG_ 158 Sig6374 "Signal6394";
BA_ "SignalType" SG_ 158 Sig6373 "ENM";
BA_ "SignalLongName" SG_ 158 Sig6373 "Signal6393";
BA_ "SignalLongName" SG_ 158 Sig6375 "Signal6395";
BA_ "SignalLongName" SG_ 158 Sig6376 "Signal6396";
BA_ "SignalLongName" SG_ 158 Sig6377 "Signal6397";
BA_ "SignalLongName" SG_ 158 Sig6378 "Signal6398";
BA_ "SignalLongName" SG_ 158 Sig6379 "Signal6399";
BA_ "SignalType" SG_ 158 Sig6381 "ENM";
BA_ "SignalLongName" SG_ 158 Sig6381 "Signal6401";
BA_ "SignalType" SG_ 158 Sig6380 "ENM";
BA_ "SignalLongName" SG_ 158 Sig6380 "Signal6400";
BA_ "SignalLongName" SG_ 908 SrlDat18_PCSM "Serial Data 18 Protected Counter Sync Message";
BA_ "SignalLongName" SG_ 100 SD18P_MAC "Serial Data 18 Protected : MAC";
BA_ "SignalLongName" SG_ 100 SD18P_FCnt "Serial Data 18 Protected : Freshness Counter";
BA_ "SignalLongName" SG_ 100 EGI5P_ECDIntlRngSnsrPWAuth "Serial Data 18 Protected : Engine Controller Determined Internal Range Sensor Pulse Width Authenticated";
BA_ "SignalType" SG_ 100 EGI1P_PtclFiltClnAlgActAuth_DuD "ENM";
BA_ "SignalLongName" SG_ 100 EGI1P_PtclFiltClnAlgActAuth_DuD "Serial Data 18 Protected : Particle Filter Cleaning Algorithm Active Authenticated Don't Use Data";
BA_ "SignalType" SG_ 100 EGI1P_PtclFiltClnAlgActAuth "ENM";
BA_ "SignalLongName" SG_ 100 EGI1P_PtclFiltClnAlgActAuth "Serial Data 18 Protected : Particle Filter Cleaning Algorithm Active Authenticated";
BA_ "SignalLongName" SG_ 100 EGIP_CrksftNTransRegCmdTqAuth "Serial Data 18 Protected : Crankshaft Non-Transmission Regulated Commanded Torque Authenticated";
BA_ "SignalType" SG_ 100 EGI5P_EngStlSvrActvAuth "ENM";
BA_ "SignalLongName" SG_ 100 EGI5P_EngStlSvrActvAuth "Serial Data 18 Protected : Engine Stall Saver Active Authenticated";
BA_ "SignalType" SG_ 100 EGI5P_ECDIntlRngSnsrPWAuth_Inv "ENM";
BA_ "SignalLongName" SG_ 100 EGI5P_ECDIntlRngSnsrPWAuth_Inv "Serial Data 18 Protected : Engine Controller Determined Internal Range Sensor Pulse Width Authenticated Invalid";
BA_ "SignalLongName" SG_ 100 EGIP_DrvrIntndCrksftTrqMinAuth "Serial Data 18 Protected : Driver Intended Crankshaft Torque Minimum Authenticated";
BA_ "SignalLongName" SG_ 100 EGIP_DrvrIntndCrksftTrqRwAuth "Serial Data 18 Protected : Driver Intended Crankshaft Torque Raw Authenticated";
BA_ "SignalLongName" SG_ 100 EGIP_EngActlStdyStatTrqAuth "Serial Data 18 Protected : Engine Actual Steady State Torque Authenticated";
BA_ "SignalLongName" SG_ 100 EGIP_EngNTransRegSSTrqAuth "Serial Data 18 Protected : Engine Non-Transmission Regulated Steady State Torque Authenticated";
BA_ "SignalType" SG_ 100 EGIP_EngActlStdyStatTrqAuth_Inv "ENM";
BA_ "SignalLongName" SG_ 100 EGIP_EngActlStdyStatTrqAuth_Inv "Serial Data 18 Protected : Engine Actual Steady State Torque Authenticated Invalid";
BA_ "SignalLongName" SG_ 100 ESP_EngSpdAuth "Serial Data 18 Protected : Engine Speed Authenticated";
BA_ "SignalType" SG_ 100 EGIP_EngNTransRegSSTrqAuth_Inv "ENM";
BA_ "SignalLongName" SG_ 100 EGIP_EngNTransRegSSTrqAuth_Inv "Serial Data 18 Protected : Engine Non-Transmission Regulated Steady State Torque Authenticated Invalid";
BA_ "SignalLongName" SG_ 100 SD18P_ARC "Serial Data 18 Protected : Alive Rolling Count";
BA_ "SignalType" SG_ 100 E44BRP_HillDscntCtlSwStsAuth "ENM";
BA_ "SignalLongName" SG_ 100 E44BRP_HillDscntCtlSwStsAuth "Serial Data 18 Protected : Hill Descent Control Switch Status Authenticated";
BA_ "SignalType" SG_ 100 ESP_EngSpdStAuth "ENM";
BA_ "SignalLongName" SG_ 100 ESP_EngSpdStAuth "Serial Data 18 Protected : Engine Speed State Authenticated";
BA_ "SignalLongName" SG_ 100 EngNonTransRegSSTrqER "Serial Data 18 Protected : Engine Non-Transmission Regulated Steady State Torque Extended Range";
BA_ "SignalType" SG_ 100 E49RmtEngStrtReqAuth "ENM";
BA_ "SignalLongName" SG_ 100 E49RmtEngStrtReqAuth "Serial Data 18 Protected : Power Take Off Remote Engine Start Request Authenticated";
BA_ "SignalType" SG_ 100 E49RmtEngShtdnReqdAuth "ENM";
BA_ "SignalLongName" SG_ 100 E49RmtEngShtdnReqdAuth "Serial Data 18 Protected : Power Take Off Remote Engine Shutdown Requested Authenticated";
BA_ "SignalLongName" SG_ 100 SD18P_Filler "Serial Data 18 Protected : Filler";
BA_ "SignalType" SG_ 100 EngNonTransRegSSTrqER_Inv "ENM";
BA_ "SignalLongName" SG_ 100 EngNonTransRegSSTrqER_Inv "Serial Data 18 Protected : Engine Non-Transmission Regulated Steady State Torque Extended Range Invalid";
BA_ "SignalLongName" SG_ 978 SrlDat195_PCSM "Serial Data 195 Protected Counter Sync Message";
BA_ "SignalLongName" SG_ 157 SD195P_MAC "Serial Data 195 Protected : MAC";
BA_ "SignalLongName" SG_ 157 SD195P_FCnt "Serial Data 195 Protected : Freshness Counter";
BA_ "SignalLongName" SG_ 157 DMSDrvrDrwLvlPrd "Serial Data 195 Protected : Driver Monitoring System Driver Drowsiness Level Period";
BA_ "SignalLongName" SG_ 157 DMSDrvrPctgOfEyeClsrPrd "Serial Data 195 Protected : Driver Monitoring System Driver Percentage Of Eye Closure Period";
BA_ "SignalLongName" SG_ 157 DMSDrvrPctgOfEyeClsr "Serial Data 195 Protected : Driver Monitoring System Driver Percentage Of Eye Closure";
BA_ "SignalType" SG_ 157 DMSDrvrDrwLvlCnfdLvl "ENM";
BA_ "SignalLongName" SG_ 157 DMSDrvrDrwLvlCnfdLvl "Serial Data 195 Protected : Driver Monitoring System Driver Drowsiness Level Confidence Level";
BA_ "SignalType" SG_ 157 DMSDrvrDrwLvl "ENM";
BA_ "SignalLongName" SG_ 157 DMSDrvrDrwLvl "Serial Data 195 Protected : Driver Monitoring System Driver Drowsiness Level";
BA_ "SignalLongName" SG_ 157 SD195P_Filler "Serial Data 195 Protected : Filler";
BA_ "SignalLongName" SG_ 157 SD195P_ARC "Serial Data 195 Protected : Alive Rolling Count";
BA_ "SignalLongName" SG_ 1139 Sig6852 "Signal6416";
BA_ "SignalLongName" SG_ 1138 Sig5703 "Signal6415";
BA_ "SignalLongName" SG_ 1138 Sig5701 "Signal6414";
BA_ "SignalLongName" SG_ 1138 Sig5702 "Signal6413";
BA_ "SignalType" SG_ 1138 Sig1073 "ENM";
BA_ "SignalLongName" SG_ 1138 Sig1073 "Signal6411";
BA_ "SignalType" SG_ 1138 Sig1074 "ENM";
BA_ "SignalLongName" SG_ 1138 Sig1074 "Signal6412";
BA_ "SignalLongName" SG_ 1138 Sig5700 "Signal6410";
BA_ "SignalLongName" SG_ 907 SrlDat19_PCSM "Serial Data 19 Protected Counter Sync Message";
BA_ "SignalLongName" SG_ 47 SD19P_MAC "Serial Data 19 Protected : MAC";
BA_ "SignalLongName" SG_ 47 SD19P_FCnt "Serial Data 19 Protected : Freshness Counter";
BA_ "SignalLongName" SG_ 47 AATP_ActAxlTrqAuth "Serial Data 19 Protected : Actual Axle Torque Authenticated";
BA_ "SignalType" SG_ 47 AATP_ActAxlTrqAuth_Inv "ENM";
BA_ "SignalLongName" SG_ 47 AATP_ActAxlTrqAuth_Inv "Serial Data 19 Protected : Actual Axle Torque Authenticated Invalid";
BA_ "SignalLongName" SG_ 47 AEPP_AccEffcPosAuth "Serial Data 19 Protected : Accelerator Effective Position Authenticated";
BA_ "SignalLongName" SG_ 47 DRCDNDP_DRCAvgDrvnAuth "Serial Data 19 Protected : Distance Rolling Count Average Driven Authenticated";
BA_ "SignalType" SG_ 47 AEPP_AccEffcPosAuth_Inv "ENM";
BA_ "SignalLongName" SG_ 47 AEPP_AccEffcPosAuth_Inv "Serial Data 19 Protected : Accelerator Effective Position Authenticated Invalid";
BA_ "SignalType" SG_ 47 DRCDNDP_DRCAvgDrvnRstOccAuth "ENM";
BA_ "SignalLongName" SG_ 47 DRCDNDP_DRCAvgDrvnRstOccAuth "Serial Data 19 Protected : Distance Rolling Count Average Driven Reset Occurred Authenticated";
BA_ "SignalType" SG_ 47 DRCDNDP_DRCAvgDrvnAuth_Inv "ENM";
BA_ "SignalLongName" SG_ 47 DRCDNDP_DRCAvgDrvnAuth_Inv "Serial Data 19 Protected : Distance Rolling Count Average Driven Authenticated Invalid";
BA_ "SignalLongName" SG_ 47 DRCDNDP_DRCAvgNonDrvnAuth "Serial Data 19 Protected : Distance Rolling Count Average Non Driven Authenticated";
BA_ "SignalType" SG_ 47 DRCDNDP_DRCAvgDrvnSrcAuth "ENM";
BA_ "SignalLongName" SG_ 47 DRCDNDP_DRCAvgDrvnSrcAuth "Serial Data 19 Protected : Distance Rolling Count Average Driven Source Authenticated";
BA_ "SignalType" SG_ 47 DRCDNDP_DRCAvgNonDrvnRstOccAuth "ENM";
BA_ "SignalLongName" SG_ 47 DRCDNDP_DRCAvgNonDrvnRstOccAuth "Serial Data 19 Protected : Distance Rolling Count Average Non Driven Reset Occurred Authenticated";
BA_ "SignalType" SG_ 47 DRCDNDP_DRCAvgNonDrvnAuth_Inv "ENM";
BA_ "SignalLongName" SG_ 47 DRCDNDP_DRCAvgNonDrvnAuth_Inv "Serial Data 19 Protected : Distance Rolling Count Average Non Driven Authenticated Invalid";
BA_ "SignalLongName" SG_ 47 E44BRP_PTAutoBrkgAccelReqAuth "Serial Data 19 Protected : Powertrain Automatic Braking Acceleration Request Authenticated";
BA_ "SignalType" SG_ 47 DRCDNDP_PwrtrnRunAbrtdAuth "ENM";
BA_ "SignalLongName" SG_ 47 DRCDNDP_PwrtrnRunAbrtdAuth "Serial Data 19 Protected : Powertrain Run Aborted Authenticated";
BA_ "SignalLongName" SG_ 47 PBP_PTSndBrkPdlPsAuth "Serial Data 19 Protected : Powertrain Sensed Brake Pedal Position Authenticated";
BA_ "SignalType" SG_ 47 E44BRP_PTAutoBrkgReqActvAuth "ENM";
BA_ "SignalLongName" SG_ 47 E44BRP_PTAutoBrkgReqActvAuth "Serial Data 19 Protected : Powertrain Automatic Braking Request Active Authenticated";
BA_ "SignalLongName" SG_ 47 PSATDP_ATDstTrqCmdSecAuth "Serial Data 19 Protected : Propulsion System Axle Torque Distribution Torque Command Secondary Authenticated";
BA_ "SignalType" SG_ 47 PBP_PTSndBrkPdlPsAuth_Inv "ENM";
BA_ "SignalLongName" SG_ 47 PBP_PTSndBrkPdlPsAuth_Inv "Serial Data 19 Protected : Powertrain Sensed Brake Pedal Position Authenticated Invalid";
BA_ "SignalLongName" SG_ 47 PSATIP_ATDstTqCmdPriImmAuth "Serial Data 19 Protected : Axle Torque Distribution Torque Command Primary Immediate Authenticated";
BA_ "SignalType" SG_ 47 PSATDP_ATDstTrqCmdSecAuth_Inv "ENM";
BA_ "SignalLongName" SG_ 47 PSATDP_ATDstTrqCmdSecAuth_Inv "Serial Data 19 Protected : Propulsion System Axle Torque Distribution Torque Command Secondary Authenticated Invalid";
BA_ "SignalLongName" SG_ 47 PSATIP_CmndATImmedAuth "Serial Data 19 Protected : Commanded Axle Torque Immediate Authenticated";
BA_ "SignalType" SG_ 47 PSATIP_ATDstTqCmdPriImmAuth_Inv "ENM";
BA_ "SignalLongName" SG_ 47 PSATIP_ATDstTqCmdPriImmAuth_Inv "Serial Data 19 Protected : Axle Torque Distribution Torque Command Primary Immediate Authenticated Invalid";
BA_ "SignalLongName" SG_ 47 PSATIP_CmndATPrdtdAuth "Serial Data 19 Protected : Commanded Axle Torque Predicted Authenticated";
BA_ "SignalLongName" SG_ 47 PSATIP_PriATActlAuth "Serial Data 19 Protected : Primary Axle Torque Actual Authenticated";
BA_ "SignalType" SG_ 47 PSATIP_CmndATRespTypAuth "ENM";
BA_ "SignalLongName" SG_ 47 PSATIP_CmndATRespTypAuth "Serial Data 19 Protected : Commanded Axle Torque Response Type Authenticated";
BA_ "SignalLongName" SG_ 47 PSATIP_PriATCmdImmedAuth "Serial Data 19 Protected : Primary Axle Torque Command Immediate Authenticated";
BA_ "SignalType" SG_ 47 PSATIP_PriATActlAuth_Inv "ENM";
BA_ "SignalLongName" SG_ 47 PSATIP_PriATActlAuth_Inv "Serial Data 19 Protected : Primary Axle Torque Actual Authenticated Invalid";
BA_ "SignalType" SG_ 47 PSATIP_PriATReqStsAdvdTracAuth "ENM";
BA_ "SignalLongName" SG_ 47 PSATIP_PriATReqStsAdvdTracAuth "Serial Data 19 Protected : Primary Axle Torque Request Status Advanced Traction Authenticated";
BA_ "SignalLongName" SG_ 47 SD19P_FillerExtnd "Serial Data 19 Protected : Filler Extended";
BA_ "SignalType" SG_ 47 PSATDP_SecATReqStsAdvdTracAuth "ENM";
BA_ "SignalLongName" SG_ 47 PSATDP_SecATReqStsAdvdTracAuth "Serial Data 19 Protected : Propulsion System Secondary Axle Torque Request Status Advanced Traction Authenticated";
BA_ "SignalLongName" SG_ 47 PSATIP_SecATCmdImmedAuth "Serial Data 19 Protected : Secondary Axle Torque Command Immediate Authenticated";
BA_ "SignalLongName" SG_ 47 SD19P_ARC "Serial Data 19 Protected : Alive Rolling Count";
BA_ "SignalLongName" SG_ 47 SD19P_Filler "Serial Data 19 Protected : Filler";
BA_ "SignalLongName" SG_ 906 SrlDat20_PCSM "Serial Data 20 Protected Counter Sync Message";
BA_ "SignalLongName" SG_ 226 SD20P_MAC "Serial Data 20 Protected : MAC";
BA_ "SignalLongName" SG_ 226 SD20P_FCnt "Serial Data 20 Protected : Freshness Counter";
BA_ "SignalLongName" SG_ 226 DIATMNP_DrvrIntdAxlTqMnAuth "Serial Data 20 Protected : Driver Intended Axle Torque Minimum Authenticated";
BA_ "SignalType" SG_ 226 DIATMNP_DrvrIntdAxlTqMnAuth_Inv "ENM";
BA_ "SignalLongName" SG_ 226 DIATMNP_DrvrIntdAxlTqMnAuth_Inv "Serial Data 20 Protected : Driver Intended Axle Torque Minimum Authenticated Invalid";
BA_ "SignalLongName" SG_ 226 DIATMXP_DrvrIntdAxlTqMxAuth "Serial Data 20 Protected : Driver Intended Axle Torque Maximum Authenticated";
BA_ "SignalType" SG_ 226 DIATMXP_DrvrIntdAxlTqMxAuth_Inv "ENM";
BA_ "SignalLongName" SG_ 226 DIATMXP_DrvrIntdAxlTqMxAuth_Inv "Serial Data 20 Protected : Driver Intended Axle Torque Maximum Authenticated Invalid";
BA_ "SignalLongName" SG_ 226 DITP_DrvrIntndAxlTrqAuth "Serial Data 20 Protected : Driver Intended Axle Torque Authenticated";
BA_ "SignalType" SG_ 226 DITP_DrvrIntndAxlTrqAuth_Inv "ENM";
BA_ "SignalLongName" SG_ 226 DITP_DrvrIntndAxlTrqAuth_Inv "Serial Data 20 Protected : Driver Intended Axle Torque Authenticated Invalid";
BA_ "SignalLongName" SG_ 226 DITP_DrvrIntndCrksftTrqAuth "Serial Data 20 Protected : Driver Intended Crankshaft Torque Authenticated";
BA_ "SignalLongName" SG_ 226 VMI1P_AccelActlPstnAuth "Serial Data 20 Protected : Accelerator Actual Position Authenticated";
BA_ "SignalLongName" SG_ 226 VMI1P_VehTopSpdLimArbdValAuth "Serial Data 20 Protected : Vehicle Top Speed Limit Arbitrated Value Authenticated";
BA_ "SignalType" SG_ 226 VMI1P_AccelPedOvrrdActvAuth "ENM";
BA_ "SignalLongName" SG_ 226 VMI1P_AccelPedOvrrdActvAuth "Serial Data 20 Protected : Accelerator Pedal Override Active Authenticated";
BA_ "SignalType" SG_ 226 VMI1P_AccelActlPstnAuth_Inv "ENM";
BA_ "SignalLongName" SG_ 226 VMI1P_AccelActlPstnAuth_Inv "Serial Data 20 Protected : Accelerator Actual Position Authenticated Invalid";
BA_ "SignalLongName" SG_ 226 SD20P_ARC "Serial Data 20 Protected : Alive Rolling Count";
BA_ "SignalType" SG_ 226 VMI1P_VehTopSpdLimModeActvAuth "ENM";
BA_ "SignalLongName" SG_ 226 VMI1P_VehTopSpdLimModeActvAuth "Serial Data 20 Protected : Vehicle Top Speed Limit Mode Active Authenticated";
BA_ "SignalLongName" SG_ 226 SD20P_Filler "Serial Data 20 Protected : Filler";
BA_ "SignalLongName" SG_ 226 SD20P_FillerExtnd "Serial Data 20 Protected : Filler Extended";
BA_ "SignalLongName" SG_ 905 SrlDat21_PCSM "Serial Data 21 Protected Counter Sync Message";
BA_ "SignalLongName" SG_ 615 SD21P_MAC "Serial Data 21 Protected : MAC";
BA_ "SignalLongName" SG_ 615 SD21P_FCnt "Serial Data 21 Protected : Freshness Counter";
BA_ "SignalType" SG_ 615 BVSCRP_BdyCtlTpSpdLimRspTypAuth "ENM";
BA_ "SignalLongName" SG_ 615 BVSCRP_BdyCtlTpSpdLimRspTypAuth "Serial Data 21 Protected : Body Control Top Speed Limit Response Type Authenticated";
BA_ "SignalType" SG_ 615 BVSCRP_ACCAxlTrqCmdReqStsAuth "ENM";
BA_ "SignalLongName" SG_ 615 BVSCRP_ACCAxlTrqCmdReqStsAuth "Serial Data 21 Protected : Adaptive Cruise Control Axle Torque Command Request Status Authenticated";
BA_ "SignalType" SG_ 615 BVSCRP_ACCAxlTrqCmdLimStsAuth "ENM";
BA_ "SignalLongName" SG_ 615 BVSCRP_ACCAxlTrqCmdLimStsAuth "Serial Data 21 Protected : Adaptive Cruise Control Axle Torque Command Limiting Status Authenticated";
BA_ "SignalLongName" SG_ 615 BVSCRP_BdyCtlTpSpdLimRspValAuth "Serial Data 21 Protected : Body Control Top Speed Limit Response Value Authenticated";
BA_ "SignalLongName" SG_ 615 BVSCRP_CltchPdlActPosAuth "Serial Data 21 Protected : Clutch Pedal Actual Position Authenticated";
BA_ "SignalType" SG_ 615 BVSCRP_CPSAxlTrqCmdReqStsAuth "ENM";
BA_ "SignalLongName" SG_ 615 BVSCRP_CPSAxlTrqCmdReqStsAuth "Serial Data 21 Protected : Collision Preparation System Axle Torque Command Request Status Authenticated";
BA_ "SignalType" SG_ 615 BVSCRP_CPSAxlTrqCmdLimStsAuth "ENM";
BA_ "SignalLongName" SG_ 615 BVSCRP_CPSAxlTrqCmdLimStsAuth "Serial Data 21 Protected : Collision Preparation System Axle Torque Command Limiting Status Authenticated";
BA_ "SignalType" SG_ 615 CnvntlCruzCtlIndReqAuth "ENM";
BA_ "SignalLongName" SG_ 615 CnvntlCruzCtlIndReqAuth "Serial Data 21 Protected : Conventional Cruise Control Indication Request Authenticated";
BA_ "SignalType" SG_ 615 BVSCRP_CruzCtlEnbldAuth "ENM";
BA_ "SignalLongName" SG_ 615 BVSCRP_CruzCtlEnbldAuth "Serial Data 21 Protected : Cruise Control Enabled Authenticated";
BA_ "SignalType" SG_ 615 BVSCRP_CltchPdlActPosAuth_Inv "ENM";
BA_ "SignalLongName" SG_ 615 BVSCRP_CltchPdlActPosAuth_Inv "Serial Data 21 Protected : Clutch Pedal Actual Position Authenticated Invalid";
BA_ "SignalLongName" SG_ 615 CruzSpdLmtrDrvrSeltdSpdAuth "Serial Data 21 Protected : Cruise and Speed Limiter Driver Selected Speed Authenticated";
BA_ "SignalType" SG_ 615 CruzCtlActvAuth "ENM";
BA_ "SignalLongName" SG_ 615 CruzCtlActvAuth "Serial Data 21 Protected : Cruise Control Active Authenticated";
BA_ "SignalType" SG_ 615 DrSeltdSpdLmtrAutoMdSpLmStsAuth "ENM";
BA_ "SignalLongName" SG_ 615 DrSeltdSpdLmtrAutoMdSpLmStsAuth "Serial Data 21 Protected : Driver Selected Speed Limiter Auto Mode Speed Limit Status Authenticated";
BA_ "SignalLongName" SG_ 615 EGI2P_DrvrReqdAxlTrqValAuth "Serial Data 21 Protected : Driver Requested Axle Torque Value Authenticated";
BA_ "SignalType" SG_ 615 EGI2P_DrvrReqdAxlTrqIncrAuth "ENM";
BA_ "SignalLongName" SG_ 615 EGI2P_DrvrReqdAxlTrqIncrAuth "Serial Data 21 Protected : Driver Requested Axle Torque Increase Authenticated";
BA_ "SignalType" SG_ 615 DrSeltdSpdLmtrSetTypActvAuth "ENM";
BA_ "SignalLongName" SG_ 615 DrSeltdSpdLmtrSetTypActvAuth "Serial Data 21 Protected : Driver Selected Speed Limiter Setting Type Active Authenticated";
BA_ "SignalType" SG_ 615 DrSeltdSpdLmtrSetSpdLimRchdAuth "ENM";
BA_ "SignalLongName" SG_ 615 DrSeltdSpdLmtrSetSpdLimRchdAuth "Serial Data 21 Protected : Driver Selected Speed Limiter Set Speed Limit Reached Authenticated";
BA_ "SignalType" SG_ 615 E44BRP_VehTopSpdLimArbdStatAuth "ENM";
BA_ "SignalLongName" SG_ 615 E44BRP_VehTopSpdLimArbdStatAuth "Serial Data 21 Protected : Vehicle Top Speed Limit Arbitrated State Authenticated";
BA_ "SignalType" SG_ 615 EGI2P_PwrtrnCrnkActvAuth "ENM";
BA_ "SignalLongName" SG_ 615 EGI2P_PwrtrnCrnkActvAuth "Serial Data 21 Protected : Powertrain Crank Active Authenticated";
BA_ "SignalType" SG_ 615 EGI2P_DrvrReqdAxlTrqValAuth_Inv "ENM";
BA_ "SignalLongName" SG_ 615 EGI2P_DrvrReqdAxlTrqValAuth_Inv "Serial Data 21 Protected : Driver Requested Axle Torque Value Authenticated Invalid";
BA_ "SignalLongName" SG_ 615 SpdLmtrSpdLimSgnValAuth "Serial Data 21 Protected : Speed Limiter Speed Limit Sign Value Authenticated";
BA_ "SignalType" SG_ 615 SpdLmtrSpdLimSgnUntAuth "ENM";
BA_ "SignalLongName" SG_ 615 SpdLmtrSpdLimSgnUntAuth "Serial Data 21 Protected : Speed Limiter Speed Limit Sign Unit Authenticated";
BA_ "SignalLongName" SG_ 615 SD21P_Filler "Serial Data 21 Protected : Filler";
BA_ "SignalType" SG_ 615 SuprRmtPrkPrplSysResp "ENM";
BA_ "SignalLongName" SG_ 615 SuprRmtPrkPrplSysResp "Serial Data 21 Protected : Supervised Remote Parking Propulsion System Response";
BA_ "SignalLongName" SG_ 615 SD21P_ARC "Serial Data 21 Protected : Alive Rolling Count";
BA_ "SignalLongName" SG_ 615 SD21P_FillerExtnd "Serial Data 21 Protected : Filler Extended";
BA_ "SignalLongName" SG_ 1404 SrlDat22_PCSM "Serial Data 22 Protected Counter Sync Message";
BA_ "SignalLongName" SG_ 879 SD22P_MAC "Serial Data 22 Protected : MAC";
BA_ "SignalLongName" SG_ 879 SD22P_FCnt "Serial Data 22 Protected : Freshness Counter";
BA_ "SignalLongName" SG_ 879 EGI3P_CnvtTpSpLimRspValAuth "Serial Data 22 Protected : Convertible Top Speed Limit Response Value Authenticated";
BA_ "SignalType" SG_ 879 EGI3P_CnvtTpSpLimRspTypAuth "ENM";
BA_ "SignalLongName" SG_ 879 EGI3P_CnvtTpSpLimRspTypAuth "Serial Data 22 Protected : Convertible Top Speed Limit Response Type Authenticated";
BA_ "SignalType" SG_ 879 PSP_PrkNeutSwStatAuth_Inv "ENM";
BA_ "SignalLongName" SG_ 879 PSP_PrkNeutSwStatAuth_Inv "Serial Data 22 Protected : Park Neutral Switch State Authenticated Invalid";
BA_ "SignalType" SG_ 879 PSP_PrkNeutSwStatAuth "ENM";
BA_ "SignalLongName" SG_ 879 PSP_PrkNeutSwStatAuth "Serial Data 22 Protected : Park Neutral Switch State Authenticated";
BA_ "SignalType" SG_ 879 PSP_EngRnngAuth "ENM";
BA_ "SignalLongName" SG_ 879 PSP_EngRnngAuth "Serial Data 22 Protected : Engine Running Authenticated";
BA_ "SignalType" SG_ 879 PSP_ClchBtmTrvlAchvdAuth_Inv "ENM";
BA_ "SignalLongName" SG_ 879 PSP_ClchBtmTrvlAchvdAuth_Inv "Serial Data 22 Protected : Clutch Bottom of Travel Achieved Authenticated Invalid";
BA_ "SignalType" SG_ 879 PSP_ClchBtmTrvlAchvdAuth "ENM";
BA_ "SignalLongName" SG_ 879 PSP_ClchBtmTrvlAchvdAuth "Serial Data 22 Protected : Clutch Bottom of Travel Achieved Authenticated";
BA_ "SignalLongName" SG_ 879 SD22P_ARC "Serial Data 22 Protected : Alive Rolling Count";
BA_ "SignalType" SG_ 879 PSP_VehTheftImbChlgRespStsAuth "ENM";
BA_ "SignalLongName" SG_ 879 PSP_VehTheftImbChlgRespStsAuth "Serial Data 22 Protected : Vehicle Theft Immobilizer Challenge Response Status Authenticated";
BA_ "SignalType" SG_ 879 PSP_RmtVehStrtEngRnngAuth "ENM";
BA_ "SignalLongName" SG_ 879 PSP_RmtVehStrtEngRnngAuth "Serial Data 22 Protected : Remote Vehicle Start Engine Running Authenticated";
BA_ "SignalType" SG_ 879 PSP_PwrtrnCrnkAbrtdAuth "ENM";
BA_ "SignalLongName" SG_ 879 PSP_PwrtrnCrnkAbrtdAuth "Serial Data 22 Protected : Powertrain Crank Aborted Authenticated";
BA_ "SignalType" SG_ 879 PSP_PrplSysStlActvAuth "ENM";
BA_ "SignalLongName" SG_ 879 PSP_PrplSysStlActvAuth "Serial Data 22 Protected : Propulsion System Stall Active Authenticated";
BA_ "SignalType" SG_ 879 PSP_PrplSysActvAuth "ENM";
BA_ "SignalLongName" SG_ 879 PSP_PrplSysActvAuth "Serial Data 22 Protected : Propulsion System Active Authenticated";
BA_ "SignalLongName" SG_ 879 SD22P_Filler "Serial Data 22 Protected : Filler";
BA_ "SignalType" SG_ 879 PrplBrkThrotOvrrdReqd "ENM";
BA_ "SignalLongName" SG_ 879 PrplBrkThrotOvrrdReqd "Serial Data 22 Protected : Propulsion Brake Throttle Override Requested";
BA_ "SignalLongName" SG_ 1949 SrlDat234_PCSM "Serial Data 234 Protected Counter Sync Message";
BA_ "SignalLongName" SG_ 1117 SD234P_MAC "Serial Data 234 Protected : MAC";
BA_ "SignalLongName" SG_ 1117 SD234P_FCnt "Serial Data 234 Protected : Freshness Counter";
BA_ "SignalType" SG_ 1117 AE44LtSftBtnReq "ENM";
BA_ "SignalLongName" SG_ 1117 AE44LtSftBtnReq "Serial Data 234 Protected : Advanced Park Assist Left Soft Button Request";
BA_ "SignalType" SG_ 1117 AE44ExtPrkSftBtnReq "ENM";
BA_ "SignalLongName" SG_ 1117 AE44ExtPrkSftBtnReq "Serial Data 234 Protected : Advanced Park Assist Exit Park Soft Button Request";
BA_ "SignalType" SG_ 1117 AE44CrsFrtInSftBtnReq "ENM";
BA_ "SignalLongName" SG_ 1117 AE44CrsFrtInSftBtnReq "Serial Data 234 Protected : Advanced Park Assist Cross Front-In Soft Button Request";
BA_ "SignalType" SG_ 1117 AE44CrsBkInSftBtnReq "ENM";
BA_ "SignalLongName" SG_ 1117 AE44CrsBkInSftBtnReq "Serial Data 234 Protected : Advanced Park Assist Cross Back-In Soft Button Request";
BA_ "SignalLongName" SG_ 1117 SD234P_Filler "Serial Data 234 Protected : Filler";
BA_ "SignalType" SG_ 1117 AE44SrchingSftBtnReq "ENM";
BA_ "SignalLongName" SG_ 1117 AE44SrchingSftBtnReq "Serial Data 234 Protected : Advanced Park Assist Searching Soft Button Request";
BA_ "SignalType" SG_ 1117 AE44RtSftBtnReq "ENM";
BA_ "SignalLongName" SG_ 1117 AE44RtSftBtnReq "Serial Data 234 Protected : Advanced Park Assist Right Soft Button Request";
BA_ "SignalType" SG_ 1117 AE44PrllPrkSftBtnReq "ENM";
BA_ "SignalLongName" SG_ 1117 AE44PrllPrkSftBtnReq "Serial Data 234 Protected : Advanced Park Assist Parallel Parking Soft Button Request";
BA_ "SignalLongName" SG_ 1117 SD234P_ARC "Serial Data 234 Protected : Alive Rolling Count";
BA_ "SignalLongName" SG_ 1375 SrlDat23_PCSM "Serial Data 23 Protected Counter Sync Message";
BA_ "SignalLongName" SG_ 1300 SD23P_MAC "Serial Data 23 Protected : MAC";
BA_ "SignalLongName" SG_ 1300 SD23P_FCnt "Serial Data 23 Protected : Freshness Counter";
BA_ "SignalLongName" SG_ 1300 VOBP_VehOdoBkupAuth "Serial Data 23 Protected : Vehicle Odometer Backup Authenticated";
BA_ "SignalLongName" SG_ 1300 SD23P_Filler "Serial Data 23 Protected : Filler";
BA_ "SignalLongName" SG_ 1300 SD23P_ARC "Serial Data 23 Protected : Alive Rolling Count";
BA_ "SignalType" SG_ 1300 VOBP_VehOdoBkupAuth_Inv "ENM";
BA_ "SignalLongName" SG_ 1300 VOBP_VehOdoBkupAuth_Inv "Serial Data 23 Protected : Vehicle Odometer Backup Authenticated Invalid";
BA_ "SignalLongName" SG_ 1374 SrlDat25_PCSM "Serial Data 25 Protected Counter Sync Message";
BA_ "SignalLongName" SG_ 1313 SD25P_MAC "Serial Data 25 Protected : MAC";
BA_ "SignalLongName" SG_ 1313 SD25P_FCnt "Serial Data 25 Protected : Freshness Counter";
BA_ "SignalLongName" SG_ 1313 OATP_OtsAirTmpAuth "Serial Data 25 Protected : Outside Air Temperature Authenticated";
BA_ "SignalLongName" SG_ 1313 SD25P_FillerExtnd1 "Serial Data 25 Protected : Filler Extended 1";
BA_ "SignalLongName" SG_ 1313 OATP_OtsAirTmpCrValAuth "Serial Data 25 Protected : Outside Air Temperature Corrected Value Authenticated";
BA_ "SignalType" SG_ 1313 OATP_OtsAirTmpAuth_Inv "ENM";
BA_ "SignalLongName" SG_ 1313 OATP_OtsAirTmpAuth_Inv "Serial Data 25 Protected : Outside Air Temperature Authenticated Invalid";
BA_ "SignalLongName" SG_ 1313 SD25P_ARC "Serial Data 25 Protected : Alive Rolling Count";
BA_ "SignalType" SG_ 1313 OATP_OtsAirTmpSrcAuth "ENM";
BA_ "SignalLongName" SG_ 1313 OATP_OtsAirTmpSrcAuth "Serial Data 25 Protected : Outside Air Temperature Source Authenticated";
BA_ "SignalType" SG_ 1313 OATP_OtsAirTmpCrValStAuth "ENM";
BA_ "SignalLongName" SG_ 1313 OATP_OtsAirTmpCrValStAuth "Serial Data 25 Protected : Outside Air Temperature Corrected Value State Authenticated";
BA_ "SignalType" SG_ 1313 OATP_OtsAirTmpCrValAuth_Inv "ENM";
BA_ "SignalLongName" SG_ 1313 OATP_OtsAirTmpCrValAuth_Inv "Serial Data 25 Protected : Outside Air Temperature Corrected Value Authenticated Invalid";
BA_ "SignalLongName" SG_ 1313 SD25P_Filler "Serial Data 25 Protected : Filler";
BA_ "SignalLongName" SG_ 693 SrlDat26_PCSM "Serial Data 26 Protected Counter Sync Message";
BA_ "SignalLongName" SG_ 616 SD26P_MAC "Serial Data 26 Protected : MAC";
BA_ "SignalLongName" SG_ 616 SD26P_FCnt "Serial Data 26 Protected : Freshness Counter";
BA_ "SignalType" SG_ 616 ETRPP_ElcTransRngPriAuth "ENM";
BA_ "SignalLongName" SG_ 616 ETRPP_ElcTransRngPriAuth "Serial Data 26 Protected : Electronic Transmission Range Primary Authenticated";
BA_ "SignalType" SG_ 616 ESAE44CP_ElecShfAE44CtlStsAuth "ENM";
BA_ "SignalLongName" SG_ 616 ESAE44CP_ElecShfAE44CtlStsAuth "Serial Data 26 Protected : Electronic Shift Advanced Park Assist Control Status Authenticated";
BA_ "SignalType" SG_ 616 ESAE44CP_ElecShfAE44CtlStsAtvAut "ENM";
BA_ "SignalLongName" SG_ 616 ESAE44CP_ElecShfAE44CtlStsAtvAut "Serial Data 26 Protected : Electronic Shift Advanced Park Assist Control Status Active Authenticated";
BA_ "SignalLongName" SG_ 616 EGI6P_EShfMPSecurPtrnAuth "Serial Data 26 Protected : Electronic Shift Master Processor Security Pattern Authenticated";
BA_ "SignalType" SG_ 616 HGI1P_SecEngCmptAjrAuth "ENM";
BA_ "SignalLongName" SG_ 616 HGI1P_SecEngCmptAjrAuth "Serial Data 26 Protected : Secondary Engine Compartment Ajar Authenticated";
BA_ "SignalLongName" SG_ 616 SD26P_ARC "Serial Data 26 Protected : Alive Rolling Count";
BA_ "SignalType" SG_ 616 E44BRP_ElecShfAutoBrkgReqdAuth "ENM";
BA_ "SignalLongName" SG_ 616 E44BRP_ElecShfAutoBrkgReqdAuth "Serial Data 26 Protected : Electronic Shift Automatic Braking Requested Authenticated";
BA_ "SignalType" SG_ 616 E44BRP_ElecShfAutoBrkgReqTypAuth "ENM";
BA_ "SignalLongName" SG_ 616 E44BRP_ElecShfAutoBrkgReqTypAuth "Serial Data 26 Protected : Electronic Shift Automatic Braking Request Type Authenticated";
BA_ "SignalLongName" SG_ 616 SD26P_Filler "Serial Data 26 Protected : Filler";
BA_ "SignalType" SG_ 616 HGI1P_SecEngCmptAjrAuth_Inv "ENM";
BA_ "SignalLongName" SG_ 616 HGI1P_SecEngCmptAjrAuth_Inv "Serial Data 26 Protected : Secondary Engine Compartment Ajar Authenticated Invalid";
BA_ "SignalLongName" SG_ 705 EGI4_PrplSysOffTm "Serial Data 29 : Propulsion System Off Time";
BA_ "SignalType" SG_ 705 LDGI1_ECMClrLgslDiagInfo "ENM";
BA_ "SignalLongName" SG_ 705 LDGI1_ECMClrLgslDiagInfo "Serial Data 29 : Engine Control Module Clear Legislated Diagnostic Information";
BA_ "SignalType" SG_ 705 EngWrmUpAch "ENM";
BA_ "SignalLongName" SG_ 705 EngWrmUpAch "Serial Data 29 : Engine Warm Up Cycle Achieved";
BA_ "SignalType" SG_ 705 EGI4_PrplSysOffTm_Inv "ENM";
BA_ "SignalLongName" SG_ 705 EGI4_PrplSysOffTm_Inv "Serial Data 29 : Propulsion System Off Time Invalid";
BA_ "SignalType" SG_ 705 EGI4_PrplSysOffTm_DuD "ENM";
BA_ "SignalLongName" SG_ 705 EGI4_PrplSysOffTm_DuD "Serial Data 29 : Propulsion System Off Time Don't Use Data";
BA_ "SignalType" SG_ 705 LgslPstDTCClrDrvCyCmp "ENM";
BA_ "SignalLongName" SG_ 705 LgslPstDTCClrDrvCyCmp "Serial Data 29 : Legislated Post DTC Clear Drive Cycle Complete";
BA_ "SignalType" SG_ 705 LgslDiagMxEngCltTmpRchd "ENM";
BA_ "SignalLongName" SG_ 705 LgslDiagMxEngCltTmpRchd "Serial Data 29 : Legislated Diagnostics Maximum Engine Coolant Temperature Reached";
BA_ "SignalType" SG_ 705 LDGI1_LgslDiagStdCondsMet "ENM";
BA_ "SignalLongName" SG_ 705 LDGI1_LgslDiagStdCondsMet "Serial Data 29 : Legislated Diagnostics Standard Conditions Met";
BA_ "SignalType" SG_ 705 LDGI1_LgslDiagStdCondsFltPr "ENM";
BA_ "SignalLongName" SG_ 705 LDGI1_LgslDiagStdCondsFltPr "Serial Data 29 : Legislated Diagnostics Standard Conditions Fault Present";
BA_ "SignalType" SG_ 705 LDGI1_LgslDiagMinEngClTmpRchd "ENM";
BA_ "SignalLongName" SG_ 705 LDGI1_LgslDiagMinEngClTmpRchd "Serial Data 29 : Legislated Diagnostics Minimum Engine Coolant Temperature Reached";
BA_ "SignalType" SG_ 705 LDGI1_LgslDiagCldStrtCondsMet "ENM";
BA_ "SignalLongName" SG_ 705 LDGI1_LgslDiagCldStrtCondsMet "Serial Data 29 : Legislated Diagnostics Cold Start Conditions Met";
BA_ "SignalType" SG_ 705 LDGI1_LgslDiagCldStrtCondsFltPr "ENM";
BA_ "SignalLongName" SG_ 705 LDGI1_LgslDiagCldStrtCondsFltPr "Serial Data 29 : Legislated Diagnostics Cold Start Conditions Fault Present";
BA_ "SignalLongName" SG_ 705 SD29_CS "Serial Data 29 : Checksum";
BA_ "SignalLongName" SG_ 705 SD29_ARC "Serial Data 29 : Alive Rolling Count";
BA_ "SignalLongName" SG_ 683 SrlDat2_PCSM "Serial Data 2 Protected Counter Sync Message";
BA_ "SignalLongName" SG_ 634 SD2P_MAC "Serial Data 2 Protected : MAC";
BA_ "SignalLongName" SG_ 634 SD2P_FCnt "Serial Data 2 Protected : Freshness Counter";
BA_ "SignalType" SG_ 634 RCIP_PwrRrClsrMtnCmdAuth "ENM";
BA_ "SignalLongName" SG_ 634 RCIP_PwrRrClsrMtnCmdAuth "Serial Data 2 Protected : Power Rear Closure Motion Command Authenticated";
BA_ "SignalType" SG_ 634 RCIP_ExtRrClsrRelReqAuth "ENM";
BA_ "SignalLongName" SG_ 634 RCIP_ExtRrClsrRelReqAuth "Serial Data 2 Protected : Exterior Rear Closure Release Request Authenticated";
BA_ "SignalType" SG_ 634 BGI1P_OutsdAmbtLgtLvlStsAuth "ENM";
BA_ "SignalLongName" SG_ 634 BGI1P_OutsdAmbtLgtLvlStsAuth "Serial Data 2 Protected : Outside Ambient Light Level Status Authenticated";
BA_ "SignalType" SG_ 634 BGI1P_DrvrDrOpnStsAuth_Inv "ENM";
BA_ "SignalLongName" SG_ 634 BGI1P_DrvrDrOpnStsAuth_Inv "Serial Data 2 Protected : Driver Door Open Status Authenticated Invalid";
BA_ "SignalType" SG_ 634 BGI1P_DrvrDrOpnStsAuth_DuD "ENM";
BA_ "SignalLongName" SG_ 634 BGI1P_DrvrDrOpnStsAuth_DuD "Serial Data 2 Protected : Driver Door Open Status Authenticated Don't Use Data";
BA_ "SignalType" SG_ 634 BGI1P_DrvrDrOpnStsAuth "ENM";
BA_ "SignalLongName" SG_ 634 BGI1P_DrvrDrOpnStsAuth "Serial Data 2 Protected : Driver Door Open Status Authenticated";
BA_ "SignalLongName" SG_ 634 SD2P_FillerExtnd1 "Serial Data 2 Protected : Filler Extended 1";
BA_ "SignalType" SG_ 634 PwrRrClsrModeSeltn "ENM";
BA_ "SignalLongName" SG_ 634 PwrRrClsrModeSeltn "Serial Data 2 Protected : Power Rear Closure Mode Selection";
BA_ "SignalType" SG_ 634 RCIP_RrClsrMtnCtlParmEnblAuth "ENM";
BA_ "SignalLongName" SG_ 634 RCIP_RrClsrMtnCtlParmEnblAuth "Serial Data 2 Protected : Rear Closure Motion Controllable Parameters Enable Authenticated";
BA_ "SignalType" SG_ 634 RCIP_PwrRrClsrMtnReqrAuth "ENM";
BA_ "SignalLongName" SG_ 634 RCIP_PwrRrClsrMtnReqrAuth "Serial Data 2 Protected : Power Rear Closure Motion Requestor Authenticated";
BA_ "SignalType" SG_ 634 E49RmtStrtMstrEngShtdnReqdAuth "ENM";
BA_ "SignalLongName" SG_ 634 E49RmtStrtMstrEngShtdnReqdAuth "Serial Data 2 Protected : Power Take Off Remote Start Master Engine Shutdown Requested Authenticated";
BA_ "SignalType" SG_ 634 FrtStrgeCmptExtRelReqAuth "ENM";
BA_ "SignalLongName" SG_ 634 FrtStrgeCmptExtRelReqAuth "Serial Data 2 Protected : Front Storage Compartment Exterior Release Request Authenticated";
BA_ "SignalType" SG_ 634 FrtStrgeCmptClsrLckSts "ENM";
BA_ "SignalLongName" SG_ 634 FrtStrgeCmptClsrLckSts "Serial Data 2 Protected : Front Storage Compartment Closure Lock Status Authenticated";
BA_ "SignalType" SG_ 634 RrStrgModeSwStsAuth "ENM";
BA_ "SignalLongName" SG_ 634 RrStrgModeSwStsAuth "Serial Data 2 Protected : Rear Steering Mode Switch Status Authenticated";
BA_ "SignalLongName" SG_ 634 SD2P_ARC "Serial Data 2 Protected : Alive Rolling Count";
BA_ "SignalLongName" SG_ 634 SD2P_Filler "Serial Data 2 Protected : Filler";
BA_ "SignalType" SG_ 634 PwrFrtStrgeCmptMtnReqrAuth "ENM";
BA_ "SignalLongName" SG_ 634 PwrFrtStrgeCmptMtnReqrAuth "Serial Data 2 Protected : Power Front Storage Compartment Motion Requestor Authenticated";
BA_ "SignalType" SG_ 634 PwrFrtStrgeCmptMtnCmdAuth "ENM";
BA_ "SignalLongName" SG_ 634 PwrFrtStrgeCmptMtnCmdAuth "Serial Data 2 Protected : Power Front Storage Compartment Motion Command Authenticated";
BA_ "SignalType" SG_ 634 E49RmtStrtMstrEngStrtReqAuth "ENM";
BA_ "SignalLongName" SG_ 634 E49RmtStrtMstrEngStrtReqAuth "Serial Data 2 Protected : Power Take Off Remote Start Master Engine Start Request Authenticated";
BA_ "SignalLongName" SG_ 904 SrlDat30_PCSM "Serial Data 30 Protected Counter Sync Message";
BA_ "SignalLongName" SG_ 72 SD30P_MAC "Serial Data 30 Protected : MAC";
BA_ "SignalLongName" SG_ 72 SD30P_FCnt "Serial Data 30 Protected : Freshness Counter";
BA_ "SignalType" SG_ 72 TGIP_TrnsEgdPrFlwStAuth "ENM";
BA_ "SignalLongName" SG_ 72 TGIP_TrnsEgdPrFlwStAuth "Serial Data 30 Protected : Transmission Engaged Powerflow State Authenticated";
BA_ "SignalType" SG_ 72 TARSP_TransActlRngAuth_Inv "ENM";
BA_ "SignalLongName" SG_ 72 TARSP_TransActlRngAuth_Inv "Serial Data 30 Protected : Transmission Actual Range Authenticated Invalid";
BA_ "SignalType" SG_ 72 TARSP_TransActlRngAuth_DuD "ENM";
BA_ "SignalLongName" SG_ 72 TARSP_TransActlRngAuth_DuD "Serial Data 30 Protected : Transmission Actual Range Authenticated Don't Use Data";
BA_ "SignalType" SG_ 72 TARSP_TransActlRngAuth "ENM";
BA_ "SignalLongName" SG_ 72 TARSP_TransActlRngAuth "Serial Data 30 Protected : Transmission Actual Range Authenticated";
BA_ "SignalType" SG_ 72 TRDP_TrnsPkRgDgLtFltAuth "ENM";
BA_ "SignalLongName" SG_ 72 TRDP_TrnsPkRgDgLtFltAuth "Serial Data 30 Protected : Transmission Park Range Diagnostic Limited Fault Authenticated";
BA_ "SignalType" SG_ 72 TRDP_TrnsPkRgDgCtFltAuth "ENM";
BA_ "SignalLongName" SG_ 72 TRDP_TrnsPkRgDgCtFltAuth "Serial Data 30 Protected : Transmission Park Range Diagnostic Critical Fault Authenticated";
BA_ "SignalType" SG_ 72 TRDP_TrnsNtRgDgLtFltAuth "ENM";
BA_ "SignalLongName" SG_ 72 TRDP_TrnsNtRgDgLtFltAuth "Serial Data 30 Protected : Transmission Neutral Range Diagnostic Limited Fault Authenticated";
BA_ "SignalType" SG_ 72 TRDP_TrnsNtRgDgCtFltAuth "ENM";
BA_ "SignalLongName" SG_ 72 TRDP_TrnsNtRgDgCtFltAuth "Serial Data 30 Protected : Transmission Neutral Range Diagnostic Critical Fault Authenticated";
BA_ "SignalType" SG_ 72 TRDP_TrnsFwDrvRDLFltAuth "ENM";
BA_ "SignalLongName" SG_ 72 TRDP_TrnsFwDrvRDLFltAuth "Serial Data 30 Protected : Transmission Forward Drive Range Diagnostic Limited Fault Authenticated";
BA_ "SignalType" SG_ 72 TRDP_TrnsFwDrvRDCFltAuth "ENM";
BA_ "SignalLongName" SG_ 72 TRDP_TrnsFwDrvRDCFltAuth "Serial Data 30 Protected : Transmission Forward Drive Range Diagnostic Critical Fault Authenticated";
BA_ "SignalType" SG_ 72 TGIP_TrnsEgdPrFlwStAuth_Inv "ENM";
BA_ "SignalLongName" SG_ 72 TGIP_TrnsEgdPrFlwStAuth_Inv "Serial Data 30 Protected : Transmission Engaged Powerflow State Authenticated Invalid";
BA_ "SignalLongName" SG_ 72 SD30P_Filler "Serial Data 30 Protected : Filler";
BA_ "SignalLongName" SG_ 72 SD30P_ARC "Serial Data 30 Protected : Alive Rolling Count";
BA_ "SignalType" SG_ 72 TSP_TmpDrvrShfCtlActvAuth "ENM";
BA_ "SignalLongName" SG_ 72 TSP_TmpDrvrShfCtlActvAuth "Serial Data 30 Protected : Temporary Driver Shift Control Active Authenticated";
BA_ "SignalType" SG_ 72 TSP_ElecRngSeltnInDrvActvAuth "ENM";
BA_ "SignalLongName" SG_ 72 TSP_ElecRngSeltnInDrvActvAuth "Serial Data 30 Protected : Electronic Range Selection in Drive Active Authenticated";
BA_ "SignalType" SG_ 72 TRDP_TrnsRvRgDgLtFltAuth "ENM";
BA_ "SignalLongName" SG_ 72 TRDP_TrnsRvRgDgLtFltAuth "Serial Data 30 Protected : Transmission Reverse Range Diagnostic Limited Fault Authenticated";
BA_ "SignalType" SG_ 72 TRDP_TrnsRvRgDgCtFltAuth "ENM";
BA_ "SignalLongName" SG_ 72 TRDP_TrnsRvRgDgCtFltAuth "Serial Data 30 Protected : Transmission Reverse Range Diagnostic Critical Fault Authenticated";
BA_ "SignalLongName" SG_ 903 SrlDat31_PCSM "Serial Data 31 Protected Counter Sync Message";
BA_ "SignalLongName" SG_ 101 SD31P_MAC "Serial Data 31 Protected : MAC";
BA_ "SignalLongName" SG_ 101 SD31P_FCnt "Serial Data 31 Protected : Freshness Counter";
BA_ "SignalLongName" SG_ 101 HVGI3P_HVBNegChsGndVltgAuth "Serial Data 31 Protected : High Voltage Bus Negative To Chassis Ground Voltage Authenticated";
BA_ "SignalType" SG_ 101 HVGI3P_HVBNegChsGndVltgAuth_Inv "ENM";
BA_ "SignalLongName" SG_ 101 HVGI3P_HVBNegChsGndVltgAuth_Inv "Serial Data 31 Protected : High Voltage Bus Negative To Chassis Ground Voltage Authenticated Invalid";
BA_ "SignalType" SG_ 101 HVGI3P_HVBNegChsGndVltgAuth_DuD "ENM";
BA_ "SignalLongName" SG_ 101 HVGI3P_HVBNegChsGndVltgAuth_DuD "Serial Data 31 Protected : High Voltage Bus Negative To Chassis Ground Voltage Authenticated Don't Use Data";
BA_ "SignalLongName" SG_ 101 HVGI3P_HVBPosChsGndVltgAuth "Serial Data 31 Protected : High Voltage Bus Positive To Chassis Ground Voltage Authenticated";
BA_ "SignalType" SG_ 101 HVGI3P_HVBPosChsGndVltgAuth_Inv "ENM";
BA_ "SignalLongName" SG_ 101 HVGI3P_HVBPosChsGndVltgAuth_Inv "Serial Data 31 Protected : High Voltage Bus Positive To Chassis Ground Voltage Authenticated Invalid";
BA_ "SignalType" SG_ 101 HVGI3P_HVBPosChsGndVltgAuth_DuD "ENM";
BA_ "SignalLongName" SG_ 101 HVGI3P_HVBPosChsGndVltgAuth_DuD "Serial Data 31 Protected : High Voltage Bus Positive To Chassis Ground Voltage Authenticated Don't Use Data";
BA_ "SignalLongName" SG_ 101 HVGI3P_HVIRatlzdVltgPriAuth "Serial Data 31 Protected : High Voltage Inverter Rationalized Voltage Primary Authenticated";
BA_ "SignalType" SG_ 101 HVGI3P_HVPsvIsltnStsAuth "ENM";
BA_ "SignalLongName" SG_ 101 HVGI3P_HVPsvIsltnStsAuth "Serial Data 31 Protected : High Voltage Passive Isolation Status Authenticated";
BA_ "SignalType" SG_ 101 HVGI3P_HVIRatlzdVltgPriAuth_Inv "ENM";
BA_ "SignalLongName" SG_ 101 HVGI3P_HVIRatlzdVltgPriAuth_Inv "Serial Data 31 Protected : High Voltage Inverter Rationalized Voltage Primary Authenticated Invalid";
BA_ "SignalLongName" SG_ 101 PSATDP_SecATActlAuth "Serial Data 31 Protected : Propulsion System Secondary Axle Torque Actual Authenticated";
BA_ "SignalLongName" SG_ 101 SD31P_FillerExtnd "Serial Data 31 Protected : Filler Extended";
BA_ "SignalType" SG_ 101 HVGI3P_PwrtrnHVShtdnCmpltdAuth "ENM";
BA_ "SignalLongName" SG_ 101 HVGI3P_PwrtrnHVShtdnCmpltdAuth "Serial Data 31 Protected : Powertrain High Voltage Shutdown Completed Authenticated";
BA_ "SignalType" SG_ 101 HVGI3P_PwrtrnHVCntctrReqPriAuth "ENM";
BA_ "SignalLongName" SG_ 101 HVGI3P_PwrtrnHVCntctrReqPriAuth "Serial Data 31 Protected : Powertrain High Voltage Contactor Request Primary Authenticated";
BA_ "SignalLongName" SG_ 101 PSATDP_SecATCapMaxAuth "Serial Data 31 Protected : Propulsion System Secondary Axle Torque Capacity Maximum Authenticated";
BA_ "SignalType" SG_ 101 PSATDP_SecATActlAuth_Inv "ENM";
BA_ "SignalLongName" SG_ 101 PSATDP_SecATActlAuth_Inv "Serial Data 31 Protected : Propulsion System Secondary Axle Torque Actual Authenticated Invalid";
BA_ "SignalLongName" SG_ 101 PSATDP_SecATCapMinAuth "Serial Data 31 Protected : Propulsion System Secondary Axle Torque Capacity Minimum Authenticated";
BA_ "SignalLongName" SG_ 101 SD31P_ARC "Serial Data 31 Protected : Alive Rolling Count";
BA_ "SignalType" SG_ 101 HVGI9P_ESSPrplSysReqPriAuth "ENM";
BA_ "SignalLongName" SG_ 101 HVGI9P_ESSPrplSysReqPriAuth "Serial Data 31 Protected : Energy Storage System Propulsion System Request Primary Authenticated";
BA_ "SignalLongName" SG_ 101 SD31P_Filler "Serial Data 31 Protected : Filler";
BA_ "SignalLongName" SG_ 1397 SrlDat34_PCSM "Serial Data 34 Protected Counter Sync Message";
BA_ "SignalLongName" SG_ 881 SD34P_MAC "Serial Data 34 Protected : MAC";
BA_ "SignalLongName" SG_ 881 SD34P_FCnt "Serial Data 34 Protected : Freshness Counter";
BA_ "SignalType" SG_ 881 ASDRP_LnCntrWrnExtdIndReqAuth "ENM";
BA_ "SignalLongName" SG_ 881 ASDRP_LnCntrWrnExtdIndReqAuth "Serial Data 34 Protected : Lane Centering Warning Extended Indication Request Authenticated";
BA_ "SignalType" SG_ 881 ASDRP_LnCntrCtlIndReqAuth "ENM";
BA_ "SignalLongName" SG_ 881 ASDRP_LnCntrCtlIndReqAuth "Serial Data 34 Protected : Lane Centering Control Indication Request Authenticated";
BA_ "SignalType" SG_ 881 ACGIP_SrrndVsnRLSModeCmdAuth "ENM";
BA_ "SignalLongName" SG_ 881 ACGIP_SrrndVsnRLSModeCmdAuth "Serial Data 34 Protected : Surround Vision Redundant Lane Sensing Mode Command Authenticated";
BA_ "SignalType" SG_ 881 ACGIP_LnFllwFltIndcdAtBrkEnAuth "ENM";
BA_ "SignalLongName" SG_ 881 ACGIP_LnFllwFltIndcdAtBrkEnAuth "Serial Data 34 Protected : Lane Following Fault Induced Auto Braking Enabled Authenticated";
BA_ "SignalType" SG_ 881 HMIR1P_LnFllwgLHSChEvntStatAuth "ENM";
BA_ "SignalLongName" SG_ 881 HMIR1P_LnFllwgLHSChEvntStatAuth "Serial Data 34 Protected : Lane Following Left Hand Side Chime Event State Authenticated";
BA_ "SignalType" SG_ 881 HMIR1P_LnFllwgGenChEvntStatAuth "ENM";
BA_ "SignalLongName" SG_ 881 HMIR1P_LnFllwgGenChEvntStatAuth "Serial Data 34 Protected : Lane Following General Chime Event State Authenticated";
BA_ "SignalType" SG_ 881 ASTIP_LnCntrVehStopdAuth "ENM";
BA_ "SignalLongName" SG_ 881 ASTIP_LnCntrVehStopdAuth "Serial Data 34 Protected : Lane Centering Vehicle Stopped Authenticated";
BA_ "SignalLongName" SG_ 881 SD34P_Filler "Serial Data 34 Protected : Filler";
BA_ "SignalLongName" SG_ 881 SD34P_ARC "Serial Data 34 Protected : Alive Rolling Count";
BA_ "SignalType" SG_ 881 HMIR1P_LnFllwgRHSChEvntStatAuth "ENM";
BA_ "SignalLongName" SG_ 881 HMIR1P_LnFllwgRHSChEvntStatAuth "Serial Data 34 Protected : Lane Following Right Hand Side Chime Event State Authenticated";
BA_ "SignalLongName" SG_ 902 SrlDat35_PCSM "Serial Data 35 Protected Counter Sync Message";
BA_ "SignalLongName" SG_ 526 SD35P_MAC "Serial Data 35 Protected : MAC";
BA_ "SignalLongName" SG_ 526 SD35P_FCnt "Serial Data 35 Protected : Freshness Counter";
BA_ "SignalLongName" SG_ 526 ACCATRIP_TrqMagAuth "Serial Data 35 Protected : Torque Magnitude Authenticated";
BA_ "SignalType" SG_ 526 ACCATRIP_TrqDrvAstGoStatAuth "ENM";
BA_ "SignalLongName" SG_ 526 ACCATRIP_TrqDrvAstGoStatAuth "Serial Data 35 Protected : Torque Driver Assisted Go State Authenticated";
BA_ "SignalType" SG_ 526 ACCATRIP_TrqActvAuth "ENM";
BA_ "SignalLongName" SG_ 526 ACCATRIP_TrqActvAuth "Serial Data 35 Protected : Torque Active Authenticated";
BA_ "SignalType" SG_ 526 ACCATRIP_TrqTypAuth "ENM";
BA_ "SignalLongName" SG_ 526 ACCATRIP_TrqTypAuth "Serial Data 35 Protected : Torque Type Authenticated";
BA_ "SignalLongName" SG_ 526 ACCBRP_ReqMagAuth "Serial Data 35 Protected : Adaptive Cruise Control Braking Request Magnitude Authenticated";
BA_ "SignalType" SG_ 526 ACCBRP_ReqActvAuth "ENM";
BA_ "SignalLongName" SG_ 526 ACCBRP_ReqActvAuth "Serial Data 35 Protected : Adaptive Cruise Control Braking Request Active Authenticated";
BA_ "SignalType" SG_ 526 ACCBRP_ACCActvAuth "ENM";
BA_ "SignalLongName" SG_ 526 ACCBRP_ACCActvAuth "Serial Data 35 Protected : Adaptive Cruise Control Active Authenticated";
BA_ "SignalType" SG_ 526 ACCBRP_ReqTypAuth "ENM";
BA_ "SignalLongName" SG_ 526 ACCBRP_ReqTypAuth "Serial Data 35 Protected : Adaptive Cruise Control Braking Request Type Authenticated";
BA_ "SignalLongName" SG_ 526 ClsnImntBrkgAxlTrqRqAuth "Serial Data 35 Protected : Collision Imminent Braking Axle Torque Request Authenticated";
BA_ "SignalType" SG_ 526 ClsnImntBrkgAxlTrqRqActvAuth "ENM";
BA_ "SignalLongName" SG_ 526 ClsnImntBrkgAxlTrqRqActvAuth "Serial Data 35 Protected : Collision Imminent Braking Axle Torque Request Active Authenticated";
BA_ "SignalLongName" SG_ 526 SD35P_Filler "Serial Data 35 Protected : Filler";
BA_ "SignalLongName" SG_ 526 SD35P_ARC "Serial Data 35 Protected : Alive Rolling Count";
BA_ "SignalType" SG_ 526 LCCPIP_LnCntrCtlActvAuth "ENM";
BA_ "SignalLongName" SG_ 526 LCCPIP_LnCntrCtlActvAuth "Serial Data 35 Protected : Lane Centering Control Active Authenticated";
BA_ "SignalType" SG_ 526 LCCPIP_LnCntrCtlAclPedLimRqAuth "ENM";
BA_ "SignalLongName" SG_ 526 LCCPIP_LnCntrCtlAclPedLimRqAuth "Serial Data 35 Protected : Lane Centering Control Accel Pedal Limiting Requested Authenticated";
BA_ "SignalLongName" SG_ 901 SrlDat36_PCSM "Serial Data 36 Protected Counter Sync Message";
VAL_ 173 Sig5774 0 "Highly Speculative" 1 "Speculative" 2 "Confident" 3 "Highly Confident" ;
VAL_ 173 Sig5773 0 "FALSE" 1 "TRUE" ;
VAL_ 173 Sig5858 0 "Has Never Moved" 1 "Has Moved But Currently Stopped" 2 "Moving In Same Direction As Host" 3 "Moving In Opposite Direction As Host" 4 "Crossing Path" ;
VAL_ 173 Sig5857 0 "Highly Speculative" 1 "Speculative" 2 "Confident" 3 "Highly Confident" ;
VAL_ 173 Sig5856 0 "Not Radiating" 1 "Reporting Object Data" 2 "Not Reporting Object Data" ;
VAL_ 173 Sig5775 0 "Not Detected" 1 "Detected" 2 "Unknown" ;
VAL_ 173 Sig5861 0 "No Object" 1 "New Object" 2 "Latent Track Not Detected this Cycle" 3 "Measured this Cycle" ;
VAL_ 173 Sig5870 0 "Highly Speculative" 1 "Speculative" 2 "Confident" 3 "Highly Confident" ;
VAL_ 173 Sig5869 0 "Highly Speculative" 1 "Speculative" 2 "Confident" 3 "Highly Confident" ;
VAL_ 173 Sig5868 0 "Unknown" 1 "Pedestrian" 2 "Bicycle" ;
VAL_ 173 Sig5871 0 "Has Never Moved" 1 "Has Moved But Currently Stopped" 2 "Moving In Same Direction As Host" 3 "Moving In Opposite Direction As Host" 4 "Crossing Path" ;
VAL_ 173 Sig5874 0 "No Object" 1 "New Object" 2 "Latent Track Not Detected this Cycle" 3 "Measured this Cycle" ;
VAL_ 173 Sig5882 0 "Highly Speculative" 1 "Speculative" 2 "Confident" 3 "Highly Confident" ;
VAL_ 173 Sig5881 0 "Unknown" 1 "Pedestrian" 2 "Bicycle" ;
VAL_ 173 Sig5954 0 "FALSE" 1 "TRUE" ;
VAL_ 173 Sig5953 0 "FALSE" 1 "TRUE" ;
VAL_ 173 Sig5952 0 "FALSE" 1 "TRUE" ;
VAL_ 173 Sig5950 0 "Highly Speculative" 1 "Speculative" 2 "Confident" 3 "Highly Confident" ;
VAL_ 173 Sig5949 0 "Unknown" 1 "City" 2 "Secondary Road" 3 "Highway" 4 "Construction Zone Entry" 5 "Construction Zone Exit" ;
VAL_ 173 Sig5955 0 "Mode A" 1 "Mode B" 2 "Mode C" 3 "Mode D" ;
VAL_ 173 Sig5979 0 "Stopped" 1 "Not Stopped" ;
VAL_ 173 Sig5978 0 "Has Never Moved" 1 "Moving In Same Direction As Host" 2 "Moving In Opposite Direction As Host" 3 "Crossing From Left To Right" 4 "Crossing From Right To Left" ;
VAL_ 173 Sig5977 0 "Highly Speculative" 1 "Speculative" 2 "Confident" 3 "Highly Confident" ;
VAL_ 173 Sig5981 0 "No Object" 1 "New Object" 2 "Latent Track Not Detected this Cycle" 3 "Measured this Cycle" ;
VAL_ 173 Sig5995 0 "Highly Speculative" 1 "Speculative" 2 "Confident" 3 "Highly Confident" ;
VAL_ 166 Sig5922 0 "Highly Speculative" 1 "Speculative" 2 "Confident" 3 "Highly Confident" ;
VAL_ 166 Sig5930 0 "Highly Speculative" 1 "Speculative" 2 "Confident" 3 "Highly Confident" ;
VAL_ 166 Sig5929 0 "Unknown" 1 "Barriers" 2 "Guard Rails" 3 "Bridge Abutments" 4 "Edge of Road" 5 "Open Area" ;
VAL_ 166 Sig5931 0 "Highly Speculative" 1 "Speculative" 2 "Confident" 3 "Highly Confident" ;
VAL_ 166 Sig5939 0 "Highly Speculative" 1 "Speculative" 2 "Confident" 3 "Highly Confident" ;
VAL_ 166 Sig5938 0 "Unknown" 1 "Barriers" 2 "Guard Rails" 3 "Bridge Abutments" 4 "Edge of Road" 5 "Open Area" ;
VAL_ 166 Sig5940 0 "Highly Speculative" 1 "Speculative" 2 "Confident" 3 "Highly Confident" ;
VAL_ 166 Sig5948 0 "Highly Speculative" 1 "Speculative" 2 "Confident" 3 "Highly Confident" ;
VAL_ 166 Sig5947 0 "Unknown" 1 "Barriers" 2 "Guard Rails" 3 "Bridge Abutments" 4 "Edge of Road" 5 "Open Area" ;
VAL_ 163 Sig6317 0 "Has Never Moved" 1 "Has Moved But Currently Stopped" 2 "Moving In Same Direction As Host" 3 "Moving In Opposite Direction As Host" 4 "Crossing Path" ;
VAL_ 163 Sig6316 0 "Highly Speculative" 1 "Speculative" 2 "Confident" 3 "Highly Confident" ;
VAL_ 163 Sig6320 0 "No Object" 1 "New Object" 2 "Latent Track Not Detected this Cycle" 3 "Measured this Cycle" ;
VAL_ 163 Sig6328 0 "Highly Speculative" 1 "Speculative" 2 "Confident" 3 "Highly Confident" ;
VAL_ 163 Sig6327 0 "Unknown" 1 "Pedestrian" 2 "Bicycle" ;
VAL_ 163 Sig6470 0 "Stopped" 1 "Not Stopped" ;
VAL_ 163 Sig6469 0 "Has Never Moved" 1 "Moving In Same Direction As Host" 2 "Moving In Opposite Direction As Host" 3 "Crossing From Left To Right" 4 "Crossing From Right To Left" ;
VAL_ 163 Sig6468 0 "Highly Speculative" 1 "Speculative" 2 "Confident" 3 "Highly Confident" ;
VAL_ 163 Sig6472 0 "No Object" 1 "New Object" 2 "Latent Track Not Detected this Cycle" 3 "Measured this Cycle" ;
VAL_ 163 Sig6486 0 "Highly Speculative" 1 "Speculative" 2 "Confident" 3 "Highly Confident" ;
VAL_ 163 Sig6488 0 "Highly Speculative" 1 "Speculative" 2 "Confident" 3 "Highly Confident" ;
VAL_ 163 Sig6490 0 "Stopped" 1 "Not Stopped" ;
VAL_ 163 Sig6489 0 "Has Never Moved" 1 "Moving In Same Direction As Host" 2 "Moving In Opposite Direction As Host" 3 "Crossing From Left To Right" 4 "Crossing From Right To Left" ;
VAL_ 163 Sig6492 0 "No Object" 1 "New Object" 2 "Latent Track Not Detected this Cycle" 3 "Measured this Cycle" ;
VAL_ 163 Sig6506 0 "Highly Speculative" 1 "Speculative" 2 "Confident" 3 "Highly Confident" ;
VAL_ 163 Sig6510 0 "Stopped" 1 "Not Stopped" ;
VAL_ 163 Sig6509 0 "Has Never Moved" 1 "Moving In Same Direction As Host" 2 "Moving In Opposite Direction As Host" 3 "Crossing From Left To Right" 4 "Crossing From Right To Left" ;
VAL_ 163 Sig6508 0 "Highly Speculative" 1 "Speculative" 2 "Confident" 3 "Highly Confident" ;
VAL_ 163 Sig6512 0 "No Object" 1 "New Object" 2 "Latent Track Not Detected this Cycle" 3 "Measured this Cycle" ;
VAL_ 163 Sig6526 0 "Highly Speculative" 1 "Speculative" 2 "Confident" 3 "Highly Confident" ;
VAL_ 161 Sig6330 0 "Has Never Moved" 1 "Has Moved But Currently Stopped" 2 "Moving In Same Direction As Host" 3 "Moving In Opposite Direction As Host" 4 "Crossing Path" ;
VAL_ 161 Sig6329 0 "Highly Speculative" 1 "Speculative" 2 "Confident" 3 "Highly Confident" ;
VAL_ 161 Sig6333 0 "No Object" 1 "New Object" 2 "Latent Track Not Detected this Cycle" 3 "Measured this Cycle" ;
VAL_ 161 Sig6341 0 "Highly Speculative" 1 "Speculative" 2 "Confident" 3 "Highly Confident" ;
VAL_ 161 Sig6340 0 "Unknown" 1 "Pedestrian" 2 "Bicycle" ;
VAL_ 161 Sig6530 0 "Stopped" 1 "Not Stopped" ;
VAL_ 161 Sig6529 0 "Has Never Moved" 1 "Moving In Same Direction As Host" 2 "Moving In Opposite Direction As Host" 3 "Crossing From Left To Right" 4 "Crossing From Right To Left" ;
VAL_ 161 Sig6528 0 "Highly Speculative" 1 "Speculative" 2 "Confident" 3 "Highly Confident" ;
VAL_ 161 Sig6532 0 "No Object" 1 "New Object" 2 "Latent Track Not Detected this Cycle" 3 "Measured this Cycle" ;
VAL_ 161 Sig6546 0 "Highly Speculative" 1 "Speculative" 2 "Confident" 3 "Highly Confident" ;
VAL_ 161 Sig6548 0 "Highly Speculative" 1 "Speculative" 2 "Confident" 3 "Highly Confident" ;
VAL_ 161 Sig6550 0 "Stopped" 1 "Not Stopped" ;
VAL_ 161 Sig6549 0 "Has Never Moved" 1 "Moving In Same Direction As Host" 2 "Moving In Opposite Direction As Host" 3 "Crossing From Left To Right" 4 "Crossing From Right To Left" ;
VAL_ 161 Sig6552 0 "No Object" 1 "New Object" 2 "Latent Track Not Detected this Cycle" 3 "Measured this Cycle" ;
VAL_ 161 Sig6566 0 "Highly Speculative" 1 "Speculative" 2 "Confident" 3 "Highly Confident" ;
VAL_ 161 Sig6570 0 "Stopped" 1 "Not Stopped" ;
VAL_ 161 Sig6569 0 "Has Never Moved" 1 "Moving In Same Direction As Host" 2 "Moving In Opposite Direction As Host" 3 "Crossing From Left To Right" 4 "Crossing From Right To Left" ;
VAL_ 161 Sig6568 0 "Highly Speculative" 1 "Speculative" 2 "Confident" 3 "Highly Confident" ;
VAL_ 161 Sig6572 0 "No Object" 1 "New Object" 2 "Latent Track Not Detected this Cycle" 3 "Measured this Cycle" ;
VAL_ 161 Sig6586 0 "Highly Speculative" 1 "Speculative" 2 "Confident" 3 "Highly Confident" ;
VAL_ 160 Sig6343 0 "Has Never Moved" 1 "Has Moved But Currently Stopped" 2 "Moving In Same Direction As Host" 3 "Moving In Opposite Direction As Host" 4 "Crossing Path" ;
VAL_ 160 Sig6342 0 "Highly Speculative" 1 "Speculative" 2 "Confident" 3 "Highly Confident" ;
VAL_ 160 Sig6346 0 "No Object" 1 "New Object" 2 "Latent Track Not Detected this Cycle" 3 "Measured this Cycle" ;
VAL_ 160 Sig6354 0 "Highly Speculative" 1 "Speculative" 2 "Confident" 3 "Highly Confident" ;
VAL_ 160 Sig6353 0 "Unknown" 1 "Pedestrian" 2 "Bicycle" ;
VAL_ 160 Sig6430 0 "Stopped" 1 "Not Stopped" ;
VAL_ 160 Sig6429 0 "Has Never Moved" 1 "Moving In Same Direction As Host" 2 "Moving In Opposite Direction As Host" 3 "Crossing From Left To Right" 4 "Crossing From Right To Left" ;
VAL_ 160 Sig6428 0 "Highly Speculative" 1 "Speculative" 2 "Confident" 3 "Highly Confident" ;
VAL_ 160 Sig6432 0 "No Object" 1 "New Object" 2 "Latent Track Not Detected this Cycle" 3 "Measured this Cycle" ;
VAL_ 160 Sig6446 0 "Highly Speculative" 1 "Speculative" 2 "Confident" 3 "Highly Confident" ;
VAL_ 160 Sig6588 0 "Highly Speculative" 1 "Speculative" 2 "Confident" 3 "Highly Confident" ;
VAL_ 160 Sig6590 0 "Stopped" 1 "Not Stopped" ;
VAL_ 160 Sig6589 0 "Has Never Moved" 1 "Moving In Same Direction As Host" 2 "Moving In Opposite Direction As Host" 3 "Crossing From Left To Right" 4 "Crossing From Right To Left" ;
VAL_ 160 Sig6592 0 "No Object" 1 "New Object" 2 "Latent Track Not Detected this Cycle" 3 "Measured this Cycle" ;
VAL_ 160 Sig6606 0 "Highly Speculative" 1 "Speculative" 2 "Confident" 3 "Highly Confident" ;
VAL_ 160 Sig6610 0 "Stopped" 1 "Not Stopped" ;
VAL_ 160 Sig6609 0 "Has Never Moved" 1 "Moving In Same Direction As Host" 2 "Moving In Opposite Direction As Host" 3 "Crossing From Left To Right" 4 "Crossing From Right To Left" ;
VAL_ 160 Sig6608 0 "Highly Speculative" 1 "Speculative" 2 "Confident" 3 "Highly Confident" ;
VAL_ 160 Sig6612 0 "No Object" 1 "New Object" 2 "Latent Track Not Detected this Cycle" 3 "Measured this Cycle" ;
VAL_ 160 Sig6626 0 "Highly Speculative" 1 "Speculative" 2 "Confident" 3 "Highly Confident" ;
VAL_ 159 Sig6206 0 "Not Elevated" 1 "Elevation Speculative" 2 "Elevation Confident" 3 "Elevation Very Confident" ;
VAL_ 159 Sig6205 0 "Highly Speculative" 1 "Speculative" 2 "Confident" 3 "Highly Confident" ;
VAL_ 159 Sig6208 0 "No Object" 1 "New Object" 2 "Latent Track Not Detected this Cycle" 3 "Measured this Cycle" ;
VAL_ 159 Sig6212 0 "Highly Speculative" 1 "Speculative" 2 "Confident" 3 "Highly Confident" ;
VAL_ 159 Sig6211 0 "Unknown" 1 "Guard Rail" 2 "Tunnel" 3 "Traffic Sign" 4 "Bridge" 5 "Pole" ;
VAL_ 159 Sig6214 0 "Not Elevated" 1 "Elevation Speculative" 2 "Elevation Confident" 3 "Elevation Very Confident" ;
VAL_ 159 Sig6213 0 "Highly Speculative" 1 "Speculative" 2 "Confident" 3 "Highly Confident" ;
VAL_ 159 Sig6216 0 "No Object" 1 "New Object" 2 "Latent Track Not Detected this Cycle" 3 "Measured this Cycle" ;
VAL_ 159 Sig6221 0 "Highly Speculative" 1 "Speculative" 2 "Confident" 3 "Highly Confident" ;
VAL_ 159 Sig6220 0 "Highly Speculative" 1 "Speculative" 2 "Confident" 3 "Highly Confident" ;
VAL_ 159 Sig6219 0 "Unknown" 1 "Guard Rail" 2 "Tunnel" 3 "Traffic Sign" 4 "Bridge" 5 "Pole" ;
VAL_ 159 Sig6222 0 "Not Elevated" 1 "Elevation Speculative" 2 "Elevation Confident" 3 "Elevation Very Confident" ;
VAL_ 159 Sig6224 0 "No Object" 1 "New Object" 2 "Latent Track Not Detected this Cycle" 3 "Measured this Cycle" ;
VAL_ 159 Sig6227 0 "Unknown" 1 "Guard Rail" 2 "Tunnel" 3 "Traffic Sign" 4 "Bridge" 5 "Pole" ;
VAL_ 159 Sig6230 0 "Not Elevated" 1 "Elevation Speculative" 2 "Elevation Confident" 3 "Elevation Very Confident" ;
VAL_ 159 Sig6229 0 "Highly Speculative" 1 "Speculative" 2 "Confident" 3 "Highly Confident" ;
VAL_ 159 Sig6228 0 "Highly Speculative" 1 "Speculative" 2 "Confident" 3 "Highly Confident" ;
VAL_ 159 Sig6232 0 "No Object" 1 "New Object" 2 "Latent Track Not Detected this Cycle" 3 "Measured this Cycle" ;
VAL_ 159 Sig6236 0 "Highly Speculative" 1 "Speculative" 2 "Confident" 3 "Highly Confident" ;
VAL_ 159 Sig6235 0 "Unknown" 1 "Guard Rail" 2 "Tunnel" 3 "Traffic Sign" 4 "Bridge" 5 "Pole" ;
VAL_ 159 Sig6238 0 "Not Elevated" 1 "Elevation Speculative" 2 "Elevation Confident" 3 "Elevation Very Confident" ;
VAL_ 159 Sig6237 0 "Highly Speculative" 1 "Speculative" 2 "Confident" 3 "Highly Confident" ;
VAL_ 159 Sig6240 0 "No Object" 1 "New Object" 2 "Latent Track Not Detected this Cycle" 3 "Measured this Cycle" ;
VAL_ 159 Sig6246 0 "Not Elevated" 1 "Elevation Speculative" 2 "Elevation Confident" 3 "Elevation Very Confident" ;
VAL_ 159 Sig6245 0 "Highly Speculative" 1 "Speculative" 2 "Confident" 3 "Highly Confident" ;
VAL_ 159 Sig6244 0 "Highly Speculative" 1 "Speculative" 2 "Confident" 3 "Highly Confident" ;
VAL_ 159 Sig6243 0 "Unknown" 1 "Guard Rail" 2 "Tunnel" 3 "Traffic Sign" 4 "Bridge" 5 "Pole" ;
VAL_ 159 Sig6248 0 "No Object" 1 "New Object" 2 "Latent Track Not Detected this Cycle" 3 "Measured this Cycle" ;
VAL_ 159 Sig6251 0 "Unknown" 1 "Guard Rail" 2 "Tunnel" 3 "Traffic Sign" 4 "Bridge" 5 "Pole" ;
VAL_ 159 Sig6254 0 "Not Elevated" 1 "Elevation Speculative" 2 "Elevation Confident" 3 "Elevation Very Confident" ;
VAL_ 159 Sig6253 0 "Highly Speculative" 1 "Speculative" 2 "Confident" 3 "Highly Confident" ;
VAL_ 159 Sig6252 0 "Highly Speculative" 1 "Speculative" 2 "Confident" 3 "Highly Confident" ;
VAL_ 159 Sig6256 0 "No Object" 1 "New Object" 2 "Latent Track Not Detected this Cycle" 3 "Measured this Cycle" ;
VAL_ 159 Sig6261 0 "Highly Speculative" 1 "Speculative" 2 "Confident" 3 "Highly Confident" ;
VAL_ 159 Sig6260 0 "Highly Speculative" 1 "Speculative" 2 "Confident" 3 "Highly Confident" ;
VAL_ 159 Sig6259 0 "Unknown" 1 "Guard Rail" 2 "Tunnel" 3 "Traffic Sign" 4 "Bridge" 5 "Pole" ;
VAL_ 159 Sig6262 0 "Not Elevated" 1 "Elevation Speculative" 2 "Elevation Confident" 3 "Elevation Very Confident" ;
VAL_ 159 Sig6264 0 "No Object" 1 "New Object" 2 "Latent Track Not Detected this Cycle" 3 "Measured this Cycle" ;
VAL_ 159 Sig6267 0 "Unknown" 1 "Guard Rail" 2 "Tunnel" 3 "Traffic Sign" 4 "Bridge" 5 "Pole" ;
VAL_ 159 Sig6270 0 "Not Elevated" 1 "Elevation Speculative" 2 "Elevation Confident" 3 "Elevation Very Confident" ;
VAL_ 159 Sig6269 0 "Highly Speculative" 1 "Speculative" 2 "Confident" 3 "Highly Confident" ;
VAL_ 159 Sig6268 0 "Highly Speculative" 1 "Speculative" 2 "Confident" 3 "Highly Confident" ;
VAL_ 159 Sig6272 0 "No Object" 1 "New Object" 2 "Latent Track Not Detected this Cycle" 3 "Measured this Cycle" ;
VAL_ 159 Sig6276 0 "Highly Speculative" 1 "Speculative" 2 "Confident" 3 "Highly Confident" ;
VAL_ 159 Sig6275 0 "Unknown" 1 "Guard Rail" 2 "Tunnel" 3 "Traffic Sign" 4 "Bridge" 5 "Pole" ;
VAL_ 159 Sig6278 0 "Not Elevated" 1 "Elevation Speculative" 2 "Elevation Confident" 3 "Elevation Very Confident" ;
VAL_ 159 Sig6277 0 "Highly Speculative" 1 "Speculative" 2 "Confident" 3 "Highly Confident" ;
VAL_ 159 Sig6280 0 "No Object" 1 "New Object" 2 "Latent Track Not Detected this Cycle" 3 "Measured this Cycle" ;
VAL_ 159 Sig6284 0 "Highly Speculative" 1 "Speculative" 2 "Confident" 3 "Highly Confident" ;
VAL_ 159 Sig6283 0 "Unknown" 1 "Guard Rail" 2 "Tunnel" 3 "Traffic Sign" 4 "Bridge" 5 "Pole" ;
VAL_ 165 Sig6202 0 "Highly Speculative" 1 "Speculative" 2 "Confident" 3 "Highly Confident" ;
VAL_ 165 Sig6201 0 "FALSE" 1 "TRUE" ;
VAL_ 165 Sig6291 0 "Has Never Moved" 1 "Has Moved But Currently Stopped" 2 "Moving In Same Direction As Host" 3 "Moving In Opposite Direction As Host" 4 "Crossing Path" ;
VAL_ 165 Sig6290 0 "Highly Speculative" 1 "Speculative" 2 "Confident" 3 "Highly Confident" ;
VAL_ 165 Sig6285 0 "Not Radiating" 1 "Reporting Object Data" 2 "Not Reporting Object Data" ;
VAL_ 165 Sig6203 0 "Not Detected" 1 "Detected" 2 "Unknown" ;
VAL_ 165 Sig6294 0 "No Object" 1 "New Object" 2 "Latent Track Not Detected this Cycle" 3 "Measured this Cycle" ;
VAL_ 165 Sig6303 0 "Highly Speculative" 1 "Speculative" 2 "Confident" 3 "Highly Confident" ;
VAL_ 165 Sig6302 0 "Highly Speculative" 1 "Speculative" 2 "Confident" 3 "Highly Confident" ;
VAL_ 165 Sig6301 0 "Unknown" 1 "Pedestrian" 2 "Bicycle" ;
VAL_ 165 Sig6304 0 "Has Never Moved" 1 "Has Moved But Currently Stopped" 2 "Moving In Same Direction As Host" 3 "Moving In Opposite Direction As Host" 4 "Crossing Path" ;
VAL_ 165 Sig6307 0 "No Object" 1 "New Object" 2 "Latent Track Not Detected this Cycle" 3 "Measured this Cycle" ;
VAL_ 165 Sig6315 0 "Highly Speculative" 1 "Speculative" 2 "Confident" 3 "Highly Confident" ;
VAL_ 165 Sig6314 0 "Unknown" 1 "Pedestrian" 2 "Bicycle" ;
VAL_ 165 Sig6387 0 "FALSE" 1 "TRUE" ;
VAL_ 165 Sig6386 0 "FALSE" 1 "TRUE" ;
VAL_ 165 Sig6385 0 "FALSE" 1 "TRUE" ;
VAL_ 165 Sig6383 0 "Highly Speculative" 1 "Speculative" 2 "Confident" 3 "Highly Confident" ;
VAL_ 165 Sig6382 0 "Unknown" 1 "City" 2 "Secondary Road" 3 "Highway" 4 "Construction Zone Entry" 5 "Construction Zone Exit" ;
VAL_ 165 Sig6388 0 "Mode A" 1 "Mode B" 2 "Mode C" 3 "Mode D" ;
VAL_ 165 Sig6450 0 "Stopped" 1 "Not Stopped" ;
VAL_ 165 Sig6449 0 "Has Never Moved" 1 "Moving In Same Direction As Host" 2 "Moving In Opposite Direction As Host" 3 "Crossing From Left To Right" 4 "Crossing From Right To Left" ;
VAL_ 165 Sig6448 0 "Highly Speculative" 1 "Speculative" 2 "Confident" 3 "Highly Confident" ;
VAL_ 165 Sig6452 0 "No Object" 1 "New Object" 2 "Latent Track Not Detected this Cycle" 3 "Measured this Cycle" ;
VAL_ 165 Sig6466 0 "Highly Speculative" 1 "Speculative" 2 "Confident" 3 "Highly Confident" ;
VAL_ 158 Sig6355 0 "Highly Speculative" 1 "Speculative" 2 "Confident" 3 "Highly Confident" ;
VAL_ 158 Sig6363 0 "Highly Speculative" 1 "Speculative" 2 "Confident" 3 "Highly Confident" ;
VAL_ 158 Sig6362 0 "Unknown" 1 "Barriers" 2 "Guard Rails" 3 "Bridge Abutments" 4 "Edge of Road" 5 "Open Area" ;
VAL_ 158 Sig6364 0 "Highly Speculative" 1 "Speculative" 2 "Confident" 3 "Highly Confident" ;
VAL_ 158 Sig6372 0 "Highly Speculative" 1 "Speculative" 2 "Confident" 3 "Highly Confident" ;
VAL_ 158 Sig6371 0 "Unknown" 1 "Barriers" 2 "Guard Rails" 3 "Bridge Abutments" 4 "Edge of Road" 5 "Open Area" ;
VAL_ 158 Sig6373 0 "Highly Speculative" 1 "Speculative" 2 "Confident" 3 "Highly Confident" ;
VAL_ 158 Sig6381 0 "Highly Speculative" 1 "Speculative" 2 "Confident" 3 "Highly Confident" ;
VAL_ 158 Sig6380 0 "Unknown" 1 "Barriers" 2 "Guard Rails" 3 "Bridge Abutments" 4 "Edge of Road" 5 "Open Area" ;
VAL_ 100 EGI1P_PtclFiltClnAlgActAuth_DuD 0 "FALSE" 1 "TRUE" ;
VAL_ 100 EGI1P_PtclFiltClnAlgActAuth 0 "FALSE" 1 "TRUE" ;
VAL_ 100 EGI5P_EngStlSvrActvAuth 0 "FALSE" 1 "TRUE" ;
VAL_ 100 EGI5P_ECDIntlRngSnsrPWAuth_Inv 0 "FALSE" 1 "TRUE" ;
VAL_ 100 EGIP_EngActlStdyStatTrqAuth_Inv 0 "FALSE" 1 "TRUE" ;
VAL_ 100 EGIP_EngNTransRegSSTrqAuth_Inv 0 "FALSE" 1 "TRUE" ;
VAL_ 100 E44BRP_HillDscntCtlSwStsAuth 0 "No Action" 1 "Increment" 2 "Decrement" 3 "Faulted" ;
VAL_ 100 ESP_EngSpdStAuth 0 "Normal_Operation" 1 "Degraded_Operation" 2 "Invalid" ;
VAL_ 100 E49RmtEngStrtReqAuth 0 "PTO Remote Start Not Requested" 1 "PTO Remote Start Requested" ;
VAL_ 100 E49RmtEngShtdnReqdAuth 0 "FALSE" 1 "TRUE" ;
VAL_ 100 EngNonTransRegSSTrqER_Inv 0 "FALSE" 1 "TRUE" ;
VAL_ 157 DMSDrvrDrwLvlCnfdLvl 0 "0" 1 "1" 2 "2" 3 "3" 4 "4" 5 "5" 6 "6" 7 "7" ;
VAL_ 157 DMSDrvrDrwLvl 0 "0" 1 "1" 2 "2" 3 "3" 4 "4" 5 "5" 6 "6" 7 "7" 8 "8" 9 "9" ;
VAL_ 1138 Sig1073 0 "FALSE" 1 "TRUE" ;
VAL_ 1138 Sig1074 0 "FALSE" 1 "TRUE" ;
VAL_ 47 AATP_ActAxlTrqAuth_Inv 0 "FALSE" 1 "TRUE" ;
VAL_ 47 AEPP_AccEffcPosAuth_Inv 0 "FALSE" 1 "TRUE" ;
VAL_ 47 DRCDNDP_DRCAvgDrvnRstOccAuth 0 "FALSE" 1 "TRUE" ;
VAL_ 47 DRCDNDP_DRCAvgDrvnAuth_Inv 0 "FALSE" 1 "TRUE" ;
VAL_ 47 DRCDNDP_DRCAvgDrvnSrcAuth 0 "Transmission Output Speed" 1 "Wheel Speed" ;
VAL_ 47 DRCDNDP_DRCAvgNonDrvnRstOccAuth 0 "FALSE" 1 "TRUE" ;
VAL_ 47 DRCDNDP_DRCAvgNonDrvnAuth_Inv 0 "FALSE" 1 "TRUE" ;
VAL_ 47 DRCDNDP_PwrtrnRunAbrtdAuth 0 "FALSE" 1 "TRUE" ;
VAL_ 47 E44BRP_PTAutoBrkgReqActvAuth 0 "FALSE" 1 "TRUE" ;
VAL_ 47 PBP_PTSndBrkPdlPsAuth_Inv 0 "FALSE" 1 "TRUE" ;
VAL_ 47 PSATDP_ATDstTrqCmdSecAuth_Inv 0 "FALSE" 1 "TRUE" ;
VAL_ 47 PSATIP_ATDstTqCmdPriImmAuth_Inv 0 "FALSE" 1 "TRUE" ;
VAL_ 47 PSATIP_CmndATRespTypAuth 0 "Inactive" 1 "Pleasability Limited Request" 2 "Maximum Range Request" 3 "Automatic Actuator Selection" ;
VAL_ 47 PSATIP_PriATActlAuth_Inv 0 "FALSE" 1 "TRUE" ;
VAL_ 47 PSATIP_PriATReqStsAdvdTracAuth 0 "No Request" 1 "Request Honored" 2 "Lost Arbitration" 3 "Serial Data Failure Temporary" 4 "Serial Data Failure Permanent" 5 "Control System Failure Temporary" 6 "Control System Failure Permanent" ;
VAL_ 47 PSATDP_SecATReqStsAdvdTracAuth 0 "No Request" 1 "Request Honored" 2 "Lost Arbitration" 3 "Serial Data Failure Temporary" 4 "Serial Data Failure Permanent" 5 "Control System Failure Temporary" 6 "Control System Failure Permanent" ;
VAL_ 226 DIATMNP_DrvrIntdAxlTqMnAuth_Inv 0 "FALSE" 1 "TRUE" ;
VAL_ 226 DIATMXP_DrvrIntdAxlTqMxAuth_Inv 0 "FALSE" 1 "TRUE" ;
VAL_ 226 DITP_DrvrIntndAxlTrqAuth_Inv 0 "FALSE" 1 "TRUE" ;
VAL_ 226 VMI1P_AccelPedOvrrdActvAuth 0 "FALSE" 1 "TRUE" ;
VAL_ 226 VMI1P_AccelActlPstnAuth_Inv 0 "FALSE" 1 "TRUE" ;
VAL_ 226 VMI1P_VehTopSpdLimModeActvAuth 0 "FALSE" 1 "TRUE" ;
VAL_ 615 BVSCRP_BdyCtlTpSpdLimRspTypAuth 0 "Inactive" 1 "Faulted" 2 "Safety_woBrake" 3 "Safety_wBrake" 4 "OBD" 5 "nonOBD" 6 "Legislated" ;
VAL_ 615 BVSCRP_ACCAxlTrqCmdReqStsAuth 0 "No Request" 1 "Request Honored" 2 "Lost Arbitration" 3 "Request Denied" 4 "Request Suspended Till Driver Input" ;
VAL_ 615 BVSCRP_ACCAxlTrqCmdLimStsAuth 0 "Request Not Limited" 1 "Request Value Limited Minimum" 2 "Request Value Limited Maximum" 3 "Request Rate Limited" ;
VAL_ 615 BVSCRP_CPSAxlTrqCmdReqStsAuth 0 "No Request" 1 "Request Honored" 2 "Lost Arbitration" 3 "Serial Data Failure Temporary" 4 "Serial Data Failure Permanent" 5 "Control System Failure Temporary" 6 "Control System Failure Permanent" ;
VAL_ 615 BVSCRP_CPSAxlTrqCmdLimStsAuth 0 "Request Not Limited" 1 "Request Value Limited to Minimum" 2 "Request Value Limited to Maximum" 3 "Request Rate Limited" ;
VAL_ 615 CnvntlCruzCtlIndReqAuth 0 "No Action" 1 "Cruise Control Telltale Off" 2 "Cruise Control Unavailable Telltale On" 3 "Cruise Control White Telltale On" 4 "Cruise Control Green Telltale On" 5 "Cruise Control Blue Telltale On" ;
VAL_ 615 BVSCRP_CruzCtlEnbldAuth 0 "FALSE" 1 "TRUE" ;
VAL_ 615 BVSCRP_CltchPdlActPosAuth_Inv 0 "FALSE" 1 "TRUE" ;
VAL_ 615 CruzCtlActvAuth 0 "FALSE" 1 "TRUE" ;
VAL_ 615 DrSeltdSpdLmtrAutoMdSpLmStsAuth 0 "No Set Speed Change" 1 "Proposed Speed Limit Change" 2 "Accepted Speed Limit Change" 3 "Declined Speed Limit Change" ;
VAL_ 615 EGI2P_DrvrReqdAxlTrqIncrAuth 0 "FALSE" 1 "TRUE" ;
VAL_ 615 DrSeltdSpdLmtrSetTypActvAuth 0 "Off" 1 "Manual" 2 "Auto" 3 "Reserved" ;
VAL_ 615 DrSeltdSpdLmtrSetSpdLimRchdAuth 0 "No Limit Reached" 1 "High Limit Reached" 2 "Low Limit Reached" 3 "Reserved" ;
VAL_ 615 E44BRP_VehTopSpdLimArbdStatAuth 0 "Torque" 1 "Torque & Friction Brake" 2 "Inactive" ;
VAL_ 615 EGI2P_PwrtrnCrnkActvAuth 0 "FALSE" 1 "TRUE" ;
VAL_ 615 EGI2P_DrvrReqdAxlTrqValAuth_Inv 0 "FALSE" 1 "TRUE" ;
VAL_ 615 SpdLmtrSpdLimSgnUntAuth 0 "km/h" 1 "mph" ;
VAL_ 615 SuprRmtPrkPrplSysResp 0 "Standby" 1 "Torque Request Honored" 2 "Arbitration Failed" 3 "Failed" ;
VAL_ 879 EGI3P_CnvtTpSpLimRspTypAuth 0 "Inactive" 1 "Faulted" 2 "Safety_woBrake" 3 "Safety_wBrake" 4 "OBD" 5 "nonOBD" 6 "Legislated" ;
VAL_ 879 PSP_PrkNeutSwStatAuth_Inv 0 "FALSE" 1 "TRUE" ;
VAL_ 879 PSP_PrkNeutSwStatAuth 0 "Park/Neutral" 1 "Not Park/Neutral" ;
VAL_ 879 PSP_EngRnngAuth 0 "FALSE" 1 "TRUE" ;
VAL_ 879 PSP_ClchBtmTrvlAchvdAuth_Inv 0 "FALSE" 1 "TRUE" ;
VAL_ 879 PSP_ClchBtmTrvlAchvdAuth 0 "FALSE" 1 "TRUE" ;
VAL_ 879 PSP_VehTheftImbChlgRespStsAuth 0 "Undetermined" 1 "Pass" 2 "Fail" ;
VAL_ 879 PSP_RmtVehStrtEngRnngAuth 0 "FALSE" 1 "TRUE" ;
VAL_ 879 PSP_PwrtrnCrnkAbrtdAuth 0 "FALSE" 1 "TRUE" ;
VAL_ 879 PSP_PrplSysStlActvAuth 0 "FALSE" 1 "TRUE" ;
VAL_ 879 PSP_PrplSysActvAuth 0 "FALSE" 1 "TRUE" ;
VAL_ 879 PrplBrkThrotOvrrdReqd 0 "FALSE" 1 "TRUE" ;
VAL_ 1117 AE44LtSftBtnReq 0 "Hidden" 1 "Disabled" 2 "Enabled" 3 "Highlighted" ;
VAL_ 1117 AE44ExtPrkSftBtnReq 0 "Hidden" 1 "Disabled" 2 "Enabled" 3 "Highlighted" ;
VAL_ 1117 AE44CrsFrtInSftBtnReq 0 "Hidden" 1 "Disabled" 2 "Enabled" 3 "Highlighted" ;
VAL_ 1117 AE44CrsBkInSftBtnReq 0 "Hidden" 1 "Disabled" 2 "Enabled" 3 "Highlighted" ;
VAL_ 1117 AE44SrchingSftBtnReq 0 "Hidden" 1 "Disabled" 2 "Enabled" 3 "Highlighted" ;
VAL_ 1117 AE44RtSftBtnReq 0 "Hidden" 1 "Disabled" 2 "Enabled" 3 "Highlighted" ;
VAL_ 1117 AE44PrllPrkSftBtnReq 0 "Hidden" 1 "Disabled" 2 "Enabled" 3 "Highlighted" ;
VAL_ 1300 VOBP_VehOdoBkupAuth_Inv 0 "FALSE" 1 "TRUE" ;
VAL_ 1313 OATP_OtsAirTmpAuth_Inv 0 "FALSE" 1 "TRUE" ;
VAL_ 1313 OATP_OtsAirTmpSrcAuth 0 "Sensor_Value" 1 "Estimated_Value" ;
VAL_ 1313 OATP_OtsAirTmpCrValStAuth 0 "Normal_Operation" 1 "Degraded_Operation" ;
VAL_ 1313 OATP_OtsAirTmpCrValAuth_Inv 0 "FALSE" 1 "TRUE" ;
VAL_ 616 ETRPP_ElcTransRngPriAuth 0 "NO_REQUEST" 1 "PARK" 2 "REVERSE" 3 "NEUTRAL" 4 "DRIVE" 5 "LOW_RANGE" 6 "MANUAL_RANGE" ;
VAL_ 616 ESAE44CP_ElecShfAE44CtlStsAuth 0 "Stand by" 1 "Shift In Progress" 2 "Manual Override" 3 "Error" ;
VAL_ 616 ESAE44CP_ElecShfAE44CtlStsAtvAut 0 "FALSE" 1 "TRUE" ;
VAL_ 616 HGI1P_SecEngCmptAjrAuth 0 "FALSE" 1 "TRUE" ;
VAL_ 616 E44BRP_ElecShfAutoBrkgReqdAuth 0 "Braking Not Requested" 1 "Braking Requested" ;
VAL_ 616 E44BRP_ElecShfAutoBrkgReqTypAuth 0 "None" 1 "Release" 2 "Hold Allow Driver Release" 3 "Hold Deny Driver Release" ;
VAL_ 616 HGI1P_SecEngCmptAjrAuth_Inv 0 "FALSE" 1 "TRUE" ;
VAL_ 705 LDGI1_ECMClrLgslDiagInfo 0 "FALSE" 1 "TRUE" ;
VAL_ 705 EngWrmUpAch 0 "FALSE" 1 "TRUE" ;
VAL_ 705 EGI4_PrplSysOffTm_Inv 0 "FALSE" 1 "TRUE" ;
VAL_ 705 EGI4_PrplSysOffTm_DuD 0 "FALSE" 1 "TRUE" ;
VAL_ 705 LgslPstDTCClrDrvCyCmp 0 "FALSE" 1 "TRUE" ;
VAL_ 705 LgslDiagMxEngCltTmpRchd 0 "FALSE" 1 "TRUE" ;
VAL_ 705 LDGI1_LgslDiagStdCondsMet 0 "FALSE" 1 "TRUE" ;
VAL_ 705 LDGI1_LgslDiagStdCondsFltPr 0 "FALSE" 1 "TRUE" ;
VAL_ 705 LDGI1_LgslDiagMinEngClTmpRchd 0 "FALSE" 1 "TRUE" ;
VAL_ 705 LDGI1_LgslDiagCldStrtCondsMet 0 "FALSE" 1 "TRUE" ;
VAL_ 705 LDGI1_LgslDiagCldStrtCondsFltPr 0 "FALSE" 1 "TRUE" ;
VAL_ 634 RCIP_PwrRrClsrMtnCmdAuth 0 "No_Action" 1 "Release" 2 "Start Motion" 3 "Stop Motion" ;
VAL_ 634 RCIP_ExtRrClsrRelReqAuth 0 "Unknown" 1 "Inactive" 2 "Active" 3 "Faulted" ;
VAL_ 634 BGI1P_OutsdAmbtLgtLvlStsAuth 0 "Unknown" 1 "Day" 2 "Night" ;
VAL_ 634 BGI1P_DrvrDrOpnStsAuth_Inv 0 "FALSE" 1 "TRUE" ;
VAL_ 634 BGI1P_DrvrDrOpnStsAuth_DuD 0 "FALSE" 1 "TRUE" ;
VAL_ 634 BGI1P_DrvrDrOpnStsAuth 0 "FALSE" 1 "TRUE" ;
VAL_ 634 PwrRrClsrModeSeltn 0 "Disabled" 1 "Fully Open" 2 "Garage" ;
VAL_ 634 RCIP_RrClsrMtnCtlParmEnblAuth 0 "FALSE" 1 "TRUE" ;
VAL_ 634 RCIP_PwrRrClsrMtnReqrAuth 0 "No Request" 1 "Active Remote Keyfob" 2 "Passive Remote Keyfob" 3 "Shutface Switch" 4 "Exterior Switch" 5 "Interior Switch" 6 "Handfree Kick Switch" ;
VAL_ 634 E49RmtStrtMstrEngShtdnReqdAuth 0 "FALSE" 1 "TRUE" ;
VAL_ 634 FrtStrgeCmptExtRelReqAuth 0 "Inactive" 1 "Active" ;
VAL_ 634 FrtStrgeCmptClsrLckSts 0 "Unknown" 1 "Unlocked" 2 "Locked" ;
VAL_ 634 RrStrgModeSwStsAuth 0 "Unknown" 1 "Not Pressed" 2 "Pressed" 3 "Failed" ;
VAL_ 634 PwrFrtStrgeCmptMtnReqrAuth 0 "No Request" 1 "Active Remote Keyfob" 2 "Exterior Switch" 3 "Interior Switch" 4 "Entrapment Switch" ;
VAL_ 634 PwrFrtStrgeCmptMtnCmdAuth 0 "No Action" 1 "Release To Ajar" 2 "Release To Open" 3 "Start Motion" 4 "Stop Motion" ;
VAL_ 634 E49RmtStrtMstrEngStrtReqAuth 0 "PTO Remote Start Not Requested" 1 "PTO Remote Start Requested" ;
VAL_ 72 TGIP_TrnsEgdPrFlwStAuth 0 "Unavailable" 1 "No Powerflow" 2 "Drive Engaged" 3 "Reverse Engaged" ;
VAL_ 72 TARSP_TransActlRngAuth_Inv 0 "FALSE" 1 "TRUE" ;
VAL_ 72 TARSP_TransActlRngAuth_DuD 0 "FALSE" 1 "TRUE" ;
VAL_ 72 TARSP_TransActlRngAuth 0 "Unknown Position" 1 "Park Position" 2 "Between Park and Reverse" 3 "Reverse Position" 4 "Between Reverse and Neutral" 5 "Neutral Position" 6 "Between Neutral and First Drive Position" 7 "First Drive Position" 8 "Between First and Second Drive Position" 9 "Second Drive Position" 10 "Between Second and Third Position" 11 "Third Drive Position" 12 "Between Third and Fourth Position" 13 "Fourth Drive Position" ;
VAL_ 72 TRDP_TrnsPkRgDgLtFltAuth 0 "FALSE" 1 "TRUE" ;
VAL_ 72 TRDP_TrnsPkRgDgCtFltAuth 0 "FALSE" 1 "TRUE" ;
VAL_ 72 TRDP_TrnsNtRgDgLtFltAuth 0 "FALSE" 1 "TRUE" ;
VAL_ 72 TRDP_TrnsNtRgDgCtFltAuth 0 "FALSE" 1 "TRUE" ;
VAL_ 72 TRDP_TrnsFwDrvRDLFltAuth 0 "FALSE" 1 "TRUE" ;
VAL_ 72 TRDP_TrnsFwDrvRDCFltAuth 0 "FALSE" 1 "TRUE" ;
VAL_ 72 TGIP_TrnsEgdPrFlwStAuth_Inv 0 "FALSE" 1 "TRUE" ;
VAL_ 72 TSP_TmpDrvrShfCtlActvAuth 0 "FALSE" 1 "TRUE" ;
VAL_ 72 TSP_ElecRngSeltnInDrvActvAuth 0 "FALSE" 1 "TRUE" ;
VAL_ 72 TRDP_TrnsRvRgDgLtFltAuth 0 "FALSE" 1 "TRUE" ;
VAL_ 72 TRDP_TrnsRvRgDgCtFltAuth 0 "FALSE" 1 "TRUE" ;
VAL_ 101 HVGI3P_HVBNegChsGndVltgAuth_Inv 0 "FALSE" 1 "TRUE" ;
VAL_ 101 HVGI3P_HVBNegChsGndVltgAuth_DuD 0 "FALSE" 1 "TRUE" ;
VAL_ 101 HVGI3P_HVBPosChsGndVltgAuth_Inv 0 "FALSE" 1 "TRUE" ;
VAL_ 101 HVGI3P_HVBPosChsGndVltgAuth_DuD 0 "FALSE" 1 "TRUE" ;
VAL_ 101 HVGI3P_HVPsvIsltnStsAuth 0 "Undetermined" 1 "Passed" 2 "Failed" ;
VAL_ 101 HVGI3P_HVIRatlzdVltgPriAuth_Inv 0 "FALSE" 1 "TRUE" ;
VAL_ 101 HVGI3P_PwrtrnHVShtdnCmpltdAuth 0 "FALSE" 1 "TRUE" ;
VAL_ 101 HVGI3P_PwrtrnHVCntctrReqPriAuth 0 "Undetermined" 1 "Close Allowed" 2 "Request Open" ;
VAL_ 101 PSATDP_SecATActlAuth_Inv 0 "FALSE" 1 "TRUE" ;
VAL_ 101 HVGI9P_ESSPrplSysReqPriAuth 0 "Idle" 1 "Activate" 2 "Deactivate" 3 "ImmedDeactivate" 4 "Suspended" ;
VAL_ 881 ASDRP_LnCntrWrnExtdIndReqAuth 0 "No Indication" 1 "Can Not See Lanes" 2 "Tight Curve" 3 "Freeway Ends" 4 "Construction" 5 "Excessive Speed" 6 "Vehicles Proximity" 7 "Unavailable" 8 "Attention Unknown" 9 "Due to Weather" 10 "Take Steering" 11 "Take Vehicle Control" 12 "Service Driver Assist System" 13 "Lane Following Locked Out" 14 "Reserved 1" 15 "Lane Ending" 16 "Exit Lane" 17 "GM Authority" 18 "Vehicle Setting" 19 "Adaptive Cruise" 20 "Controlled Access" 21 "Driver Attention Off Road" 22 "GPS Unavailable" 23 "Driver Action" 24 "Vehicle Center" 25 "Sensor Impaired" 26 "Opening Left" 27 "Opening Right" 28 "Changing Left" 29 "Changing Right" 30 "Complete Left" 31 "Complete Right" 32 "Unable Left" 33 "Unable Right" 34 "Cancelled Left" 35 "Cancelled Right" 36 "Timed Out Left" 37 "Timed Out Right" 38 "Trailer Narrow Lane" 39 "Trailer Dimensions" 40 "Trailer Braking" 41 "Trailer Overloaded" 42 "Trailer Stability" 43 "Subscription Required" ;
VAL_ 881 ASDRP_LnCntrCtlIndReqAuth 0 "Indication Off" 1 "White Indicator" 2 "Green Indicator" 3 "Yellow Indicator" 4 "Red Indicator" 5 "Blue Indicator" ;
VAL_ 881 ACGIP_SrrndVsnRLSModeCmdAuth 0 "Not Reporting Lane Data" 1 "Reporting Lane Data" ;
VAL_ 881 ACGIP_LnFllwFltIndcdAtBrkEnAuth 0 "FALSE" 1 "TRUE" ;
VAL_ 881 HMIR1P_LnFllwgLHSChEvntStatAuth 0 "No Action" 1 "Active" 2 "Cancel Chime" ;
VAL_ 881 HMIR1P_LnFllwgGenChEvntStatAuth 0 "No Action" 1 "Active" 2 "Cancel Chime" ;
VAL_ 881 ASTIP_LnCntrVehStopdAuth 0 "FALSE" 1 "TRUE" ;
VAL_ 881 HMIR1P_LnFllwgRHSChEvntStatAuth 0 "No Action" 1 "Active" 2 "Cancel Chime" ;
VAL_ 526 ACCATRIP_TrqDrvAstGoStatAuth 0 "Not Stopped" 1 "Apply Accel Pedal to Go" 2 "Apply Accel Pedal or Resume Switch to Go" 3 "Automatic Resume Pending" ;
VAL_ 526 ACCATRIP_TrqActvAuth 0 "FALSE" 1 "TRUE" ;
VAL_ 526 ACCATRIP_TrqTypAuth 0 "Adaptive Cruise Control" 1 "Full Speed Range ACC" 2 "Full Speed Range ACC with Booster" 3 "Full Speed Range ACC with Lane Centering Control" ;
VAL_ 526 ACCBRP_ReqActvAuth 0 "FALSE" 1 "TRUE" ;
VAL_ 526 ACCBRP_ACCActvAuth 0 "FALSE" 1 "TRUE" ;
VAL_ 526 ACCBRP_ReqTypAuth 0 "Unknown" 1 "No_Braking" 2 "Brake_Per_Decel_Request" 3 "Open_Loop_Brake_to_Stop" 4 "Apply_Park_Brake" 5 "Hold" 6 "Prefill Request" ;
VAL_ 526 ClsnImntBrkgAxlTrqRqActvAuth 0 "FALSE" 1 "TRUE" ;
VAL_ 526 LCCPIP_LnCntrCtlActvAuth 0 "FALSE" 1 "TRUE" ;
VAL_ 526 LCCPIP_LnCntrCtlAclPedLimRqAuth 0 "FALSE" 1 "TRUE" ;
